VERSION "HNNBNNNYNNNNNNNNNNNNNNNNNNNNNNNNNNNNNNNNNN/4/%%%/4/'%**4NNN///"

NS_ :

BS_:

BU_: BAP_Tester conBox Gateway Gateway_PAG OTA_FC

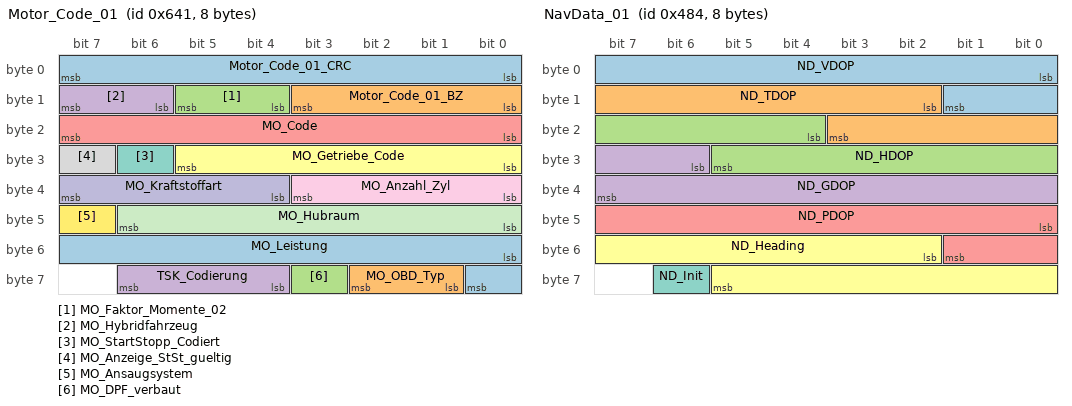
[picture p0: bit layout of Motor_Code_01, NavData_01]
BO_ 1601 Motor_Code_01: 8 Gateway
 SG_ Motor_Code_01_CRC : 0|8@1+ (1,0) [0|255] ""  Vector__XXX
 SG_ Motor_Code_01_BZ : 8|4@1+ (1,0) [0|15] ""  Vector__XXX
 SG_ MO_Faktor_Momente_02 : 12|2@1+ (1,0) [1|3] "Unit_NewtoMeter"  Vector__XXX
 SG_ MO_Hybridfahrzeug : 14|2@1+ (1.0,0.0) [0.0|3] ""  conBox
 SG_ MO_Code : 16|8@1+ (1,0) [0|255] ""  Vector__XXX
 SG_ MO_Getriebe_Code : 24|6@1+ (1.0,0.0) [0.0|63] ""  Vector__XXX
 SG_ MO_StartStopp_Codiert : 30|1@1+ (1.0,0.0) [0.0|1] ""  Vector__XXX
 SG_ MO_Anzeige_StSt_gueltig : 31|1@1+ (1.0,0.0) [0.0|1] ""  Vector__XXX
 SG_ MO_Anzahl_Zyl : 32|4@1+ (1.0,0.0) [0.0|15] ""  Vector__XXX
 SG_ MO_Kraftstoffart : 36|4@1+ (1.0,0.0) [0.0|15] ""  conBox
 SG_ MO_Hubraum : 40|7@1+ (0.1,0) [0.0|12.7] "Unit_Liter"  Vector__XXX
 SG_ MO_Ansaugsystem : 47|1@1+ (1.0,0.0) [0.0|1] ""  Vector__XXX
 SG_ MO_Leistung : 48|9@1+ (1,0) [0|511] "Unit_KiloWatt"  Vector__XXX
 SG_ MO_OBD_Typ : 57|2@1+ (1.0,0.0) [0.0|3] ""  Vector__XXX
 SG_ MO_DPF_verbaut : 59|1@1+ (1.0,0.0) [0.0|1] ""  Vector__XXX
 SG_ TSK_Codierung : 60|3@1+ (1.0,0.0) [0.0|7] ""  Vector__XXX

BO_ 1156 NavData_01: 8 Gateway
 SG_ ND_VDOP : 0|10@1+ (0.025,0) [0.000|25.000] ""  Vector__XXX
 SG_ ND_TDOP : 10|10@1+ (0.025,0) [0.000|25.000] ""  Vector__XXX
 SG_ ND_HDOP : 20|10@1+ (0.025,0) [0.000|25.000] ""  conBox
 SG_ ND_GDOP : 30|10@1+ (0.025,0) [0.000|25.000] ""  Vector__XXX
 SG_ ND_PDOP : 40|10@1+ (0.025,0) [0.000|25.000] ""  Vector__XXX
 SG_ ND_Heading : 50|12@1+ (0.1,0) [0.0|359.9] "Unit_DegreOfArc"  conBox
 SG_ ND_Init : 62|1@1+ (1.0,0.0) [0.0|1] ""  conBox

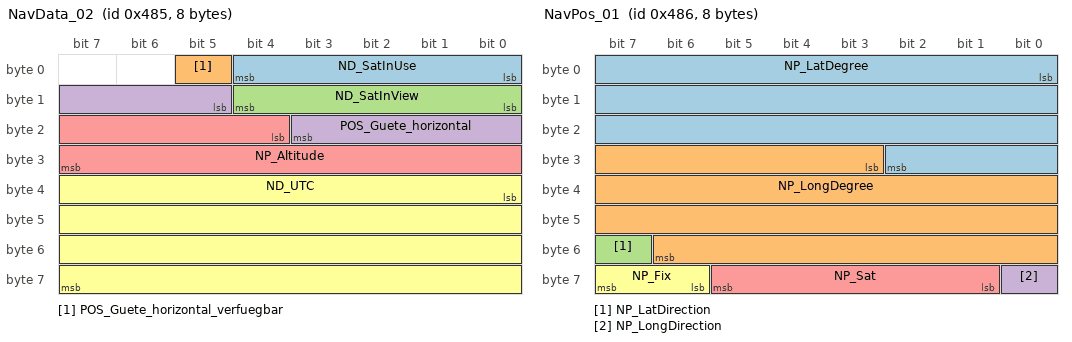
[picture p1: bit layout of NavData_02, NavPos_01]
BO_ 1157 NavData_02: 8 Gateway
 SG_ ND_SatInUse : 0|5@1+ (1,0) [0|29] ""  conBox
 SG_ POS_Guete_horizontal_verfuegbar : 5|1@1+ (1.0,0.0) [0.0|1] ""  conBox
 SG_ ND_SatInView : 8|5@1+ (1,0) [0|29] ""  Vector__XXX
 SG_ POS_Guete_horizontal : 13|7@1+ (2,0) [0|246] "Unit_Meter"  conBox
 SG_ NP_Altitude : 20|12@1+ (2,-500) [-500|7686] "Unit_Meter"  conBox
 SG_ ND_UTC : 32|32@1+ (1,0) [0|4294967293] "Unit_Secon"  conBox

BO_ 1158 NavPos_01: 8 Gateway
 SG_ NP_LatDegree : 0|27@1+ (0.000001,0) [0.000000|90.000000] "Unit_DegreOfArc"  Vector__XXX
 SG_ NP_LongDegree : 27|28@1+ (0.000001,0) [0.000000|180.000000] "Unit_DegreOfArc"  Vector__XXX
 SG_ NP_LatDirection : 55|1@1+ (1.0,0.0) [0.0|1] ""  Vector__XXX
 SG_ NP_LongDirection : 56|1@1+ (1.0,0.0) [0.0|1] ""  Vector__XXX
 SG_ NP_Sat : 57|5@1+ (1,0) [0|29] ""  Vector__XXX
 SG_ NP_Fix : 62|2@1+ (1.0,0.0) [0.0|3] ""  conBox

BO_ 2589283496 NavPos_02_Map_Matched: 8 Gateway
 SG_ POS_MUX M  : 0|2@1+ (1.0,0.0) [0.0|3] ""  conBox
 SG_ POS_ODD_EVEN : 2|1@1+ (1.0,0.0) [0.0|1] ""  conBox
 SG_ POS_PosStati m0  : 3|4@1+ (1.0,0.0) [0.0|15] ""  conBox
 SG_ POS_Heading m1  : 4|12@1+ (0.1,0) [0.0|409.5] "Unit_DegreOfArc"  conBox
 SG_ POS_LatDirection m0  : 7|1@1+ (1.0,0.0) [0.0|1] ""  conBox
 SG_ POS_LatDegree m0  : 8|27@1+ (0.000001,0) [0.000000|90.000000] "Unit_DegreOfArc"  conBox
 SG_ POS_Last_GPS_Sync m1  : 16|14@1+ (1,0) [0|16383] "Unit_Secon"  conBox
 SG_ POS_Heading_Trust m1  : 30|2@1+ (1.0,0.0) [0.0|3] ""  conBox
 SG_ POS_UTC_REF m1  : 32|32@1+ (1,0) [0|4294967295] "Unit_Secon"  conBox
 SG_ POS_LongDirection m0  : 35|1@1+ (1.0,0.0) [0.0|1] ""  conBox
 SG_ POS_LongDegree m0  : 36|28@1+ (0.000001,0) [0.000000|180.000000] "Unit_DegreOfArc"  conBox

BO_ 2600468496 NMH_Gateway: 8 Gateway
 SG_ NM_Gateway_SNI : 0|8@1+ (1.0,0.0) [0.0|255] ""  conBox,OTA_FC
 SG_ NM_Gateway_CBV_AWB : 12|1@1+ (1.0,0.0) [0.0|1] ""  Vector__XXX
 SG_ NM_Gateway_CBV_CRI : 14|1@1+ (1.0,0.0) [0.0|1] ""  conBox,OTA_FC
 SG_ NM_Gateway_NM_State : 16|6@1+ (1.0,0.0) [0.0|63] ""  Vector__XXX
 SG_ NM_Gateway_Car_Wakeup : 22|1@1+ (1.0,0.0) [0.0|1] ""  Vector__XXX
 SG_ NM_Gateway_UDS_CC : 23|1@1+ (1.0,0.0) [0.0|1] ""  Vector__XXX
 SG_ NM_Gateway_NM_aktiv_KL15 : 24|1@1+ (1.0,0.0) [0.0|1] ""  Vector__XXX
 SG_ NM_Gateway_NM_aktiv_Diagnose : 25|1@1+ (1.0,0.0) [0.0|1] ""  Vector__XXX
 SG_ NM_Gateway_NM_aktiv_Tmin : 26|1@1+ (1.0,0.0) [0.0|1] ""  Vector__XXX
 SG_ NM_Gateway_NM_aktiv_CWU : 27|1@1+ (1.0,0.0) [0.0|1] ""  Vector__XXX
 SG_ NM_Gateway_NM_aktiv_FC : 28|1@1+ (1.0,0.0) [0.0|1] ""  Vector__XXX
 SG_ NM_Gateway_NM_aktiv_Connect : 29|1@1+ (1.0,0.0) [0.0|1] ""  Vector__XXX
 SG_ NM_Gateway_NM_aktiv_EM : 30|1@1+ (1.0,0.0) [0.0|1] ""  Vector__XXX
 SG_ NM_Gateway_NM_aktiv_OBDC : 31|1@1+ (1.0,0.0) [0.0|1] ""  Vector__XXX
 SG_ NM_Gateway_NM_aktiv_Buskopplung : 32|1@1+ (1.0,0.0) [0.0|1] ""  Vector__XXX
 SG_ NM_Gateway_NM_aktiv_LIN2 : 33|1@1+ (1.0,0.0) [0.0|1] ""  Vector__XXX
 SG_ NM_Gateway_NM_aktiv_Fremdladung : 34|1@1+ (1.0,0.0) [0.0|1] ""  Vector__XXX
 SG_ NM_Gateway_CAB : 40|24@1+ (1.0,0.0) [0.0|16777215] ""  conBox,OTA_FC

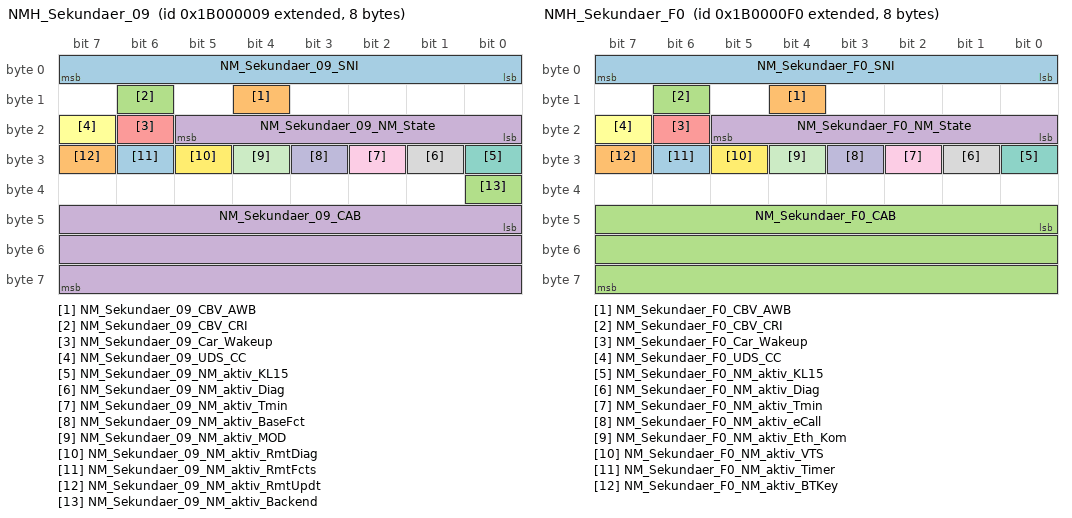
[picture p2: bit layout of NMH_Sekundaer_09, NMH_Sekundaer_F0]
BO_ 2600468489 NMH_Sekundaer_09: 8 OTA_FC
 SG_ NM_Sekundaer_09_SNI : 0|8@1+ (1.0,0.0) [0.0|255] ""  conBox,Gateway,Gateway_PAG
 SG_ NM_Sekundaer_09_CBV_AWB : 12|1@1+ (1.0,0.0) [0.0|1] ""  Vector__XXX
 SG_ NM_Sekundaer_09_CBV_CRI : 14|1@1+ (1.0,0.0) [0.0|1] ""  conBox,Gateway,Gateway_PAG
 SG_ NM_Sekundaer_09_NM_State : 16|6@1+ (1.0,0.0) [0.0|63] ""  Vector__XXX
 SG_ NM_Sekundaer_09_Car_Wakeup : 22|1@1+ (1.0,0.0) [0.0|1] ""  Vector__XXX
 SG_ NM_Sekundaer_09_UDS_CC : 23|1@1+ (1.0,0.0) [0.0|1] ""  Vector__XXX
 SG_ NM_Sekundaer_09_NM_aktiv_KL15 : 24|1@1+ (1.0,0.0) [0.0|1] ""  Vector__XXX
 SG_ NM_Sekundaer_09_NM_aktiv_Diag : 25|1@1+ (1.0,0.0) [0.0|1] ""  Vector__XXX
 SG_ NM_Sekundaer_09_NM_aktiv_Tmin : 26|1@1+ (1.0,0.0) [0.0|1] ""  Vector__XXX
 SG_ NM_Sekundaer_09_NM_aktiv_BaseFct : 27|1@1+ (1.0,0.0) [0.0|1] ""  Vector__XXX
 SG_ NM_Sekundaer_09_NM_aktiv_MOD : 28|1@1+ (1.0,0.0) [0.0|1] ""  Vector__XXX
 SG_ NM_Sekundaer_09_NM_aktiv_RmtDiag : 29|1@1+ (1.0,0.0) [0.0|1] ""  Vector__XXX
 SG_ NM_Sekundaer_09_NM_aktiv_RmtFcts : 30|1@1+ (1.0,0.0) [0.0|1] ""  Vector__XXX
 SG_ NM_Sekundaer_09_NM_aktiv_RmtUpdt : 31|1@1+ (1.0,0.0) [0.0|1] ""  Vector__XXX
 SG_ NM_Sekundaer_09_NM_aktiv_Backend : 32|1@1+ (1.0,0.0) [0.0|1] ""  Vector__XXX
 SG_ NM_Sekundaer_09_CAB : 40|24@1+ (1.0,0.0) [0.0|16777215] ""  conBox,Gateway,Gateway_PAG

BO_ 2600468720 NMH_Sekundaer_F0: 8 conBox
 SG_ NM_Sekundaer_F0_SNI : 0|8@1+ (1.0,0.0) [0.0|255] ""  Gateway,Gateway_PAG,OTA_FC
 SG_ NM_Sekundaer_F0_CBV_AWB : 12|1@1+ (1.0,0.0) [0.0|1] ""  Gateway,Gateway_PAG
 SG_ NM_Sekundaer_F0_CBV_CRI : 14|1@1+ (1.0,0.0) [0.0|1] ""  Gateway,Gateway_PAG,OTA_FC
 SG_ NM_Sekundaer_F0_NM_State : 16|6@1+ (1.0,0.0) [0.0|63] ""  Gateway
 SG_ NM_Sekundaer_F0_Car_Wakeup : 22|1@1+ (1.0,0.0) [0.0|1] ""  Vector__XXX
 SG_ NM_Sekundaer_F0_UDS_CC : 23|1@1+ (1.0,0.0) [0.0|1] ""  Vector__XXX
 SG_ NM_Sekundaer_F0_NM_aktiv_KL15 : 24|1@1+ (1.0,0.0) [0.0|1] ""  Vector__XXX
 SG_ NM_Sekundaer_F0_NM_aktiv_Diag : 25|1@1+ (1.0,0.0) [0.0|1] ""  Vector__XXX
 SG_ NM_Sekundaer_F0_NM_aktiv_Tmin : 26|1@1+ (1.0,0.0) [0.0|1] ""  Vector__XXX
 SG_ NM_Sekundaer_F0_NM_aktiv_eCall : 27|1@1+ (1.0,0.0) [0.0|1] ""  Vector__XXX
 SG_ NM_Sekundaer_F0_NM_aktiv_Eth_Kom : 28|1@1+ (1.0,0.0) [0.0|1] ""  Vector__XXX
 SG_ NM_Sekundaer_F0_NM_aktiv_VTS : 29|1@1+ (1.0,0.0) [0.0|1] ""  Vector__XXX
 SG_ NM_Sekundaer_F0_NM_aktiv_Timer : 30|1@1+ (1.0,0.0) [0.0|1] ""  Vector__XXX
 SG_ NM_Sekundaer_F0_NM_aktiv_BTKey : 31|1@1+ (1.0,0.0) [0.0|1] ""  Vector__XXX
 SG_ NM_Sekundaer_F0_CAB : 40|24@1+ (1.0,0.0) [0.0|16777215] ""  Gateway,Gateway_PAG,OTA_FC

BO_ 1635 NVEM_02: 8 Gateway
 SG_ BEM_02_Abschaltstufen : 0|3@1+ (1.0,0.0) [0.0|7] ""  conBox
 SG_ BEM_STH_Zielzeit : 3|4@1+ (5,0) [0|60] "Unit_Minut"  Vector__XXX
 SG_ BEM_MMI_Vorwarnung : 7|1@1+ (1.0,0.0) [0.0|1] ""  Vector__XXX
 SG_ NVEM_Anf_SD_schalten : 15|1@1+ (1.0,0.0) [0.0|1] ""  Vector__XXX
 SG_ BEM_Generatordiagnose : 16|2@1+ (1.0,0.0) [0.0|3] ""  Vector__XXX
 SG_ BEM_Red_Innengeblaese : 18|2@1+ (1.0,0.0) [0.0|3] ""  Vector__XXX
 SG_ BEM_STH_Einschaltverbot : 20|1@1+ (1.0,0.0) [0.0|1] ""  Vector__XXX
 SG_ BEM_HL_Regelung_Status : 21|3@1+ (1.0,0.0) [0.0|7] ""  Vector__XXX
 SG_ BEM_Ladezustand : 24|4@1+ (10,0) [0|100] "Unit_PerCent"  Vector__XXX
 SG_ BEM_Batteriediagnose : 28|3@1+ (1.0,0.0) [0.0|7] ""  Vector__XXX
 SG_ MIB_Stromsparmodus : 31|1@1+ (1.0,0.0) [0.0|1] ""  Vector__XXX
 SG_ BEM_REK_aktiv : 37|1@1+ (1.0,0.0) [0.0|1] ""  Vector__XXX
 SG_ NVEM_Last_Anf : 38|2@1+ (1.0,0.0) [0.0|3] ""  Vector__XXX
 SG_ BEM_UBDM : 40|8@1+ (0.05,5) [5.05|17.70] "Unit_Volt"  Vector__XXX
 SG_ BEM_UGenSoll : 48|6@1+ (0.1,10.6) [10.6|16.0] "Unit_Volt"  Vector__XXX
 SG_ BEM_Anf_KL15_schalten : 54|2@1+ (1.0,0.0) [0.0|3] ""  Vector__XXX
 SG_ NVEM_Batterie_Service : 56|2@1+ (1.0,0.0) [0.0|3] ""  Vector__XXX
 SG_ NVEM_Freigabe_OnlineUpdate : 58|1@1+ (1.0,0.0) [0.0|1] ""  Vector__XXX
 SG_ NVEM_Freigabe_ORU4 : 59|2@1+ (1.0,0.0) [0.0|3] ""  Vector__XXX

BO_ 2589283656 ORU_01: 8 Gateway
 SG_ ORU_Warnung : 58|2@1+ (1.0,0.0) [0.0|3] ""  Vector__XXX
 SG_ ORU_Status : 61|3@1+ (1.0,0.0) [0.0|7] ""  conBox,OTA_FC

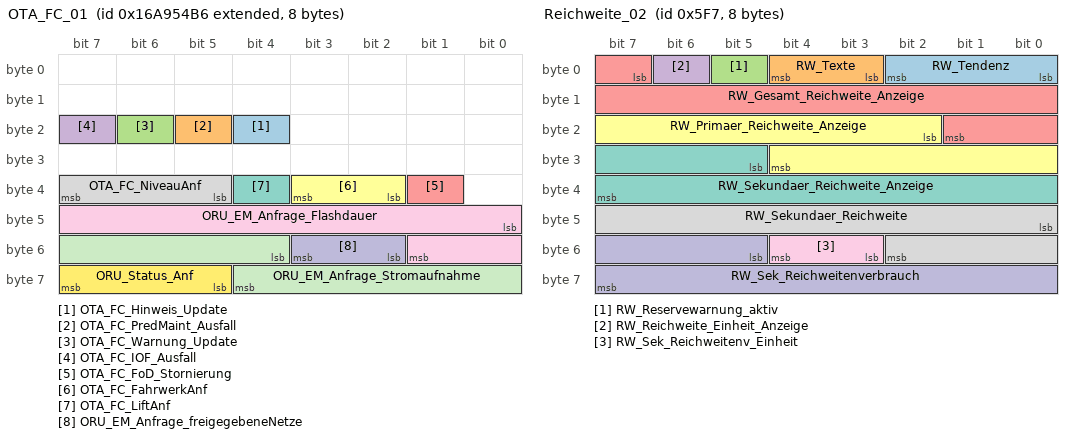
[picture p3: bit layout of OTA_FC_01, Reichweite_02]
BO_ 2527679670 OTA_FC_01: 8 OTA_FC
 SG_ OTA_FC_Hinweis_Update : 20|1@1+ (1.0,0.0) [0.0|1] ""  Gateway,Gateway_PAG
 SG_ OTA_FC_PredMaint_Ausfall : 21|1@1+ (1.0,0.0) [0.0|1] ""  Gateway,Gateway_PAG
 SG_ OTA_FC_Warnung_Update : 22|1@1+ (1.0,0.0) [0.0|1] ""  Gateway,Gateway_PAG
 SG_ OTA_FC_IOF_Ausfall : 23|1@1+ (1.0,0.0) [0.0|1] ""  Gateway,Gateway_PAG
 SG_ OTA_FC_FoD_Stornierung : 33|1@1+ (1.0,0.0) [0.0|1] ""  Gateway,Gateway_PAG
 SG_ OTA_FC_FahrwerkAnf : 34|2@1+ (1.0,0.0) [0.0|3] ""  Gateway,Gateway_PAG
 SG_ OTA_FC_LiftAnf : 36|1@1+ (1.0,0.0) [0.0|1] ""  Gateway,Gateway_PAG
 SG_ OTA_FC_NiveauAnf : 37|3@1+ (1.0,0.0) [0.0|7] ""  Gateway,Gateway_PAG
 SG_ ORU_EM_Anfrage_Flashdauer : 40|10@1+ (10,0) [0|10230] "Unit_Secon"  Gateway,Gateway_PAG
 SG_ ORU_EM_Anfrage_freigegebeneNetze : 50|2@1+ (1.0,0.0) [0.0|3] ""  Gateway,Gateway_PAG
 SG_ ORU_EM_Anfrage_Stromaufnahme : 52|9@1+ (0.1,0) [0.0|51.1] "Unit_Amper"  Gateway,Gateway_PAG
 SG_ ORU_Status_Anf : 61|3@1+ (1.0,0.0) [0.0|7] ""  Gateway,Gateway_PAG

BO_ 2463978757 Personalisierung_04: 8 conBox
 SG_ PSO_last_rec_UserID_Src2 : 60|4@1+ (1.0,0.0) [0.0|15] ""  Gateway,Gateway_PAG

BO_ 1122 PSD_04: 8 Gateway
 SG_ PSD_Segment_ID : 0|6@1+ (1,0) [2|63] ""  Vector__XXX
 SG_ PSD_Vorgaenger_Segment_ID : 6|6@1+ (1,0) [2|63] ""  Vector__XXX
 SG_ PSD_Segmentlaenge : 12|7@1+ (2,0) [0|254] "Unit_Meter"  Vector__XXX
 SG_ PSD_Strassenkategorie : 19|3@1+ (1.0,0.0) [0.0|7] ""  conBox
 SG_ PSD_Endkruemmung : 22|8@1+ (1,0) [0|254] "Unit_None"  Vector__XXX
 SG_ PSD_Endkruemmung_Vorz : 30|1@1+ (1.0,0.0) [0.0|1] ""  Vector__XXX
 SG_ PSD_Idenditaets_ID : 31|6@1+ (1,0) [2|63] ""  Vector__XXX
 SG_ PSD_ADAS_Qualitaet : 37|1@1+ (1.0,0.0) [0.0|1] ""  Vector__XXX
 SG_ PSD_wahrscheinlichster_Pfad : 38|1@1+ (1.0,0.0) [0.0|1] ""  Vector__XXX
 SG_ PSD_Geradester_Pfad : 39|1@1+ (1.0,0.0) [0.0|1] ""  Vector__XXX
 SG_ PSD_Fahrspuren_Anzahl : 40|3@1+ (1.0,0.0) [0.0|7] ""  Vector__XXX
 SG_ PSD_Bebauung : 43|1@1+ (1.0,0.0) [0.0|1] ""  Vector__XXX
 SG_ PSD_Segment_Komplett : 44|1@1+ (1.0,0.0) [0.0|1] ""  Vector__XXX
 SG_ PSD_Rampe : 45|2@1+ (1.0,0.0) [0.0|3] ""  Vector__XXX
 SG_ PSD_Anfangskruemmung : 47|8@1+ (1,0) [0|254] ""  Vector__XXX
 SG_ PSD_Anfangskruemmung_Vorz : 55|1@1+ (1.0,0.0) [0.0|1] ""  Vector__XXX
 SG_ PSD_Abzweigerichtung : 56|1@1+ (1.0,0.0) [0.0|1] ""  Vector__XXX
 SG_ PSD_Abzweigewinkel : 57|7@1+ (1.417323,0) [0.000000|180.000021] ""  Vector__XXX

BO_ 1527 Reichweite_02: 8 Gateway
 SG_ RW_Tendenz : 0|3@1+ (1.0,0.0) [0.0|7] ""  OTA_FC
 SG_ RW_Texte : 3|2@1+ (1.0,0.0) [0.0|3] ""  Vector__XXX
 SG_ RW_Reservewarnung_aktiv : 5|1@1+ (1.0,0.0) [0.0|1] ""  OTA_FC
 SG_ RW_Reichweite_Einheit_Anzeige : 6|1@1+ (1.0,0.0) [0.0|1] ""  conBox
 SG_ RW_Gesamt_Reichweite_Anzeige : 7|11@1+ (1,0) [0|2044] "Unit_None"  conBox,OTA_FC
 SG_ RW_Primaer_Reichweite_Anzeige : 18|11@1+ (1,0) [0|2044] "Unit_None"  conBox,OTA_FC
 SG_ RW_Sekundaer_Reichweite_Anzeige : 29|11@1+ (1,0) [0|2044] "Unit_None"  conBox,OTA_FC
 SG_ RW_Sekundaer_Reichweite : 40|11@1+ (1,0) [0|2044] "Unit_KiloMeter"  conBox,OTA_FC
 SG_ RW_Sek_Reichweitenv_Einheit : 51|2@1+ (1.0,0.0) [0.0|3] ""  Vector__XXX
 SG_ RW_Sek_Reichweitenverbrauch : 53|11@1+ (0.1,0) [0.0|204.4] "Unit_None"  OTA_FC

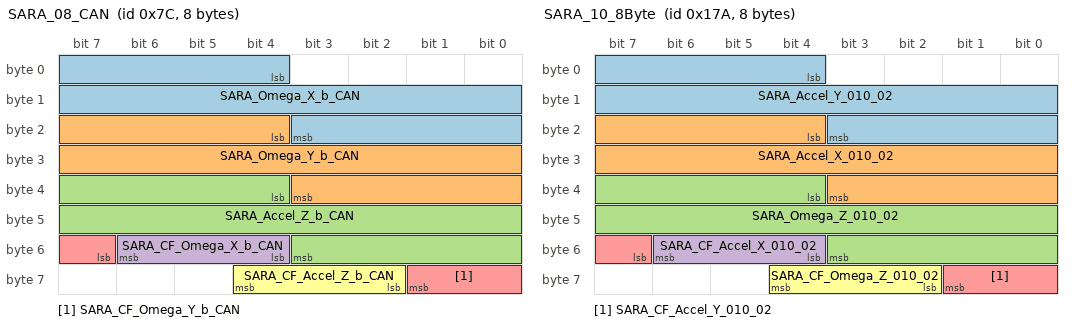
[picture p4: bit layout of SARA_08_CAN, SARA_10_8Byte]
BO_ 124 SARA_08_CAN: 8 Gateway
 SG_ SARA_Omega_X_b_CAN : 4|16@1+ (0.01,-327.68) [-327.67|327.66] "Unit_DegreOfArcPerSecon"  conBox
 SG_ SARA_Omega_Y_b_CAN : 20|16@1+ (0.01,-327.68) [-327.67|327.66] "Unit_DegreOfArcPerSecon"  conBox
 SG_ SARA_Accel_Z_b_CAN : 36|16@1+ (0.02,-655.36) [-655.34|655.32] "Unit_MeterPerSeconSquar"  conBox
 SG_ SARA_CF_Omega_X_b_CAN : 52|3@1+ (1.0,0.0) [0.0|7] ""  Vector__XXX
 SG_ SARA_CF_Omega_Y_b_CAN : 55|3@1+ (1.0,0.0) [0.0|7] ""  Vector__XXX
 SG_ SARA_CF_Accel_Z_b_CAN : 58|3@1+ (1.0,0.0) [0.0|7] ""  conBox

BO_ 378 SARA_10_8Byte: 8 Gateway
 SG_ SARA_Accel_Y_010_02 : 4|16@1+ (0.02,-655.36) [-655.34|655.32] "Unit_MeterPerSeconSquar"  conBox
 SG_ SARA_Accel_X_010_02 : 20|16@1+ (0.02,-655.36) [-655.34|655.32] "Unit_MeterPerSeconSquar"  conBox
 SG_ SARA_Omega_Z_010_02 : 36|16@1+ (0.01,-327.68) [-327.67|327.66] "Unit_DegreOfArcPerSecon"  conBox
 SG_ SARA_CF_Accel_X_010_02 : 52|3@1+ (1.0,0.0) [0.0|7] ""  conBox
 SG_ SARA_CF_Accel_Y_010_02 : 55|3@1+ (1.0,0.0) [0.0|7] ""  conBox
 SG_ SARA_CF_Omega_Z_010_02 : 58|3@1+ (1.0,0.0) [0.0|7] ""  Vector__XXX

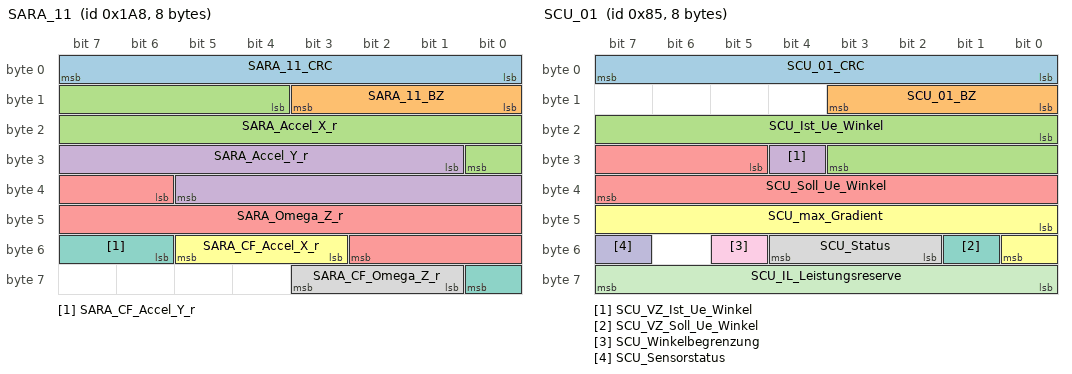
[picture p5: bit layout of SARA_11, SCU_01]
BO_ 424 SARA_11: 8 Gateway
 SG_ SARA_11_CRC : 0|8@1+ (1,0) [0|255] ""  Vector__XXX
 SG_ SARA_11_BZ : 8|4@1+ (1,0) [0|15] ""  Vector__XXX
 SG_ SARA_Accel_X_r : 12|13@1+ (0.16,-655.36) [-655.20|655.04] "Unit_MeterPerSeconSquar"  conBox
 SG_ SARA_Accel_Y_r : 25|13@1+ (0.16,-655.36) [-655.20|655.04] "Unit_MeterPerSeconSquar"  conBox
 SG_ SARA_Omega_Z_r : 38|13@1+ (0.08,-327.68) [-327.60|327.52] "Unit_DegreOfArcPerSecon"  conBox
 SG_ SARA_CF_Accel_X_r : 51|3@1+ (1.0,0.0) [0.0|7] ""  conBox
 SG_ SARA_CF_Accel_Y_r : 54|3@1+ (1.0,0.0) [0.0|7] ""  conBox
 SG_ SARA_CF_Omega_Z_r : 57|3@1+ (1.0,0.0) [0.0|7] ""  conBox

BO_ 133 SCU_01: 8 Gateway
 SG_ SCU_01_CRC : 0|8@1+ (1,0) [0|255] ""  Vector__XXX
 SG_ SCU_01_BZ : 8|4@1+ (1,0) [0|15] ""  Vector__XXX
 SG_ SCU_Ist_Ue_Winkel : 16|12@1+ (0.1,0) [0.0|409.3] "Unit_DegreOfArc"  conBox
 SG_ SCU_VZ_Ist_Ue_Winkel : 28|1@1+ (1.0,0.0) [0.0|1] ""  conBox
 SG_ SCU_Soll_Ue_Winkel : 29|11@1+ (0.1,0) [0.0|204.5] "Unit_DegreOfArc"  Vector__XXX
 SG_ SCU_max_Gradient : 40|9@1+ (1,0) [0|510] ""  Vector__XXX
 SG_ SCU_VZ_Soll_Ue_Winkel : 49|1@1+ (1.0,0.0) [0.0|1] ""  Vector__XXX
 SG_ SCU_Status : 50|3@1+ (1.0,0.0) [0.0|7] ""  Vector__XXX
 SG_ SCU_Winkelbegrenzung : 53|1@1+ (1.0,0.0) [0.0|1] ""  Vector__XXX
 SG_ SCU_Sensorstatus : 55|1@1+ (1.0,0.0) [0.0|1] ""  Vector__XXX
 SG_ SCU_IL_Leistungsreserve : 56|8@1+ (5,0) [0|1265] "Unit_DegreOfArcPerSecon"  Vector__XXX

BO_ 2589283634 SM_LAPP_01: 8 conBox
 SG_ SM_LAPP_Demo_Distanz_01 : 0|8@1+ (2,0) [0|500] "Unit_Meter"  Gateway,Gateway_PAG
 SG_ SM_LAPP_Demo_Distanz_02 : 8|8@1+ (2,0) [0|500] "Unit_Meter"  Gateway,Gateway_PAG
 SG_ SM_LAPP_Demo_Winkel_Vert_01 : 16|8@1+ (0.1,-12.8) [-12.8|12.7] "Unit_DegreOfArc"  Gateway,Gateway_PAG
 SG_ SM_LAPP_Demo_Winkel_Vert_02 : 24|8@1+ (0.1,-12.8) [-12.8|12.7] "Unit_DegreOfArc"  Gateway,Gateway_PAG
 SG_ SM_LAPP_Demo_Winkel_Hor_01 : 32|10@1+ (0.0625,-32) [-32.0000|31.9375] "Unit_DegreOfArc"  Gateway,Gateway_PAG
 SG_ SM_LAPP_Demo_Winkel_Hor_02 : 42|10@1+ (0.0625,-32) [-32.0000|31.9375] "Unit_DegreOfArc"  Gateway,Gateway_PAG
 SG_ SM_LAPP_Demo_Objekt_01_Anf : 52|1@1+ (1.0,0.0) [0.0|1] ""  Gateway,Gateway_PAG
 SG_ SM_LAPP_Demo_Objekt_02_Anf : 53|1@1+ (1.0,0.0) [0.0|1] ""  Gateway,Gateway_PAG
 SG_ SM_LAPP_Demo_Autobahnmodus_Anf : 54|1@1+ (1.0,0.0) [0.0|1] ""  Gateway,Gateway_PAG
 SG_ SM_LAPP_Aussenlicht_aktiv : 55|1@1+ (1.0,0.0) [0.0|1] ""  Gateway,Gateway_PAG
 SG_ SM_LAPP_Verbindungsstatus : 56|1@1+ (1.0,0.0) [0.0|1] ""  Gateway,Gateway_PAG
 SG_ SM_LAPP_Demo_Schildentbl_01_Anf : 57|1@1+ (1.0,0.0) [0.0|1] ""  Gateway,Gateway_PAG
 SG_ SM_LAPP_Demo_Schildentbl_02_Anf : 58|1@1+ (1.0,0.0) [0.0|1] ""  Gateway,Gateway_PAG
 SG_ SM_LAPP_Demo_DKL_Anf : 59|1@1+ (1.0,0.0) [0.0|1] ""  Gateway,Gateway_PAG
 SG_ SM_LAPP_Demo_Einschalteffekt_Anf : 60|1@1+ (1.0,0.0) [0.0|1] ""  Gateway,Gateway_PAG
 SG_ SM_LAPP_Demo_FL_Anf : 61|1@1+ (1.0,0.0) [0.0|1] ""  Gateway,Gateway_PAG
 SG_ SM_LAPP_Demo_MaLi_Anf : 62|1@1+ (1.0,0.0) [0.0|1] ""  Gateway,Gateway_PAG
 SG_ SM_LAPP_Demo_ABBL_Anf : 63|1@1+ (1.0,0.0) [0.0|1] ""  Gateway,Gateway_PAG

BO_ 2527679657 SM_LAPP_02: 8 conBox
 SG_ SM_LAPP_Demo_AbsAss_Anf : 12|1@1+ (1.0,0.0) [0.0|1] ""  Gateway,Gateway_PAG
 SG_ SM_LAPP_Demo_SL_Signatur_Anf : 28|4@1+ (1.0,0.0) [0.0|15] ""  Gateway,Gateway_PAG
 SG_ SM_LAPP_Demo_Variante : 32|4@1+ (1.0,0.0) [0.0|15] ""  Gateway,Gateway_PAG
 SG_ SM_LAPP_Demo_RouLi_Anf : 36|1@1+ (1.0,0.0) [0.0|1] ""  Gateway,Gateway_PAG
 SG_ SM_LAPP_Demo_PreSAss_Anf : 37|1@1+ (1.0,0.0) [0.0|1] ""  Gateway,Gateway_PAG
 SG_ SM_LAPP_Demo_advLH_F01_Anf : 38|1@1+ (1.0,0.0) [0.0|1] ""  Gateway,Gateway_PAG
 SG_ SM_LAPP_Demo_AbbiegeWa_Anf : 39|1@1+ (1.0,0.0) [0.0|1] ""  Gateway,Gateway_PAG
 SG_ SM_LAPP_Demo_CH_H01_Anf : 40|1@1+ (1.0,0.0) [0.0|1] ""  Gateway,Gateway_PAG
 SG_ SM_LAPP_Demo_Stufe : 41|2@1+ (1.0,0.0) [0.0|3] ""  Gateway,Gateway_PAG
 SG_ SM_LAPP_Demo_SL_Anf : 44|1@1+ (1.0,0.0) [0.0|1] ""  Gateway,Gateway_PAG
 SG_ SM_LAPP_Demo_SitLi_Anf : 45|1@1+ (1.0,0.0) [0.0|1] ""  Gateway,Gateway_PAG
 SG_ SM_LAPP_Demo_BauLi_Anf : 46|1@1+ (1.0,0.0) [0.0|1] ""  Gateway,Gateway_PAG
 SG_ SM_LAPP_Demo_advCH_F01_Anf : 47|1@1+ (1.0,0.0) [0.0|1] ""  Gateway,Gateway_PAG
 SG_ SM_LAPP_Demo_LH_F01_Anf : 48|5@1+ (1,0) [1|31] "Unit_None"  Gateway,Gateway_PAG
 SG_ SM_LAPP_Demo_AccAss_Anf : 53|1@1+ (1.0,0.0) [0.0|1] ""  Gateway,Gateway_PAG
 SG_ SM_LAPP_Demo_SpuLi_Anf : 54|1@1+ (1.0,0.0) [0.0|1] ""  Gateway,Gateway_PAG
 SG_ SM_LAPP_Demo_TraLi_Anf : 55|1@1+ (1.0,0.0) [0.0|1] ""  Gateway,Gateway_PAG
 SG_ SM_LAPP_Demo_CH_F01_Anf : 56|5@1+ (1,0) [1|31] "Unit_None"  Gateway,Gateway_PAG
 SG_ SM_LAPP_Demo_LH_H01_Anf : 61|1@1+ (1.0,0.0) [0.0|1] ""  Gateway,Gateway_PAG
 SG_ SM_LAPP_Demo_EffAss_Anf : 62|1@1+ (1.0,0.0) [0.0|1] ""  Gateway,Gateway_PAG
 SG_ SM_LAPP_Demo_BeAss_Anf : 63|1@1+ (1.0,0.0) [0.0|1] ""  Gateway,Gateway_PAG

BO_ 2463978662 STS2_01: 8 Gateway
 SG_ STS2_01_CRC : 0|8@1+ (1,0) [0|255] ""  conBox
 SG_ STS2_01_BZ : 8|4@1+ (1,0) [0|15] ""  conBox
 SG_ STS2_Car_not_under_theft : 12|1@1+ (1.0,0.0) [0.0|1] ""  conBox
 SG_ STS2_Car_under_theft : 13|1@1+ (1.0,0.0) [0.0|1] ""  conBox
 SG_ STS2_Door_Lock : 14|1@1+ (1.0,0.0) [0.0|1] ""  conBox
 SG_ STS2_Anlassersperre : 15|1@1+ (1.0,0.0) [0.0|1] ""  conBox
 SG_ STS2_Typencodierung : 16|5@1+ (1.0,0.0) [0.0|31] ""  conBox
 SG_ STS2_Spiegel_Anklappen : 21|1@1+ (1.0,0.0) [0.0|1] ""  conBox
 SG_ STS2_Privatsphaere : 22|1@1+ (1.0,0.0) [0.0|1] ""  Vector__XXX
 SG_ STS2_Standlicht : 24|1@1+ (1.0,0.0) [0.0|1] ""  conBox
 SG_ STS2_Fahrlicht : 25|1@1+ (1.0,0.0) [0.0|1] ""  conBox
 SG_ STS2_Alarm_still : 26|1@1+ (1.0,0.0) [0.0|1] ""  conBox
 SG_ STS2_Texte : 27|4@1+ (1.0,0.0) [0.0|15] ""  conBox
 SG_ STS2_Laderelais : 38|1@1+ (1.0,0.0) [0.0|1] ""  conBox
 SG_ STS2_Summer : 48|1@1+ (1.0,0.0) [0.0|1] ""  conBox
 SG_ STS2_Alarm_Blinker : 50|1@1+ (1.0,0.0) [0.0|1] ""  conBox
 SG_ STS2_Notstart : 51|1@1+ (1.0,0.0) [0.0|1] ""  conBox
 SG_ STS2_Signalhorn : 55|1@1+ (1.0,0.0) [0.0|1] ""  conBox
 SG_ STS2_Leerlaufschaltung : 56|1@1+ (1.0,0.0) [0.0|1] ""  conBox

BO_ 1172 STS_01: 8 conBox
 SG_ STS_01_CRC : 0|8@1+ (1,0) [0|255] ""  Gateway,Gateway_PAG
 SG_ STS_01_BZ : 8|4@1+ (1,0) [0|15] ""  Gateway,Gateway_PAG
 SG_ STS_Car_not_under_theft : 12|1@1+ (1.0,0.0) [0.0|1] ""  Gateway,Gateway_PAG
 SG_ STS_Car_under_theft : 13|1@1+ (1.0,0.0) [0.0|1] ""  Gateway,Gateway_PAG
 SG_ STS_Door_Lock : 14|1@1+ (1.0,0.0) [0.0|1] ""  Gateway,Gateway_PAG
 SG_ STS_Anlassersperre : 15|1@1+ (1.0,0.0) [0.0|1] ""  Gateway,Gateway_PAG
 SG_ STS_Typencodierung : 16|5@1+ (1.0,0.0) [0.0|31] ""  Gateway,Gateway_PAG
 SG_ STS_Spiegel_Anklappen : 21|1@1+ (1.0,0.0) [0.0|1] ""  Gateway,Gateway_PAG
 SG_ GW_STS2_Privatsphaere : 22|1@1+ (1.0,0.0) [0.0|1] ""  Gateway,Gateway_PAG
 SG_ STS_LIN_aktiv : 23|1@1+ (1.0,0.0) [0.0|1] ""  Gateway,Gateway_PAG
 SG_ STS_Standlicht : 24|1@1+ (1.0,0.0) [0.0|1] ""  Gateway,Gateway_PAG
 SG_ STS_Fahrlicht : 25|1@1+ (1.0,0.0) [0.0|1] ""  Gateway,Gateway_PAG
 SG_ STS_Alarm_still : 26|1@1+ (1.0,0.0) [0.0|1] ""  Gateway,Gateway_PAG
 SG_ STS_Texte : 27|4@1+ (1.0,0.0) [0.0|15] ""  Gateway,Gateway_PAG
 SG_ STS_Laderelais : 38|1@1+ (1.0,0.0) [0.0|1] ""  Gateway,Gateway_PAG
 SG_ STS_Summer : 48|1@1+ (1.0,0.0) [0.0|1] ""  Gateway,Gateway_PAG
 SG_ STS_Alarm_Blinker : 50|1@1+ (1.0,0.0) [0.0|1] ""  Gateway,Gateway_PAG
 SG_ STS_Notstart : 51|1@1+ (1.0,0.0) [0.0|1] ""  Gateway,Gateway_PAG
 SG_ STS_Signalhorn : 55|1@1+ (1.0,0.0) [0.0|1] ""  Gateway,Gateway_PAG
 SG_ STS_Leerlaufschaltung : 56|1@1+ (1.0,0.0) [0.0|1] ""  Gateway,Gateway_PAG

BO_ 1413 Systeminfo_01: 8 Gateway
 SG_ SI_Sammel_SG_Fehler : 0|6@1+ (1,0) [0|60] ""  OTA_FC
 SG_ SI_Diagnose_Aktiv : 7|1@1+ (1.0,0.0) [0.0|1] ""  Vector__XXX
 SG_ SI_QRS_Mode : 8|1@1+ (1.0,0.0) [0.0|1] ""  conBox,OTA_FC
 SG_ SI_T_Mode : 9|1@1+ (1.0,0.0) [0.0|1] ""  conBox,OTA_FC
 SG_ SI_NWDF : 10|1@1+ (1.0,0.0) [0.0|1] ""  conBox,OTA_FC
 SG_ SI_NWDF_gueltig : 11|1@1+ (1.0,0.0) [0.0|1] ""  conBox,OTA_FC
 SG_ SI_Sammelfehler : 12|1@1+ (1.0,0.0) [0.0|1] ""  OTA_FC
 SG_ GW_KD_Fehler : 13|1@1+ (1.0,0.0) [0.0|1] ""  Vector__XXX
 SG_ SI_T_Schutz : 14|1@1+ (1.0,0.0) [0.0|1] ""  conBox,OTA_FC
 SG_ SI_BUS_01 : 16|1@1+ (1.0,0.0) [0.0|1] ""  Vector__XXX
 SG_ SI_BUS_02 : 17|1@1+ (1.0,0.0) [0.0|1] ""  Vector__XXX
 SG_ SI_BUS_03 : 18|1@1+ (1.0,0.0) [0.0|1] ""  conBox
 SG_ SI_BUS_04 : 19|1@1+ (1.0,0.0) [0.0|1] ""  conBox
 SG_ SI_BUS_05 : 20|1@1+ (1.0,0.0) [0.0|1] ""  Vector__XXX
 SG_ SI_BUS_06 : 21|1@1+ (1.0,0.0) [0.0|1] ""  Vector__XXX
 SG_ SI_BUS_07 : 22|1@1+ (1.0,0.0) [0.0|1] ""  Vector__XXX
 SG_ SI_BUS_08 : 23|1@1+ (1.0,0.0) [0.0|1] ""  Vector__XXX
 SG_ SI_BUS_09 : 24|1@1+ (1.0,0.0) [0.0|1] ""  Vector__XXX
 SG_ SI_BUS_10 : 25|1@1+ (1.0,0.0) [0.0|1] ""  conBox
 SG_ SI_BUS_11 : 26|1@1+ (1.0,0.0) [0.0|1] ""  Vector__XXX
 SG_ SI_BUS_12 : 27|1@1+ (1.0,0.0) [0.0|1] ""  conBox
 SG_ SI_BUS_13 : 28|1@1+ (1.0,0.0) [0.0|1] ""  conBox
 SG_ SI_BUS_14 : 29|1@1+ (1.0,0.0) [0.0|1] ""  Vector__XXX
 SG_ SI_BUS_15 : 30|1@1+ (1.0,0.0) [0.0|1] ""  Vector__XXX
 SG_ SI_Bus_Identifikation : 32|8@1+ (1.0,0.0) [0.0|255] ""  OTA_FC
 SG_ SI_CAB : 40|24@1+ (1.0,0.0) [0.0|16777215] ""  OTA_FC

BO_ 1716 VIN_01: 8 Gateway
 SG_ VIN_01_MUX M  : 0|2@1+ (1,0) [0|3] ""  conBox
 SG_ KS_Geheimnis_1 m0  : 8|8@1+ (1,0) [0|255] ""  Vector__XXX
 SG_ VIN_4 m1  : 8|8@1+ (1,0) [0|255] ""  conBox
 SG_ VIN_11 m2  : 8|8@1+ (1,0) [0|255] ""  conBox
 SG_ KS_Geheimnis_2 m0  : 16|8@1+ (1,0) [0|255] ""  Vector__XXX
 SG_ VIN_5 m1  : 16|8@1+ (1,0) [0|255] ""  conBox
 SG_ VIN_12 m2  : 16|8@1+ (1,0) [0|255] ""  conBox
 SG_ KS_Geheimnis_3 m0  : 24|8@1+ (1,0) [0|255] ""  Vector__XXX
 SG_ VIN_6 m1  : 24|8@1+ (1,0) [0|255] ""  conBox
 SG_ VIN_13 m2  : 24|8@1+ (1,0) [0|255] ""  conBox
 SG_ KS_Geheimnis_4 m0  : 32|8@1+ (1,0) [0|255] ""  Vector__XXX
 SG_ VIN_7 m1  : 32|8@1+ (1,0) [0|255] ""  conBox
 SG_ VIN_14 m2  : 32|8@1+ (1,0) [0|255] ""  conBox
 SG_ VIN_1 m0  : 40|8@1+ (1,0) [0|255] ""  conBox
 SG_ VIN_8 m1  : 40|8@1+ (1,0) [0|255] ""  conBox
 SG_ VIN_15 m2  : 40|8@1+ (1,0) [0|255] ""  conBox
 SG_ VIN_2 m0  : 48|8@1+ (1,0) [0|255] ""  conBox
 SG_ VIN_9 m1  : 48|8@1+ (1,0) [0|255] ""  conBox
 SG_ VIN_16 m2  : 48|8@1+ (1,0) [0|255] ""  conBox
 SG_ VIN_3 m0  : 56|8@1+ (1,0) [0|255] ""  conBox
 SG_ VIN_10 m1  : 56|8@1+ (1,0) [0|255] ""  conBox
 SG_ VIN_17 m2  : 56|8@1+ (1,0) [0|255] ""  conBox

BO_ 2617196032 XCP_eCall_CRO_01: 8 Vector__XXX
 SG_ XCP_eCall_CRO_01_Data : 0|64@1+ (1,0) [0|1] ""  conBox

BO_ 2617196033 XCP_eCall_DTO_01: 8 conBox
 SG_ XCP_eCall_DTO_01_Data : 0|64@1+ (1,0) [0|1] ""  Vector__XXX

BO_ 2616997632 XCP_OTA_FC_CRO_01: 8 Vector__XXX
 SG_ XCP_OTA_FC_CRO_01_Data : 0|64@1+ (1,0) [0|1] ""  OTA_FC

BO_ 2616997633 XCP_OTA_FC_DTO_01: 8 OTA_FC
 SG_ XCP_OTA_FC_DTO_01_Data : 0|64@1+ (1,0) [0|1] ""  Vector__XXX

BO_ 1411 ZV_02: 8 Gateway
 SG_ BCM_FH_Freigabe : 12|1@1+ (1.0,0.0) [0.0|1] ""  Vector__XXX
 SG_ BCM_Komfortfkt_Freigabe : 13|1@1+ (1.0,0.0) [0.0|1] ""  Vector__XXX
 SG_ BCM_HSK_Freigabe : 14|1@1+ (1.0,0.0) [0.0|1] ""  Vector__XXX
 SG_ BCM_Verdeck_Freigabe : 15|1@1+ (1.0,0.0) [0.0|1] ""  Vector__XXX
 SG_ ZV_verriegelt_intern_ist : 16|1@1+ (1.0,0.0) [0.0|1] ""  Vector__XXX
 SG_ ZV_verriegelt_extern_ist : 17|1@1+ (1.0,0.0) [0.0|1] ""  Vector__XXX
 SG_ ZV_verriegelt_intern_soll : 18|1@1+ (1.0,0.0) [0.0|1] ""  Vector__XXX
 SG_ ZV_verriegelt_extern_soll : 19|1@1+ (1.0,0.0) [0.0|1] ""  Vector__XXX
 SG_ ZV_gesafet_extern_ist : 20|1@1+ (1.0,0.0) [0.0|1] ""  Vector__XXX
 SG_ ZV_gesafet_extern_soll : 21|1@1+ (1.0,0.0) [0.0|1] ""  Vector__XXX
 SG_ ZV_Einzeltuerentriegelung : 22|1@1+ (1.0,0.0) [0.0|1] ""  Vector__XXX
 SG_ ZV_Heckeinzelentriegelung : 23|1@1+ (1.0,0.0) [0.0|1] ""  Vector__XXX
 SG_ ZV_FT_offen : 24|1@1+ (1.0,0.0) [0.0|1] ""  Vector__XXX
 SG_ ZV_BT_offen : 25|1@1+ (1.0,0.0) [0.0|1] ""  Vector__XXX
 SG_ ZV_HFS_offen : 26|1@1+ (1.0,0.0) [0.0|1] ""  Vector__XXX
 SG_ ZV_HBFS_offen : 27|1@1+ (1.0,0.0) [0.0|1] ""  Vector__XXX
 SG_ ZV_HD_offen : 28|1@1+ (1.0,0.0) [0.0|1] ""  Vector__XXX
 SG_ ZV_HS_offen : 29|1@1+ (1.0,0.0) [0.0|1] ""  Vector__XXX
 SG_ IRUE_aktiv : 30|1@1+ (1.0,0.0) [0.0|1] ""  Vector__XXX
 SG_ DWA_aktiv : 31|1@1+ (1.0,0.0) [0.0|1] ""  conBox
 SG_ HD_Hauptraste : 32|1@1+ (1.0,0.0) [0.0|1] ""  Vector__XXX
 SG_ HD_Vorraste : 33|1@1+ (1.0,0.0) [0.0|1] ""  Vector__XXX
 SG_ FFB_CarFinder : 38|1@1+ (1.0,0.0) [0.0|1] ""  Vector__XXX
 SG_ FFB_Komfortoeffnen : 39|1@1+ (1.0,0.0) [0.0|1] ""  Vector__XXX
 SG_ FFB_Komfortschliessen : 40|1@1+ (1.0,0.0) [0.0|1] ""  Vector__XXX
 SG_ ZV_Schluessel_Zugang : 42|4@1+ (1.0,0.0) [0.0|15] ""  Vector__XXX
 SG_ ZV_SafeFunktion_aktiv : 46|1@1+ (1.0,0.0) [0.0|1] ""  Vector__XXX
 SG_ FBS_Warn_Schluessel_Batt : 47|1@1+ (1.0,0.0) [0.0|1] ""  Vector__XXX
 SG_ ZV_Oeffnungsmodus : 48|2@1+ (1.0,0.0) [0.0|3] ""  Vector__XXX
 SG_ HFS_verriegelt : 50|1@1+ (1.0,0.0) [0.0|1] ""  Vector__XXX
 SG_ HFS_gesafet : 51|1@1+ (1.0,0.0) [0.0|1] ""  Vector__XXX
 SG_ HBFS_verriegelt : 52|1@1+ (1.0,0.0) [0.0|1] ""  Vector__XXX
 SG_ HBFS_gesafet : 53|1@1+ (1.0,0.0) [0.0|1] ""  Vector__XXX
 SG_ ZV_ist_Zustand_verfuegbar : 54|1@1+ (1.0,0.0) [0.0|1] ""  Vector__XXX
 SG_ IRUE_Taster_Fkts_LED : 55|1@1+ (1.0,0.0) [0.0|1] ""  Vector__XXX
 SG_ ZV_Tankklappe_offen : 56|1@1+ (1.0,0.0) [0.0|1] ""  Vector__XXX
 SG_ ZV_Rollo_auf : 57|1@1+ (1.0,0.0) [0.0|1] ""  Vector__XXX
 SG_ ZV_Rollo_zu : 58|1@1+ (1.0,0.0) [0.0|1] ""  Vector__XXX
 SG_ ZV_SAD_auf : 59|1@1+ (1.0,0.0) [0.0|1] ""  Vector__XXX
 SG_ ZV_SAD_zu : 60|1@1+ (1.0,0.0) [0.0|1] ""  Vector__XXX
 SG_ BCM_Tankklappensteller_Fehler : 61|1@1+ (1.0,0.0) [0.0|1] ""  Vector__XXX
 SG_ ZV_verriegelt_soll : 62|2@1+ (1.0,0.0) [0.0|3] ""  Vector__XXX

BO_TX_BU_ 1601 :Gateway,Gateway_PAG;
BO_TX_BU_ 1156 :Gateway,Gateway_PAG;
BO_TX_BU_ 1157 :Gateway,Gateway_PAG;
BO_TX_BU_ 1158 :Gateway,Gateway_PAG;
BO_TX_BU_ 2589283496 :Gateway,Gateway_PAG;
BO_TX_BU_ 2600468496 :Gateway,Gateway_PAG;
BO_TX_BU_ 1635 :Gateway,Gateway_PAG;
BO_TX_BU_ 2589283656 :Gateway,Gateway_PAG;
BO_TX_BU_ 1122 :Gateway,Gateway_PAG;
BO_TX_BU_ 1527 :Gateway,Gateway_PAG;
BO_TX_BU_ 124 :Gateway,Gateway_PAG;
BO_TX_BU_ 378 :Gateway,Gateway_PAG;
BO_TX_BU_ 424 :Gateway,Gateway_PAG;
BO_TX_BU_ 133 :Gateway,Gateway_PAG;
BO_TX_BU_ 2463978662 :Gateway,Gateway_PAG;
BO_TX_BU_ 1413 :Gateway,Gateway_PAG;
BO_TX_BU_ 1716 :Gateway,Gateway_PAG;
BO_TX_BU_ 1411 :Gateway,Gateway_PAG;
CM_ BO_ 1601 "ab MQB mit CRC-8";
CM_ BO_ 1635 "DLC=8 ab D4 gültig";
CM_ BO_ 424 "CAN-Botschaft";
CM_ BO_ 1413 "MQB, MLBevo";
CM_ BO_ 1716 "200ms bei D4 und folgende";

CM_ SG_ 1601 MO_Ansaugsystem "Art des Ansaugsystems des Verbrennungsmotors";
CM_ SG_ 1601 MO_Anzahl_Zyl "Zylinderzahl des Verbrennungsmotors";
CM_ SG_ 1601 MO_Anzeige_StSt_gueltig "Zeigt die Gültigkeit der neuen StSt-Anzeigesignale an, MO_Anzeige_StSt_Text und  MO_Anzeige_Symbol. Mo_Text_Motorstart 1..5 sind zu ignorieren.";
CM_ SG_ 1601 MO_Code "Motorcodierinformation Version 16 (Details siehe Anhang)";
CM_ SG_ 1601 MO_DPF_verbaut "Verbauinformation Diesel-Partikel-Filter
";
CM_ SG_ 1601 MO_Faktor_Momente_02 "Dieses Signal schaltet den Wertebereich aller Momente vom Motor, Getriebe, TSK, Bremse ... um! Die Momente besitzen somit einen variablen Wertebereich, weil sich durch den Faktor die Momente sowohl in Auflösung als auch Maximalwerten ändert.

0x0 nicht ";
CM_ SG_ 1601 MO_Getriebe_Code "Getriebecodierung des Motors";
CM_ SG_ 1601 MO_Hubraum "Hubraum des Verbrennungsmotors";
CM_ SG_ 1601 MO_Hybridfahrzeug "Anhand dieses Signals plausibilisiert die Lenkhilfe das Bit Fahrbereitschaft.

Im Projekt Cayenne PHEV (und ggf. auch VW526 PHEV) ist aus Gründen der Abwärtskompatibilität der Wert '2' zu senden.";
CM_ SG_ 1601 MO_Kraftstoffart "Primärkraftstoff zum Antrieb des Fahrzeugs";
CM_ SG_ 1601 MO_Leistung "Nennleistung des Verbrennungsmotors

Im reinen E-Fahrzeug (BEV): Ausgabe der elektrischen Systemleistung";
CM_ SG_ 1601 MO_OBD_Typ "Abgastyp OBD
Hinweis: In Fahrzeugen mit dem Zielmarkt China und einer Zertifizierung ab China 6 muss auf dem Signal 'MO_OBD_Typ' der Wert 'US_OBD' gesendet werden.";
CM_ SG_ 1601 MO_StartStopp_Codiert "Funktion StartStopp im aktuellen Klemmenzyklus verbaut";
CM_ SG_ 1601 Motor_Code_01_CRC "Für MLB:
'Berechnung siehe Lastenheft 'Kommunikationsabsicherung für FlexRay und CAN''

Ab MQB und MLBevo:
'Berechnung siehe Lastenheft 'End-to-End Kommunikationsabsicherung''

Endwerte siehe Begleitdokument 'S-PDU Kennungsfolgen'";
CM_ SG_ 1601 TSK_Codierung "Information über den plausibilisierten Codierungszustand des Triebstrangskoordinators auf ACC oder GRA.";

CM_ SG_ 1156 ND_GDOP "geometric dilution of precision (Gesamtgenauigkeit, 3D und Zeit) 
";
CM_ SG_ 1156 ND_HDOP "horizontal dilution of precision (Horizontalrichtung, 2D)
";
CM_ SG_ 1156 ND_Heading "Fahrtrichtung";
CM_ SG_ 1156 ND_Init "Initialisierung";
CM_ SG_ 1156 ND_PDOP "positional dilution of precision (Positionsgenauigkeit, 3D) 
";
CM_ SG_ 1156 ND_TDOP "time dilution of precision (Zeitgenauigkeit)
";
CM_ SG_ 1156 ND_VDOP "vertical dilution of precision (Vertikalrichtung, 1D)
";

CM_ SG_ 1157 ND_SatInUse "Anzahl der zur Berechnung verwendeten Satelliten";
CM_ SG_ 1157 ND_SatInView "Anzahl der sichtbaren Satelliten";
CM_ SG_ 1157 ND_UTC "UTC-Zeit, verstrichene Sekunden seit 01.01.1970 00:00
0xFFFFFFFE = Init
0xFFFFFFFF = Fehler bei Berechnung der UTC-Time";
CM_ SG_ 1157 NP_Altitude "Hoehe ueber NN
0xFFF = Fehler bei der Berechnung der Höhe über NN";
CM_ SG_ 1157 POS_Guete_horizontal "Horizontale Genauigkeit der Position in der Botschaft NavPos_02_MapMatched (Signale
POS_LatDegree, POS_LongDegree)

Abhängig vom Signal
POS_Guete_horizontal_verfuegbar";
CM_ SG_ 1157 POS_Guete_horizontal_verfuegbar "Bei gesetztem Bit wird das Signal POS_Guete_horizontal befüllt und ist verfügbar.";

CM_ SG_ 1158 NP_LatDegree "Latitude (Nord-Süd Wert)";
CM_ SG_ 1158 NP_LatDirection "Hemisphäre Nord/Süd";
CM_ SG_ 1158 NP_LongDegree "Longitude (Ost-West Wert)";
CM_ SG_ 1158 NP_LongDirection "Hemisphäre Ost/West";
CM_ SG_ 1158 NP_Sat "Nummer der verwendeten Sateliten beim letzten Fix";

CM_ SG_ 2589283496 POS_Heading "Heading of current position
MUX(1)";
CM_ SG_ 2589283496 POS_Heading_Trust "Vertrauenswert Heading 
MUX(1) ";
CM_ SG_ 2589283496 POS_Last_GPS_Sync "Letztes bekannte GPS Sync in [s]
MUX(1)";
CM_ SG_ 2589283496 POS_LatDegree "latitude - position data of navigation
MUX(0)";
CM_ SG_ 2589283496 POS_LatDirection "latitude direction nav position
MUX(0)";
CM_ SG_ 2589283496 POS_LongDegree "long - position data of navigation
MUX(0)";
CM_ SG_ 2589283496 POS_LongDirection "longitude direction nav position
MUX(0)";
CM_ SG_ 2589283496 POS_MUX "Multiplex-Signal zum schalten des Signals der Positionen von der Navigation.
MUX(0/1)";
CM_ SG_ 2589283496 POS_ODD_EVEN "Synchronisation der MUX Pos Signale
MUX(0/1)";
CM_ SG_ 2589283496 POS_PosStati "Aktueller Status der Navgation:
MUX(0)
0   init
1   no nav available (ready_4_nav)
2   no map available (sd_removed, not_enabled)
3   nav booting
4   nav error
5   nav calibrating
6   nav no gps resync since 1h
7   nav offroad  parkgarage ramp of";
CM_ SG_ 2589283496 POS_UTC_REF "Zeitstempel der Nav
MUX(1)

UTC-Zeit, verstrichene Sekunden seit 01.01.1970 00:00
0xFFFFFFFE = Init
0xFFFFFFFF = Fehler bei Berechnung der UTC-Time

Signal wird nur bei aktiver Navigation-Funktion zyklisch gesendet.";

CM_ SG_ 2600468496 NM_Gateway_CAB "CAB = Clusteraktivbits";
CM_ SG_ 2600468496 NM_Gateway_Car_Wakeup "Car Wakeup (Subbusmaster wertet aus)

MQB: 
-Diagnose- oder Komponentenschutzmaster-Funktion weckt den schlafenden Subbus (z.B. MOST)

E3_Volumen:
- Diagnose aktiv -aktive Diagnosekommunikation am OBD-Stecker

MQBw_Baseline:
- Diagnose aktiv -akt";
CM_ SG_ 2600468496 NM_Gateway_CBV_AWB "Das Signal ist zu setzen, wenn das SG aktiv den Bus geweckt hat
0 = Passiver_WakeUp = SG hat das Netzwerk nicht aktiv geweckt
1 = Akitiver_WakeUp = SG hat das Netzwerk aktiv geweckt";
CM_ SG_ 2600468496 NM_Gateway_CBV_CRI "Das Signal ist dauerhaft gesetzt, wenn das NM-Layout Cluster- Anforderungen enthält";
CM_ SG_ 2600468496 NM_Gateway_NM_aktiv_Buskopplung "Nachlauf aufgrund Kopplung zweier Busse. z.B. K-CAN und K2-CAN";
CM_ SG_ 2600468496 NM_Gateway_NM_aktiv_Connect "Nachlauf aufgrund Connect";
CM_ SG_ 2600468496 NM_Gateway_NM_aktiv_CWU "Nachlauf aufgrund CWU Anforderung";
CM_ SG_ 2600468496 NM_Gateway_NM_aktiv_Diagnose "Diagnose befindet sich nach VW80124 in einer NonDefaultDiagnostic-Session, z.B. ExtendedDiagnostic-Session";
CM_ SG_ 2600468496 NM_Gateway_NM_aktiv_EM "Nachlauf aufgrund Energiemanagement";
CM_ SG_ 2600468496 NM_Gateway_NM_aktiv_FC "Nachlauf aufgrund Funktionscluster Anforderung";
CM_ SG_ 2600468496 NM_Gateway_NM_aktiv_Fremdladung "Nachlauf aufgrund Fremdladung";
CM_ SG_ 2600468496 NM_Gateway_NM_aktiv_KL15 "Steuergerät hat KL15-EIN erkannt";
CM_ SG_ 2600468496 NM_Gateway_NM_aktiv_LIN2 "Bus aktiv aufgrund aktivem LIN2 (Hupe betätigt)";
CM_ SG_ 2600468496 NM_Gateway_NM_aktiv_OBDC "Nachlauf aufgrund OBDC";
CM_ SG_ 2600468496 NM_Gateway_NM_aktiv_Tmin "Mindestaktivzeit ist noch nicht abgelaufen (bei jedem Weckereignis wird die Mindestaktivzeit neu gestartet)";
CM_ SG_ 2600468496 NM_Gateway_NM_State "1 = Zustand Repeat Message (<-- Bus-Sleep Mode)
2 = Zustand Repeat Message (<-- Prepare Bus-Sleep Mode)
4 = Zustand Normal Operation (<-- Repeat Message)
8 = Zustand Normal Operation (<-- Ready Sleep)";
CM_ SG_ 2600468496 NM_Gateway_SNI "Source Node-Identifier (SNI) identifiziert den Sender der NM-Botschaft (Knotenadresse) eindeutig im Fahrzeug";
CM_ SG_ 2600468496 NM_Gateway_UDS_CC "Funktionseinschränkung aufgrund aktivem UDS-Communication Control, siehe VW80124";

CM_ SG_ 2600468489 NM_Sekundaer_09_CAB "CAB = Clusteraktivbits";
CM_ SG_ 2600468489 NM_Sekundaer_09_Car_Wakeup "Car Wakeup (Gateway wertet aus)

MQB:
aktuell kein Car Wakeup Grund seitens FCM";
CM_ SG_ 2600468489 NM_Sekundaer_09_CBV_AWB "Das Signal ist zu setzen, wenn das SG aktiv den Bus geweckt hat";
CM_ SG_ 2600468489 NM_Sekundaer_09_CBV_CRI "Das Signal ist dauerhaft gesetzt, wenn das NM-Layout dem neuen NM-Layout für Teilnetzbetrieb entspricht";
CM_ SG_ 2600468489 NM_Sekundaer_09_NM_aktiv_Backend "Kommunikation mit Backend aktiv";
CM_ SG_ 2600468489 NM_Sekundaer_09_NM_aktiv_BaseFct "Kommunikation mit Backend aktiv";
CM_ SG_ 2600468489 NM_Sekundaer_09_NM_aktiv_Diag "Diagnose befindet sich nach VW80124 in einer NonDefaultDiagnostic-Session, z.B. ExtendedDiagnostic-Session";
CM_ SG_ 2600468489 NM_Sekundaer_09_NM_aktiv_KL15 "Steuergerät hat KL15-EIN erkannt";
CM_ SG_ 2600468489 NM_Sekundaer_09_NM_aktiv_MOD "MOD fordert Buskommunikation";
CM_ SG_ 2600468489 NM_Sekundaer_09_NM_aktiv_RmtDiag "RemoteDiagnose fordert Buskommunikation";
CM_ SG_ 2600468489 NM_Sekundaer_09_NM_aktiv_RmtFcts "RemoteFunction fordert Buskommunikation";
CM_ SG_ 2600468489 NM_Sekundaer_09_NM_aktiv_RmtUpdt "RemoteUpdate fordert Buskommunikation";
CM_ SG_ 2600468489 NM_Sekundaer_09_NM_aktiv_Tmin "Mindestaktivzeit ist noch nicht abgelaufen (bei jedem Weckereignis wird die Mindestaktivzeit neu gestartet)";
CM_ SG_ 2600468489 NM_Sekundaer_09_NM_State "1 = Zustand Repeat Message (<-- Bus-Sleep Mode)
2 = Zustand Repeat Message (<-- Prepare Bus-Sleep Mode)
4 = Zustand Normal Operation (<-- Repeat Message)
8 = Zustand Normal Operation (<-- Ready Sleep)";
CM_ SG_ 2600468489 NM_Sekundaer_09_SNI "Source Node-Identifier (SNI) identifiziert den Sender der NM-Botschaft (Knotenadresse) eindeutig im Fahrzeug";
CM_ SG_ 2600468489 NM_Sekundaer_09_UDS_CC "Funktionseinschränkung aufgrund aktivem UDS-Communication Control; siehe VW80124";

CM_ SG_ 2600468720 NM_Sekundaer_F0_CAB "CAB = Clusteraktivbits";
CM_ SG_ 2600468720 NM_Sekundaer_F0_Car_Wakeup "Car Wakeup (Gateway wertet aus)";
CM_ SG_ 2600468720 NM_Sekundaer_F0_CBV_AWB "Das Signal ist zu setzen, wenn das SG aktiv den Bus geweckt hat";
CM_ SG_ 2600468720 NM_Sekundaer_F0_CBV_CRI "Das Signal ist dauerhaft gesetzt, wenn das NM-Layout dem neuen NM-Layout für Teilnetzbetrieb entspricht";
CM_ SG_ 2600468720 NM_Sekundaer_F0_NM_aktiv_BTKey "Steuergerät hat gültigen Schlüssel über Bluetooth empfangen";
CM_ SG_ 2600468720 NM_Sekundaer_F0_NM_aktiv_Diag "Diagnose befindet sich nach VW80124 in einer NonDefaultDiagnostic-Session, z.B. ExtendedDiagnostic-Session";
CM_ SG_ 2600468720 NM_Sekundaer_F0_NM_aktiv_eCall "Waehrend aktivem eCALL muss der CAN für die BAP-Strecke wachgehalten werden";
CM_ SG_ 2600468720 NM_Sekundaer_F0_NM_aktiv_Eth_Kom "Nach einem Wakeup über Backend muss der CAN so lange wachgehalten werden, bis eine stabile Ethernetverbindung (inkl. SOME/IP etc.) etabliert ist.";
CM_ SG_ 2600468720 NM_Sekundaer_F0_NM_aktiv_KL15 "Steuergerät hat KL15-EIN erkannt";
CM_ SG_ 2600468720 NM_Sekundaer_F0_NM_aktiv_Timer "Beim Aendern eines Timerwertes in der ConBox muss dies dem Gateway mitgeteilt werden.";
CM_ SG_ 2600468720 NM_Sekundaer_F0_NM_aktiv_Tmin "Mindestaktivzeit ist noch nicht abgelaufen (bei jedem Weckereignis wird die Mindestaktivzeit neu gestartet)";
CM_ SG_ 2600468720 NM_Sekundaer_F0_NM_aktiv_VTS "Bei aktiver VTS muss der Bus wachhgehalten werden. Zeitlich unbegrenzt";
CM_ SG_ 2600468720 NM_Sekundaer_F0_NM_State "1 = Zustand Repeat Message (<-- Bus-Sleep Mode)
2 = Zustand Repeat Message (<-- Prepare Bus-Sleep Mode)
4 = Zustand Normal Operation (<-- Repeat Message)
8 = Zustand Normal Operation (<-- Ready Sleep)
16 = Zustand Repeat Message (<-- Normal Operation)";
CM_ SG_ 2600468720 NM_Sekundaer_F0_SNI "Source Node-Identifier (SNI) identifiziert den Sender der NM-Botschaft (Knotenadresse) eindeutig im Fahrzeug";
CM_ SG_ 2600468720 NM_Sekundaer_F0_UDS_CC "Funktionseinschränkung aufgrund aktivem UDS-Communication Control; siehe VW80124";

CM_ SG_ 1635 BEM_02_Abschaltstufen "Abschaltstufen des Ruhestrommanagements (Initialisierungswert aus EEprom)

Stufe 0 (keine Einschraenkungen)
Stufe 1 (Abschaltung Hochstromverbraucher)
Stufe 2 (Infotainmentabschaltung)
Stufe 3 (Wake-Up-Sperre)

Für den Transport- und Ruhestrommessm";
CM_ SG_ 1635 BEM_Anf_KL15_schalten "Abschaltempfehlung bzw. Verhinderung der automatischen Abschaltung Kl15 durch das BCM";
CM_ SG_ 1635 BEM_Batteriediagnose "Anzeige von Textwarnungen";
CM_ SG_ 1635 BEM_Generatordiagnose "Ansteuerung Generatorwarnleuchte im Kombi
";
CM_ SG_ 1635 BEM_HL_Regelung_Status "Status Regelung Heizleistung
";
CM_ SG_ 1635 BEM_Ladezustand "Ladezustand der Niedervoltbatterie
";
CM_ SG_ 1635 BEM_MMI_Vorwarnung "Anzeige Vorwarnung MMI-Abschaltung (Initialisierungswert aus EEprom)
";
CM_ SG_ 1635 BEM_Red_Innengeblaese "Reduzierung Innengebläse
";
CM_ SG_ 1635 BEM_REK_aktiv "Rekuperationsfreigabe vom Energiemanagement
0x0 = keine Rekuperationsfreigabe
0x1 = Rekuperationsfreigabe";
CM_ SG_ 1635 BEM_STH_Einschaltverbot "Einschränkung Standheizung/-lüftung durch BEM: Setzt der BEM das Bit, dann darf die Standheizung nicht mehr einschalten
(Die Standheizung muss aber nicht abschalten, sondern darf weiterbrennen)
(Initialisierungswert aus EEprom)
";
CM_ SG_ 1635 BEM_STH_Zielzeit "Maximal mögliche Zeit für den Standheizungsbetrieb, um die Startfähigkeit nicht zu gefährden";
CM_ SG_ 1635 BEM_UBDM "Batteriespannung, gemessen vom Batteriedatenmodul";
CM_ SG_ 1635 BEM_UGenSoll "Sollspannungsvorgabe an den Generator, beinhaltet temperaturoptimierte Batterieladung und Rekuperation";
CM_ SG_ 1635 MIB_Stromsparmodus "Signal beschreibt die Aktivierung für den Stromsparmodus beim MIB.
Bei AUS (= 0) gibt es keine weitere Anforderung an die MIB-Komponenten.
Bei EIN (= 1) werden alle MIB Komponenten in einen Stromsparmodus versetzt.";
CM_ SG_ 1635 NVEM_Anf_SD_schalten "Anforderung Nachlauf für den Steckdosenbetrieb
Initialisierungswert aus EEprom";
CM_ SG_ 1635 NVEM_Batterie_Service "Anforderung einer Batterie-Service - Anzeige / Anforderung an die Werkstatt über MOD";
CM_ SG_ 1635 NVEM_Freigabe_OnlineUpdate "Freigabe für Online-Update durch Energiemanagement";
CM_ SG_ 1635 NVEM_Freigabe_ORU4 "Bestätigung oder Ablehnung eines konkreten, angefragten Online Updates durch das Energiemanagements";
CM_ SG_ 1635 NVEM_Last_Anf "Das NVEM fordert für die Batteriediagnose einen Lastimpuls vom Fahrzeug an, der durch kontrollierte Verbraucherzuschaltungen (z. B. Aktivierung Heckscheibenheizung) generiert wird";

CM_ SG_ 2589283656 ORU_Status "Verteilung des internen ORU Zustandes";
CM_ SG_ 2589283656 ORU_Warnung "Wenn durch Störungen der Funktion Online Remote Update nicht sichergestellt ist, dass vor Kunde keine Funktionseinschränkungen auftreten, muss der Benutzer des Fahrzeugs entsprechend gewarnt werden.";

CM_ SG_ 2527679670 ORU_EM_Anfrage_Flashdauer "Anfrage an das Energiemanagement, ob ein konkretes Online Remote Update durchgeführt werden kann - Flashdauer in 10s.";
CM_ SG_ 2527679670 ORU_EM_Anfrage_freigegebeneNetze "Meldung der während eines konkreten Online Remote Updates freigegebenen Netze (12V, 48V, HV)";
CM_ SG_ 2527679670 ORU_EM_Anfrage_Stromaufnahme "Meldung der voraussichtlichen durchschnittlichen Stromaufnahme eines konkreten Online Remote Updates an das NVEM";
CM_ SG_ 2527679670 ORU_Status_Anf "Übertragung des Status der Funktion Online Remote Update im Porsche / OTA-FC Fall: Sender ist OTA-FC, GW patcht den Inhalt auf ORU_Status";
CM_ SG_ 2527679670 OTA_FC_FahrwerkAnf "Fahrwerk Anforderung OTA-FC";
CM_ SG_ 2527679670 OTA_FC_FoD_Stornierung "Falls der Kunde eine Assistenz-Funktion storniert, muss der Fahrer darüber informiert werden.
Dies geschieht zum einen durch ein FoD-Icon und andererseits durch einen Anzeigetext.";
CM_ SG_ 2527679670 OTA_FC_Hinweis_Update "Funktion: SWaP online und SW Update
Hinweismeldung, wenn ein OTA SW-Update/Aktivierung verfügbar ist";
CM_ SG_ 2527679670 OTA_FC_IOF_Ausfall "Funktion: IOF (PIDM)
Warnmeldung, wenn Funktion IOF (PIDM) ist ausgefallen ist";
CM_ SG_ 2527679670 OTA_FC_LiftAnf "OTA-FC Lift Anforderung";
CM_ SG_ 2527679670 OTA_FC_NiveauAnf "OTA-FC Niveau Anforderung";
CM_ SG_ 2527679670 OTA_FC_PredMaint_Ausfall "Funktion: Predictive Maintenance
Warnmeldung, wenn Funktion Predictive Maintenance ausgefallen ist";
CM_ SG_ 2527679670 OTA_FC_Warnung_Update "Funktion: SWaP online    und    SW Update
Warnmeldung, wenn OTA SW-Update/Aktivierung nicht erfolgreich war";

CM_ SG_ 2463978757 PSO_last_rec_UserID_Src2 "Zuletzt erkannte User-ID der Nutzererkennung Personalisierung 2.0";

CM_ SG_ 1122 PSD_Abzweigerichtung "Richtung, in der die Abzweigung von der Hauptroute abzweigt
";
CM_ SG_ 1122 PSD_Abzweigewinkel "Winkel, unter dem die Abzweigung von der Hauptroute abzweigt.
";
CM_ SG_ 1122 PSD_ADAS_Qualitaet "ADAS Qualtität des Streckensegments.";
CM_ SG_ 1122 PSD_Anfangskruemmung "Startkrümmung der Klothoide des übermittelten abzweigenden Streckensegments. 
1/(1+0.155 * x^2) {1/m}'
";
CM_ SG_ 1122 PSD_Anfangskruemmung_Vorz "Vorzeichen für die Startkrümmung bei Abzweigungen
";
CM_ SG_ 1122 PSD_Bebauung "Segement befindet sich innerhalb bebauten Gebietes";
CM_ SG_ 1122 PSD_Endkruemmung "'Endkrümmung der Klotoide des übermittelten Streckensegments. Die Anfangskrümmung des folgenden Streckensegments entspricht der Endkrümmung dieses Segments. Krümmung = 1/(1+0.155 * x²) [1/m]

";
CM_ SG_ 1122 PSD_Fahrspuren_Anzahl "Anzahl der Fahrspuren in Fahrtrichtung
";
CM_ SG_ 1122 PSD_Geradester_Pfad "Segment ist Teil des geradesten Pfades";
CM_ SG_ 1122 PSD_Idenditaets_ID "Identifier auf ein Streckensegment, dass mit dem aktuell übertragenen geometrisch identisch ist.";
CM_ SG_ 1122 PSD_Segment_ID "Identifier des prädiktiven Streckensegments
";
CM_ SG_ 1122 PSD_Segment_Komplett "Zeigt, ob alle Attribute für das Segment übertragen worden sind
";
CM_ SG_ 1122 PSD_Segmentlaenge "Gesamtlänge des prädiktiven Streckensegments";
CM_ SG_ 1122 PSD_Strassenkategorie "Klassifizierung der Straße des beschriebenen Segments
";
CM_ SG_ 1122 PSD_Vorgaenger_Segment_ID "An dem Streckensegment mit diesem Identifier schließt sich das neue Segment mit der ID 'PSD_01_Segment_ID' an.
";
CM_ SG_ 1122 PSD_wahrscheinlichster_Pfad "Identifiziert den vom Navigationssystem berechneten wahrscheinlichsten Pfad des Fahrzeuges. ";

CM_ SG_ 1527 RW_Gesamt_Reichweite_Anzeige "Reichweite für primär und sekundär Reichweite (eventuell Gewichtet) zur Anzeige im Kombi. Die Einheit dieser Signal ist über RW_Reichweite_Einheit_Anzeige bereitgestellt.";
CM_ SG_ 1527 RW_Primaer_Reichweite_Anzeige "Reichweite der primären Antriebsart zur Anzeige im Kombi";
CM_ SG_ 1527 RW_Reichweite_Einheit_Anzeige "Einheit für Primaer-/Sekundaer-/Gesamt- Reichweite zur Anzeige im Kombi";
CM_ SG_ 1527 RW_Reservewarnung_aktiv "Ansteuerung der Reservewarnung im Kombiinstrument (Leuchte und MFA-Warnhinweis). Wird gesetzt bei Erreichen / Unterschreiten eines unteren Reichweitenschwellwerts und zurückgenommen bei Erreichen / Überschreiten eines oberen Reichweitenschwellwerts.";
CM_ SG_ 1527 RW_Sek_Reichweitenv_Einheit "Für sekundäre Reichweitenberechnung (KBI_Sek_Reichweitenverbrauch) zugrunde gelegte Einheit";
CM_ SG_ 1527 RW_Sek_Reichweitenverbrauch "Für sekundäre Reichweitenberechnung zugrunde gelegter Verbrauch";
CM_ SG_ 1527 RW_Sekundaer_Reichweite "Reichweite der sekundaeren Antriebsart";
CM_ SG_ 1527 RW_Sekundaer_Reichweite_Anzeige "Reichweite der sekundaeren Antriebsart zur Anzeige im Kombi";
CM_ SG_ 1527 RW_Tendenz "Signalisierung der RW-Tendenz auf Basis der aktuellen Fahrweise. ";
CM_ SG_ 1527 RW_Texte "Signal zum Steuern von reichweitenbezogenen Hinweistexten für Pop-Up Anzeigen im Kombiinstrument";

CM_ SG_ 124 SARA_Accel_Z_b_CAN "Beschleunigung Acceleration-Z Basis:
- 0x0000 = Sensor nicht verbaut, Signal wird nicht berechnet
- genutzter Wertebereich ± 640 m/s²

Filterung: 60 Hz Sensorfilter + ohne uC-Filter";
CM_ SG_ 124 SARA_CF_Accel_Z_b_CAN "Confidence Faktor Beschleunigung Acceleration-Z Basis:

0=gültiger Wert
1=nicht belegt
2=nicht belegt
3=Temporärer Fehler {solange möglich werden aktuelle Sensorwerte gesendet, ansonsten 0xFFFF}
4=Init {0x8000 wird gesendet}
5=Sensor nicht verbaut/";
CM_ SG_ 124 SARA_CF_Omega_X_b_CAN "Confidence Faktor Winkelgeschwindigkeit Omega-X Basis:

0=gültiger Wert
1=nicht belegt
2=nicht belegt
3=Temporärer Fehler {solange möglich werden aktuelle Sensorwerte gesendet, ansonsten 0xFFFF}
4=Init {0x8000 wird gesendet}
5=Sensor nicht verbaut/";
CM_ SG_ 124 SARA_CF_Omega_Y_b_CAN "Confidence Faktor Winkelgeschwindigkeit Omega-Y Basis:

0=gültiger Wert
1=nicht belegt
2=nicht belegt
3=Temporärer Fehler {solange möglich werden aktuelle Sensorwerte gesendet, ansonsten 0xFFFF}
4=Init {0x8000 wird gesendet}
5=Sensor nicht verbaut/";
CM_ SG_ 124 SARA_Omega_X_b_CAN "Winkelgeschwindigkeit Omega-X Basis:
- 0x0000 = Sensor nicht verbaut, Signal wird nicht berechnet
- genutzter Wertebereich ± 320 Deg/s

Filterung: 60 Hz Sensorfilter + ohne uC-Filter";
CM_ SG_ 124 SARA_Omega_Y_b_CAN "Winkelgeschwindigkeit Omega-Y Basis:
- 0x0000 = Sensor nicht verbaut, Signal wird nicht berechnet
- genutzter Wertebereich ± 320 Deg/s

Filterung: 60 Hz Sensorfilter + ohne uC-Filter";

CM_ SG_ 378 SARA_Accel_X_010_02 "Beschleunigung Acceleration-X Basis:
- 0x0000 = Sensor nicht verbaut, Signal wird nicht berechnet
- genutzter Wertebereich ± 640 m/s²

Filterung: 60 Hz Sensorfilter + 15 Hz uC-Filter (Cheby-II 3.Ordnung)";
CM_ SG_ 378 SARA_Accel_Y_010_02 "Beschleunigung Acceleration-X Basis:
- 0x0000= Sensor nicht verbaut, Signal wird nicht berechnet
- genutzter Wertebereich ± 640 m/s²

Filterung: 60 Hz Sensorfilter + 15 Hz uC-Filter (Cheby-II 3.Ordnung)";
CM_ SG_ 378 SARA_CF_Accel_X_010_02 "Confidence Faktor Beschleunigung Acceleration-X Basis:

0=gültiger Wert
1=nicht belegt
2=nicht belegt
3=Temporärer Fehler [solange möglich werden aktuelle Sensorwerte gesendet, ansonsten 0xFFFF]
4=Init [0x8000 wird gesendet]
5=Sensor nicht verbaut/";
CM_ SG_ 378 SARA_CF_Accel_Y_010_02 "Confidence Faktor Beschleunigung Acceleration-Y Basis:

0=gültiger Wert
1=nicht belegt
2=nicht belegt
3=Temporärer Fehler [solange möglich werden aktuelle Sensorwerte gesendet, ansonsten 0xFFFF]
4=Init [0x8000 wird gesendet]
5=Sensor nicht verbaut/";
CM_ SG_ 378 SARA_CF_Omega_Z_010_02 "Confidence Faktor Winkelgeschwindigkeit Omega-Z Basis:

0=gültiger Wert
1=nicht belegt
2=nicht belegt
3=Temporärer Fehler [solange möglich werden aktuelle Sensorwerte gesendet, ansonsten 0xFFFF]
4=Init [0x8000 wird gesendet]
5=Sensor nicht verbaut/";
CM_ SG_ 378 SARA_Omega_Z_010_02 "Winkelgeschwindigkeit Omega-Z Basis:
- 0x0000 = Sensor nicht verbaut, Signal wird nicht berechnet
- genutzter Wertebereich ± 320 Deg/s

Filterung: 60 Hz Sensorfilter + ohne uC-Filter";

CM_ SG_ 424 SARA_11_CRC "Für MLB:
'Berechnung siehe Lastenheft 'Kommunikationsabsicherung für Flexray und CAN''

Ab MQB und MLBevo:
'Berechnung siehe Lastenheft 'End-to-End Kommunikationsabsicherung'

Endwerte siehe Begleitdokument 'S-PDU Kennungsfolge'";
CM_ SG_ 424 SARA_Accel_X_r "Beschleunigung Acceleration-X routable:
- 0x0000= Sensor nicht verbaut, Signal wird nicht berechnet
- genutzter Wertebereich ± 640 m/s²

Filterung: 60 Hz Sensorfilter + 15 Hz uC-Filter (Cheby-II 3.Ordnung)";
CM_ SG_ 424 SARA_Accel_Y_r "Beschleunigung Acceleration-Y routable:
- 0x0000= Sensor nicht verbaut, Signal wird nicht berechnet
- genutzter Wertebereich ± 640 m/s²

Filterung: 60 Hz Sensorfilter + 15 Hz uC-Filter (Cheby-II 3.Ordnung)";
CM_ SG_ 424 SARA_CF_Accel_X_r "Confidence Faktor Beschleunigung Acceleration-X routable:

0=gültiger Wert
1=nicht belegt
2=nicht belegt
3=Temporärer Fehler {solange möglich werden aktuelle Sensorwerte gesendet, ansonsten 0xFFFF}
4=Init {0x8000 wird gesendet}
5=Sensor nicht verba";
CM_ SG_ 424 SARA_CF_Accel_Y_r "Confidence Faktor Beschleunigung Acceleration-Y routable:

0=gültiger Wert
1=nicht belegt
2=nicht belegt
3=Temporärer Fehler {solange möglich werden aktuelle Sensorwerte gesendet, ansonsten 0xFFFF}
4=Init {0x8000 wird gesendet}
5=Sensor nicht verba";
CM_ SG_ 424 SARA_CF_Omega_Z_r "Confidence Faktor Winkelgeschwindigkeit Omega-Z routable:

0=gültiger Wert
1=nicht belegt
2=nicht belegt
3=Temporärer Fehler {solange möglich werden aktuelle Sensorwerte gesendet, ansonsten 0xFFFF}
4=Init {0x8000 wird gesendet}
5=Sensor nicht verba";
CM_ SG_ 424 SARA_Omega_Z_r "Winkelgeschwindigkeit Omega-Z routable:
- 0x0000 = Sensor nicht verbaut, Signal wird nicht berechnet
- genutzter Wertebereich ± 320 Deg/s

Filterung: 60 Hz Sensorfilter + 15 Hz uC-Filter (Cheby-II 3.Ordnung)";

CM_ SG_ 133 SCU_01_BZ "Botschaft asynchron geroutet. Zählerwert kann springen.";
CM_ SG_ 133 SCU_01_CRC "Für MLB:
'Berechnung siehe Lastenheft 'Kommunikationsabsicherung für FlexRay und CAN''

Ab MQB und MLBevo:
'Berechnung siehe Lastenheft 'End-to-End Kommunikationsabsicherung''

Endwerte siehe Begleitdokument 'S-PDU Kennungsfolgen'";
CM_ SG_ 133 SCU_IL_Leistungsreserve "Zeigt die aktuell verfügbare Leistung der Lenkung in °/s an";
CM_ SG_ 133 SCU_Ist_Ue_Winkel "Gesamt-Überlagerungs-/ Motorwinkel bezogen auf Ritzelebene";
CM_ SG_ 133 SCU_max_Gradient "Von der Fahrgeschwindigkeit abhängige maximaler Zustellgradient der ESP-Stabilisierungsfunktionen bezogen auf Ritzelebene.
";
CM_ SG_ 133 SCU_Sensorstatus "Signal liefert Sensorstatus bei Winkeloffsetänderung";
CM_ SG_ 133 SCU_Soll_Ue_Winkel "Teil-Sollwinkel der SCU-Funktionen (variable Lenkübersetzung) bezogen auf das Ritzel";
CM_ SG_ 133 SCU_Status "Status der SCU

0x5 - 0xF = tbd.
";
CM_ SG_ 133 SCU_VZ_Ist_Ue_Winkel "Vorzeichen des Gesamt-Überlagerungswinkels ";
CM_ SG_ 133 SCU_VZ_Soll_Ue_Winkel "Vorzeichen des SCU-Teil-Sollwinkels";
CM_ SG_ 133 SCU_Winkelbegrenzung "Signal liefert eine aktive Lenkwinkelbegrenzung zum Bauteilschutz.";

CM_ SG_ 2589283634 SM_LAPP_Aussenlicht_aktiv "Rückmeldung ob Licht-App für Aussenlicht aktiv ist.";
CM_ SG_ 2589283634 SM_LAPP_Demo_ABBL_Anf "Anforderung des Abblendlichts zur Demonstration über die Licht-App.";
CM_ SG_ 2589283634 SM_LAPP_Demo_Autobahnmodus_Anf "Anforderung des Autobahnmodus zur Demonstration über die Licht-App";
CM_ SG_ 2589283634 SM_LAPP_Demo_Distanz_01 "Abstandsangabe zur Demonstration verschiedener Lichtfunktionen über die Licht-App.";
CM_ SG_ 2589283634 SM_LAPP_Demo_Distanz_02 "Abstandsangabe zur Demonstration verschiedener Lichtfunktionen über die Licht-App.";
CM_ SG_ 2589283634 SM_LAPP_Demo_DKL_Anf "Anforderung des dyn. Kurvenlichts über die Licht-App";
CM_ SG_ 2589283634 SM_LAPP_Demo_Einschalteffekt_Anf "Anforderung des Einschalteffekts zur Demonstration über die Licht-App";
CM_ SG_ 2589283634 SM_LAPP_Demo_FL_Anf "Anforderung des Fernlichts zur Demonstration über die Licht-App.";
CM_ SG_ 2589283634 SM_LAPP_Demo_MaLi_Anf "Anforderung des Markierungslichts zur Demonstration über die Licht-App";
CM_ SG_ 2589283634 SM_LAPP_Demo_Objekt_01_Anf "Anforderung zur Ausblendung eines Objekts zur Demonstration der MxB-Funktionalität über die Licht-App";
CM_ SG_ 2589283634 SM_LAPP_Demo_Objekt_02_Anf "Anforderung zur Ausblendung eines Objekts zur Demonstration der MxB-Funktionalität über die Licht-App";
CM_ SG_ 2589283634 SM_LAPP_Demo_Schildentbl_01_Anf "Anforderung der Schilderentblendung zur Demonstration über die Licht-App";
CM_ SG_ 2589283634 SM_LAPP_Demo_Schildentbl_02_Anf "Anforderung der Schilderentblendung zur Demonstration über die Licht-App";
CM_ SG_ 2589283634 SM_LAPP_Demo_Winkel_Hor_01 "Horizontaler Universalwinkel zur Demonstration verschiedener Lichtfunktionen über die Licht-App.";
CM_ SG_ 2589283634 SM_LAPP_Demo_Winkel_Hor_02 "Horizontaler Universalwinkel zur Demonstration verschiedener Lichtfunktionen über die Licht-App.";
CM_ SG_ 2589283634 SM_LAPP_Demo_Winkel_Vert_01 "Vertikaler Universalwinkel zur Demonstration verschiedener Lichtfunktionen über die Licht-App.";
CM_ SG_ 2589283634 SM_LAPP_Demo_Winkel_Vert_02 "Vertikaler Universalwinkel zur Demonstration verschiedener Lichtfunktionen über die Licht-App.";
CM_ SG_ 2589283634 SM_LAPP_Verbindungsstatus "Verbindungsstatus der Licht-App zur DDA für Aussenlicht.";

CM_ SG_ 2527679657 SM_LAPP_Demo_AbbiegeWa_Anf "Anforderung des Abbiege-Warnlichts zur Demonstration über die Licht-App.";
CM_ SG_ 2527679657 SM_LAPP_Demo_AbsAss_Anf "Anforderung des Abstands-Assistentzlichts zur Demonstration über die Licht-App.";
CM_ SG_ 2527679657 SM_LAPP_Demo_AccAss_Anf "Anforderung des ACC-Assistentzlichts zur Demonstration über die Licht-App.";
CM_ SG_ 2527679657 SM_LAPP_Demo_advCH_F01_Anf "Anforderung von advanced Coming Home zur Demonstration über die Licht-App.";
CM_ SG_ 2527679657 SM_LAPP_Demo_advLH_F01_Anf "Anforderung von advanced Leaving Home zur Demonstration über die Licht-App.";
CM_ SG_ 2527679657 SM_LAPP_Demo_BauLi_Anf "Anforderung des Baustellenlichts zur Demonstration über die Licht-App.";
CM_ SG_ 2527679657 SM_LAPP_Demo_BeAss_Anf "Anforderung des Beschleunigungs-Lichtassistenten zur Demonstration über die Licht-App.";
CM_ SG_ 2527679657 SM_LAPP_Demo_CH_F01_Anf "Anforderung unterschiedlicher Coming Home Animationen für die Front zur Demonstration über die Licht-App.

Der Wert des Signals gibt die ID der auszuführenden Animation aus. Die Zuordnung der IDs ist dabei fahrzeugspezifisch. Der Signalwert 0 entspricht";
CM_ SG_ 2527679657 SM_LAPP_Demo_CH_H01_Anf "Anforderung der Heckleuchten-Animation für Coming Home zur Demonstration über die Licht-App";
CM_ SG_ 2527679657 SM_LAPP_Demo_EffAss_Anf "Anforderung des Effizienz-Lichtassistenten zur Demonstration über die Licht-App.";
CM_ SG_ 2527679657 SM_LAPP_Demo_LH_F01_Anf "Anforderung unterschiedlicher Leaving Home Animationen für die Front zur Demonstration über die Licht-App.

Der Wert des Signals gibt die ID der auszuführenden Animation aus. Die Zuordnung der IDs ist dabei fahrzeugspezifisch. Der Signalwert 0 entsprich";
CM_ SG_ 2527679657 SM_LAPP_Demo_LH_H01_Anf "Anforderung der Heckleuchten-Animation für Leaving Home zur Demonstration über die Licht-App";
CM_ SG_ 2527679657 SM_LAPP_Demo_PreSAss_Anf "Anforderung des PreSense-Lichtassistenten zur Demonstration über die Licht-App.";
CM_ SG_ 2527679657 SM_LAPP_Demo_RouLi_Anf "Anforderung des Routenlichts zur Demonstration über die Licht-App.";
CM_ SG_ 2527679657 SM_LAPP_Demo_SitLi_Anf "Anforderung des Situationslichts zur Demonstration über die Licht-App.";
CM_ SG_ 2527679657 SM_LAPP_Demo_SL_Anf "Anforderung des Schlusslichts zur Demonstration über die Licht-App";
CM_ SG_ 2527679657 SM_LAPP_Demo_SL_Signatur_Anf "Anforderung einer Schlusslicht-Signatur über die Licht-App";
CM_ SG_ 2527679657 SM_LAPP_Demo_SpuLi_Anf "Anforderung des Spurlichts zur Demonstration über die Licht-App.";
CM_ SG_ 2527679657 SM_LAPP_Demo_Stufe "Universelle Stufenvorgabe zur Demonstration verschiedener Lichtfunktionen über die Licht-App.";
CM_ SG_ 2527679657 SM_LAPP_Demo_TraLi_Anf "Anforderung des Trajektorienlichts zur Demonstration über die Licht-App.";
CM_ SG_ 2527679657 SM_LAPP_Demo_Variante "Universelle Variantenvorgabe zur Demonstration verschiedener Lichtfunktionen über die Licht-App.";

CM_ SG_ 2463978662 STS2_01_BZ "4bit Botschaftszähler, wird in jeder Sendebotschaft inkrementiert

CRC/BZ für Manipulationsschutz";
CM_ SG_ 2463978662 STS2_01_CRC "Für MLB:
'Berechnung siehe Lastenheft 'Kommunikationsabsicherung für FlexRay und CAN''

Ab MQB und MLBevo:
'Berechnung siehe Lastenheft 'End-to-End Kommunikationsabsicherung''

Endwerte siehe Begleitdokument 'S-PDU Kennungsfolgen'

CRC/BZ für Mani";
CM_ SG_ 2463978662 STS2_Alarm_Blinker "Blinkeransteuerung für Carfinder und VTS Fahrzeugauffindung im Diebstahlfall.";
CM_ SG_ 2463978662 STS2_Alarm_still "VTS hat einen Alarm erkannt. Alarm ist aber noch nicht bestätigt.";
CM_ SG_ 2463978662 STS2_Anlassersperre "Wiederstartverhinderung (Anlassersperre)";
CM_ SG_ 2463978662 STS2_Car_not_under_theft "Abweichender individueller Init-Wert = 1 (Standardkodierung = 0)";
CM_ SG_ 2463978662 STS2_Car_under_theft "Fehlende Beschreibung (Import)";
CM_ SG_ 2463978662 STS2_Door_Lock "Remote Door lock angefordert: ZV zu/verriegeln";
CM_ SG_ 2463978662 STS2_Fahrlicht "statisch oder auch mit Blink_modi für interm. Fahrlicht";
CM_ SG_ 2463978662 STS2_Laderelais "Signal für die Auswertung zur Anzeige der Batterie-Schwach-Anzeige im Kombi";
CM_ SG_ 2463978662 STS2_Leerlaufschaltung "Versetzt das Fahrzeug in einen Zustand in dem es nicht mehr auf EGas-Anforderungen reagiert";
CM_ SG_ 2463978662 STS2_Notstart "Signal zeigt an, dass ein Notstart erfolgte.";
CM_ SG_ 2463978662 STS2_Privatsphaere "Steuert die Sichtbarkeit des Privatsphaere-Menues im ZR/MIB.";
CM_ SG_ 2463978662 STS2_Signalhorn "Versehrte, Fahrschule oder Taxi (bei Alarm)";
CM_ SG_ 2463978662 STS2_Spiegel_Anklappen "Anklappen der Außenspiegel über Remote MOD Anforderung";
CM_ SG_ 2463978662 STS2_Standlicht "statisch oder auch mit Blink_modi für Taxialarm";
CM_ SG_ 2463978662 STS2_Summer "Warnsummer für Funkhauptschalter und Fahrschulpedal";
CM_ SG_ 2463978662 STS2_Texte "Nummer des Textes die im Kombi angezeigt werden soll.

Signalwert ---- Meldungstext Audi ---- Meldungstext PAG:
0x0, kein_Text ---- kein Text ---- kein Text
0x1, Text_01 ---- kein Text ---- Driver Card nicht erkannt
0x2, Text_02 ---- Ortungsassistent";
CM_ SG_ 2463978662 STS2_Typencodierung "Typcodierung Schnittstelle für Tracking Systeme";

CM_ SG_ 1172 GW_STS2_Privatsphaere "Übertraegt den Status der Privatsphaere vom ZR/MIB an das Steuergeraet VTS (STS2).";
CM_ SG_ 1172 STS_01_BZ "4bit Botschaftszähler, wird in jeder Sendebotschaft inkrementiert
";
CM_ SG_ 1172 STS_01_CRC "Für MLB:
'Berechnung siehe Lastenheft 'Kommunikationsabsicherung für FlexRay und CAN''

Ab MQB und MLBevo:
'Berechnung siehe Lastenheft 'End-to-End Kommunikationsabsicherung''

Endwerte siehe Begleitdokument 'S-PDU Kennungsfolgen'";
CM_ SG_ 1172 STS_Alarm_Blinker "Taxialarmblinken, wie DWA ohne Fanfare";
CM_ SG_ 1172 STS_Alarm_still "VTS hat einen Alarm erkannt. Alarm ist aber noch nicht bestätigt.";
CM_ SG_ 1172 STS_Anlassersperre "Wiederstartverhinderung (Anlassersperre)";
CM_ SG_ 1172 STS_Door_Lock "Remote Door lock angefordert: ZV zu/verriegeln";
CM_ SG_ 1172 STS_Fahrlicht "statisch oder auch mit Blink_modi für interm. Fahrlicht";
CM_ SG_ 1172 STS_Laderelais "Signal für die Auswertung zur Anzeige der Batterie-Schwach-Anzeige im Kombi ";
CM_ SG_ 1172 STS_Leerlaufschaltung "Versetzt das Fahrzeug in einen Zustand in dem es nicht mehr auf EGas-Anforderungen reagiert";
CM_ SG_ 1172 STS_LIN_aktiv "Tracking System über LIN";
CM_ SG_ 1172 STS_Notstart "Signal zeigt an, dass ein Notstart erfolgte.";
CM_ SG_ 1172 STS_Signalhorn "Versehrte, Fahrschule oder Taxi (bei Alarm)";
CM_ SG_ 1172 STS_Spiegel_Anklappen "Anklappen der Außenspiegel über Remote MOD Anforderung";
CM_ SG_ 1172 STS_Standlicht "statisch oder auch mit Blink_modi für Taxialarm";
CM_ SG_ 1172 STS_Summer "Warnsummer für Funkhauptschalter und Fahrschulpedal";
CM_ SG_ 1172 STS_Texte "Nummer des Textes die im Kombi angezeigt werden soll.

Signalwert ---- Meldungstext Audi ---- Meldungstext PAG:
0x0, kein_Text ---- kein Text ---- kein Text
0x1, Text_01 ---- kein Text ---- Driver Card nicht erkannt
0x2, Text_02 ---- Ortungsassistent";
CM_ SG_ 1172 STS_Typencodierung "Typcodierung Schnittstelle für Tracking Systeme
";

CM_ SG_ 1413 GW_KD_Fehler "Kundendienstfehlerbit Gateway zur Anzeige eines im Gateway abgelegten Fehlerspeichereintrages.";
CM_ SG_ 1413 SI_BUS_01 "MQB/MQB_A0/PQ26: ACAN
MQB2020: ACAN(FD)
MLBevo: HCAN
E3_Volumen: ACAN(FD)
MQBw_Baseline: ACAN(FD)";
CM_ SG_ 1413 SI_BUS_02 "MQB/MQB A0 Standard+, High: FCAN
MQB2020: FCAN(FD)
MLBevo: Frei
E3_Volumen: FCAN(FD)
MQBw_Baseline: FCAN(FD)";
CM_ SG_ 1413 SI_BUS_03 "MQB/MQB A0/PQ26: KCAN
MQB2020: KCAN
MLBevo: KCAN
E3_Volumen: KCAN(HS) / K2CAN(FD) (Buskopplung)
MQBw_Baseline: KCAN(HS)";
CM_ SG_ 1413 SI_BUS_04 "MQB/MQB A0 Standard+, High: ICAN
MQB2020: ICAN(HS)
MLBevo: ICAN
E3_Volumen: ABCAN(FD)
MQBw_Baseline: ICAN(HS)";
CM_ SG_ 1413 SI_BUS_05 "MQB/MQB A0/PQ26: DiagCAN
MQB2020: DiagCAN(FD)
MLBevo: DiagCAN
E3_Volumen: DiagCAN(FD)
MQBw_Baseline: DiagCAN(FD)";
CM_ SG_ 1413 SI_BUS_06 "MQB/MQB A0/PQ26: ECAN
MQB2020: FASCAN(FD)
MLBevo: ECAN
E3_Volumen: FASCAN_1(FD)
MQBw_Baseline: FASCAN_1(FD)";
CM_ SG_ 1413 SI_BUS_07 "MQB: LIN1 (Energie)
MQB2020: LIN1 (Energie)
MLBevo: LIN1 (Energie)
E3_Volumen: LIN 1 (Energie)
MQBw_Baseline: LIN1 (Energie)";
CM_ SG_ 1413 SI_BUS_08 "MQB: LIN2 (MFL)
MQB2020: LIN2 (MFL)
MLBevo: LIN2 (MFL)
E3_Volumen: LIN2 (MFL)
MQBw_Baseline: LIN2 (MFL)";
CM_ SG_ 1413 SI_BUS_09 "MQB: LIN3 (unbelegt)
MQB2020: LIN3 (Uhr/FES)
MLBevo: LIN3 (Energie2)
MEB: LIN3
E³ 1.1 UNECE: MDKCAN";
CM_ SG_ 1413 SI_BUS_10 "MLBevo: Flexray
MQB2020: MCAN
MQBw_Baseline: FASCAN_2(FD)
E³ 1.1 UNECE: FASCAN_2(FD)";
CM_ SG_ 1413 SI_BUS_11 "MLBevo: Ethernet
MEB: LIN4";
CM_ SG_ 1413 SI_BUS_12 "MQB: unbelegt
MLBevo: K2CAN
E3_Volumen: MFLCAN
MQBw_Baseline: K2CAN(FD)";
CM_ SG_ 1413 SI_BUS_13 "MQB: unbelegt
MLBevo: DCAN
MEB: CCAN
MQBw_Baseline: K3CAN(FD)";
CM_ SG_ 1413 SI_BUS_14 "MQB/MQB A0: unbelegt
MQB2020: HCAN
MLBevo: CCAN
E3_Volumen: EVCAN(FD)
MQBw_Baseline: EVCANFD(FD)";
CM_ SG_ 1413 SI_BUS_15 "MQB: frei
MQB2020: frei
MLBevo: frei
MEB: AFSCAN";
CM_ SG_ 1413 SI_Bus_Identifikation "Das Signal identifiziert den Bus eindeutig. Das Signal ist konstant auf jedem Bus.
Der Signalwert entspricht dem Wert 'Busnummer' aus der VW80127 Gateway_component_list_databus_identification (0x2A2D) 'Bus-Identifier'.";
CM_ SG_ 1413 SI_CAB "CAB = Clusteraktivbits 
(Verwendung nur für Empfänger die nicht den AutoSar-SSW Stack implementiert haben)";
CM_ SG_ 1413 SI_Diagnose_Aktiv "Gibt an ob Diagnose-Botschaften empfangen werden und somit eine Diagnose aktiv ist.
MQB: Gibt an ob Diagnose-Bus Botschaften empfangen werden und somit eine Diagnose aktiv ist.";
CM_ SG_ 1413 SI_NWDF "Netzwerk-Diagnose Freigebe zur zentralen Aktivierung der Netzwerkdiagnose";
CM_ SG_ 1413 SI_NWDF_gueltig "Gültigkeitsbit zu SI_NWDF gemäß Lastenheft: Zentrale Aktivierung Netzwerkdiagnose";
CM_ SG_ 1413 SI_QRS_Mode "Messmodus Quick-Ruhestrom";
CM_ SG_ 1413 SI_Sammel_SG_Fehler "Anzahl der gesetzten KD-Fehler direkt angeschlossener Steuergeräte der DK3 und DK4 gemäß 80127.
Hinweis: Ein Subbusmaster stellt nur die gesammelte Information der an ihn angeschlossenen Steuergeräte der DK3 und DK4 zur Verfügung.

Für ServiceKey Auswe";
CM_ SG_ 1413 SI_Sammelfehler "Sammelfehlermeldung zur Anzeige im Kombi - siehe Spez. Sammelfehlermeldung
Hinweis: Einzelne Steuergeräte können zur Anpassung an den Produktionsprozess im Gateway auskodiert werden!";
CM_ SG_ 1413 SI_T_Mode "0x0: Transportmodus nicht aktiv
0x1: Transportmodus aktiv";
CM_ SG_ 1413 SI_T_Schutz "Transportschutz-Signal, das bei Transportmodus und Motorlauf aktiv bleibt
0x0: Transportschutz nicht aktiv
0x1: Transportschutz aktiv";

CM_ SG_ 1716 VIN_01_MUX "Achtung:
Die Botschaft ist nicht linear gemultiplext!!!
Sondern 0,1,0,2,0, usw.";
CM_ SG_ 1716 VIN_1 "Initwert:
0x2D bei Fahrzeugen mit Wegfahrsperrengeneration >= 5 
0x58 bei Fahrzeugen mit Wegfahrsperrengeneration < 5 (z.B. WFS-4)";
CM_ SG_ 1716 VIN_10 "Initwert:
0x2D bei Fahrzeugen mit Wegfahrsperrengeneration >= 5 
0x58 bei Fahrzeugen mit Wegfahrsperrengeneration < 5 (z.B. WFS-4)";
CM_ SG_ 1716 VIN_11 "Initwert:
0x2D bei Fahrzeugen mit Wegfahrsperrengeneration >= 5 
0x58 bei Fahrzeugen mit Wegfahrsperrengeneration < 5 (z.B. WFS-4)";
CM_ SG_ 1716 VIN_12 "Initwert:
0x2D bei Fahrzeugen mit Wegfahrsperrengeneration >= 5 
0x58 bei Fahrzeugen mit Wegfahrsperrengeneration < 5 (z.B. WFS-4)";
CM_ SG_ 1716 VIN_13 "Initwert:
0x2D bei Fahrzeugen mit Wegfahrsperrengeneration >= 5 
0x58 bei Fahrzeugen mit Wegfahrsperrengeneration < 5 (z.B. WFS-4)";
CM_ SG_ 1716 VIN_14 "Initwert:
0x2D bei Fahrzeugen mit Wegfahrsperrengeneration >= 5 
0x58 bei Fahrzeugen mit Wegfahrsperrengeneration < 5 (z.B. WFS-4)";
CM_ SG_ 1716 VIN_15 "Initwert:
0x2D bei Fahrzeugen mit Wegfahrsperrengeneration >= 5 
0x58 bei Fahrzeugen mit Wegfahrsperrengeneration < 5 (z.B. WFS-4)";
CM_ SG_ 1716 VIN_16 "Initwert:
0x2D bei Fahrzeugen mit Wegfahrsperrengeneration >= 5 
0x58 bei Fahrzeugen mit Wegfahrsperrengeneration < 5 (z.B. WFS-4)";
CM_ SG_ 1716 VIN_17 "Initwert:
0x2D bei Fahrzeugen mit Wegfahrsperrengeneration >= 5 
0x58 bei Fahrzeugen mit Wegfahrsperrengeneration < 5 (z.B. WFS-4)";
CM_ SG_ 1716 VIN_2 "Initwert:
0x2D bei Fahrzeugen mit Wegfahrsperrengeneration >= 5 
0x58 bei Fahrzeugen mit Wegfahrsperrengeneration < 5 (z.B. WFS-4)";
CM_ SG_ 1716 VIN_3 "Initwert:
0x2D bei Fahrzeugen mit Wegfahrsperrengeneration >= 5 
0x58 bei Fahrzeugen mit Wegfahrsperrengeneration < 5 (z.B. WFS-4)";
CM_ SG_ 1716 VIN_4 "Initwert:
0x2D bei Fahrzeugen mit Wegfahrsperrengeneration >= 5 
0x58 bei Fahrzeugen mit Wegfahrsperrengeneration < 5 (z.B. WFS-4)";
CM_ SG_ 1716 VIN_5 "Initwert:
0x2D bei Fahrzeugen mit Wegfahrsperrengeneration >= 5 
0x58 bei Fahrzeugen mit Wegfahrsperrengeneration < 5 (z.B. WFS-4)";
CM_ SG_ 1716 VIN_6 "Initwert:
0x2D bei Fahrzeugen mit Wegfahrsperrengeneration >= 5 
0x58 bei Fahrzeugen mit Wegfahrsperrengeneration < 5 (z.B. WFS-4)";
CM_ SG_ 1716 VIN_7 "Initwert:
0x2D bei Fahrzeugen mit Wegfahrsperrengeneration >= 5 
0x58 bei Fahrzeugen mit Wegfahrsperrengeneration < 5 (z.B. WFS-4)";
CM_ SG_ 1716 VIN_8 "Initwert:
0x2D bei Fahrzeugen mit Wegfahrsperrengeneration >= 5 
0x58 bei Fahrzeugen mit Wegfahrsperrengeneration < 5 (z.B. WFS-4)";
CM_ SG_ 1716 VIN_9 "Initwert:
0x2D bei Fahrzeugen mit Wegfahrsperrengeneration >= 5 
0x58 bei Fahrzeugen mit Wegfahrsperrengeneration < 5 (z.B. WFS-4)";

CM_ SG_ 1411 BCM_FH_Freigabe "Funktionsfreigabe Fensterheber";
CM_ SG_ 1411 BCM_HSK_Freigabe "Handschuhkastenfreigabe";
CM_ SG_ 1411 BCM_Komfortfkt_Freigabe "globale Freigabe der Komfortfunktion";
CM_ SG_ 1411 BCM_Tankklappensteller_Fehler "Fehler: nicht Funktionalität des Tankklappenstellers";
CM_ SG_ 1411 BCM_Verdeck_Freigabe "Freigabe Verdeckbetrieb
";
CM_ SG_ 1411 DWA_aktiv "Status DWA  aktiv";
CM_ SG_ 1411 FBS_Warn_Schluessel_Batt "Kombi Prio Warnung Schluessel Batterie
'Bitte Schlüsselbatterie wechseln!'";
CM_ SG_ 1411 FFB_CarFinder "Car Finder Funktion (Blinken ohne zu entriegeln)";
CM_ SG_ 1411 FFB_Komfortoeffnen "Komfortoeffnen Funk
";
CM_ SG_ 1411 FFB_Komfortschliessen "Komfortschliessen Funk
";
CM_ SG_ 1411 HBFS_gesafet "HBFS Tuer gesafet.
Im Zustand Safe wird auch das Signal HBFS_verriegelt = 1 gesendet.";
CM_ SG_ 1411 HBFS_verriegelt "Verriegelungsstatus Tür";
CM_ SG_ 1411 HD_Hauptraste "SBL-Schloss (MQB/MLBevo): Drehfalle Heckdeckel
sonst (MQB): Hauptraste Heckdeckel";
CM_ SG_ 1411 HD_Vorraste "SBL_Schloss (MQB/MLBevo): Sperrklinke Heckdeckel
sonst (MQB): Vorraste Heckdeckel";
CM_ SG_ 1411 HFS_gesafet "HFS Tuer gesafet.
Im Zustand Safe wird auch das Signal HFS_verriegelt = 1 gesendet.";
CM_ SG_ 1411 HFS_verriegelt "HFS Tuer verriegelt";
CM_ SG_ 1411 IRUE_aktiv "Status Innenraumüberwachung
";
CM_ SG_ 1411 IRUE_Taster_Fkts_LED "Anforderung Funktions-LED IRUE-Taster (LED wird vom TSG angesteuert)
MQB: Bei Verbau eines einzelnen Taster zur Deaktivierung von IRUE und NGS wird dieses Signal zur Ansteuerung der Funktions-LED gesendet.";
CM_ SG_ 1411 ZV_BT_offen "gespiegeltes Bit BT_Tuer_geoeffnet TSG_BT_1 Botschaft";
CM_ SG_ 1411 ZV_Einzeltuerentriegelung "Einzeltürentriegelung ZV
";
CM_ SG_ 1411 ZV_FT_offen "gespiegeltes Bit FT_Tuer_geoeffnet TSG_FT_1 Botschaft";
CM_ SG_ 1411 ZV_gesafet_extern_ist "Istzustand: Fahrzeug aussen gesafet
";
CM_ SG_ 1411 ZV_gesafet_extern_soll "Sollzustand: Fahrzeug gesafet extern
";
CM_ SG_ 1411 ZV_HBFS_offen "gespiegeltes Bit HBFS_Tuer_geoeffnet TSG_HBFS_1 Botschaft";
CM_ SG_ 1411 ZV_HD_offen "Status Heckdeckel
";
CM_ SG_ 1411 ZV_Heckeinzelentriegelung "Heckdeckeleinzelentriegelung";
CM_ SG_ 1411 ZV_HFS_offen "gespiegeltes Bit HFS_Tuer_geoeffnet TSG_HFS_1 Botschaft";
CM_ SG_ 1411 ZV_HS_offen "Status Heckscheibe
";
CM_ SG_ 1411 ZV_ist_Zustand_verfuegbar "Verfügbarkeit IST-Zustand ZV

";
CM_ SG_ 1411 ZV_Oeffnungsmodus "Konfigurierter Oeffnungsmodus fuer ZV:
0 = globale Oeffnung (alle Tueren)
1 = ZV mit Einzeltuerentriegelung (FFB - nur Fahrertuer, Kessy - nur bediente Tuer)
2 = ZV individuell selektive Oeffnung (FFB - Fahrerseite, Kessy - bediente Tuer + Fahrertuer)";
CM_ SG_ 1411 ZV_Rollo_auf "Komfortöffnen des Dachrollos";
CM_ SG_ 1411 ZV_Rollo_zu "Komfortschließen des Dachrollos";
CM_ SG_ 1411 ZV_SAD_auf "Komfortöffnen des Schiebeausstelldaches";
CM_ SG_ 1411 ZV_SAD_zu "Komfortschließen des Schiebeausstelldaches";
CM_ SG_ 1411 ZV_SafeFunktion_aktiv "Statusübermittlung ob die Safe Funktion im Fzg. aktiv ist. Das Kombi benötigt das Signal, um den Text Safelock aktiv anzuzeigen. ";
CM_ SG_ 1411 ZV_Schluessel_Zugang "aktuelle Funkschlüsselnummer";
CM_ SG_ 1411 ZV_Tankklappe_offen "Öffnungsstatus der Tankklappe";
CM_ SG_ 1411 ZV_verriegelt_extern_ist "Istzustand: Verriegelung Fahrzeug aussen
";
CM_ SG_ 1411 ZV_verriegelt_extern_soll "Sollzustand: Verriegelung Fahrzeug aussen
";
CM_ SG_ 1411 ZV_verriegelt_intern_ist "Istzustand: Verriegelung Fahrzeug innen
";
CM_ SG_ 1411 ZV_verriegelt_intern_soll "Sollzustand: Verriegelung Fahrzeug innen
";
CM_ SG_ 1411 ZV_verriegelt_soll "Fahrzeug Gesamtverriegelungsstatus Sollzustand für Ladestecker- und Ladeklappenverriegelung. ";
BA_DEF_REL_ BU_SG_REL_  "GenSigTimeoutTime" INT 0 65535;
BA_DEF_ BO_  "DiagRequest" ENUM "No", "Yes";
BA_DEF_ BO_  "DiagResponse" ENUM "No", "Yes";
BA_DEF_ BO_  "DiagState" ENUM "No", "Yes";
BA_DEF_ BO_  "GenMsgChkConstant" HEX 0 4095;
BA_DEF_ BO_  "GenMsgCycleTime" INT 0 65535;
BA_DEF_ BO_  "GenMsgCycleTimeFast" INT 0 65535;
BA_DEF_ BO_  "GenMsgDelayTime" INT 0 100000;
BA_DEF_ BO_  "GenMsgILSupport" ENUM "No", "Yes";
BA_DEF_ BO_  "GenMsgNrOfRepetition" INT 0 100;
BA_DEF_ BO_  "GenMsgPDUConstants" STRING;
BA_DEF_ BO_  "GenMsgSendType" ENUM "Cyclic", "not_used", "not_used", "not_used", "not_used", "not_used", "not_used", "IfActive", "NoMsgSendType";
BA_DEF_ BO_  "GenMsgStartDelayTime" INT 0 100000;
BA_DEF_ BO_  "NmMessage" ENUM "No", "Yes";
BA_DEF_ BO_  "NmhMessage" ENUM "No", "Yes";
BA_DEF_ BO_  "MsgType" ENUM "Application", "NM ", "NMH", "TP2.0", "ISO-TP ", "BAP", "EID", "KS", "XCP_PRE_CONFIGURED", "XCP_RUNTIME_CONFIGURED";
BA_DEF_ BO_  "VAGTP20_API" HEX 0 255;
BA_DEF_ BO_  "VAGTP20_DynConnection" ENUM "No", "Yes";
BA_DEF_ BO_  "VAGTP20_DynSetup" ENUM "No", "Yes";
BA_DEF_ BO_  "VAGTP20_StatConnection" ENUM "No", "Yes";
BA_DEF_ SG_  "GenSigActiveRepetitions" INT -2147483648 2147483647;
BA_DEF_ SG_  "GenSigSendType" ENUM "Cyclic", "OnWrite", "OnWriteWithRepetition", "OnChange", "OnChangeWithRepetition", "IfActive", "IfActiveWithRepetition", "NoSigSendType", "OnChangeAndIfActive", "OnChangeAndIfActiveWithRepetition";
BA_DEF_ SG_  "GenSigStartValue" INT -2147483648 2147483647;
BA_DEF_ SG_  "NWM-WakeupAllowed" ENUM "No", "Yes";
BA_DEF_ SG_  "GenSigFuncType" ENUM "NoFunction", "MsgCounter", "CRC-8", "XOR", "XOR-2", "DatedBit", "SW-Kl15", "CHK", "Constant", "Protocol", "CRC-8-SAE_J1850", "CRC-32", "DataLength", "DataID", "MsgCounter16", "SOK-Signatur", "Cluster";
BA_DEF_ SG_  "GenSigSwitchedByIgnition" ENUM "No", "Yes";
BA_DEF_ SG_  "Fehlerwert" HEX 0 2147483647;
BA_DEF_ SG_  "GenSigMissingSourceValue" HEX 0 2147483647;
BA_DEF_DEF_REL_  "GenSigTimeoutTime" 0;
BA_DEF_DEF_  "DiagRequest" "No";
BA_DEF_DEF_  "DiagResponse" "No";
BA_DEF_DEF_  "DiagState" "No";
BA_DEF_DEF_  "GenMsgChkConstant" 0;
BA_DEF_DEF_  "GenMsgCycleTime" 0;
BA_DEF_DEF_  "GenMsgCycleTimeFast" 0;
BA_DEF_DEF_  "GenMsgDelayTime" 0;
BA_DEF_DEF_  "GenMsgILSupport" "No";
BA_DEF_DEF_  "GenMsgNrOfRepetition" 0;
BA_DEF_DEF_  "GenMsgPDUConstants" "";
BA_DEF_DEF_  "GenMsgSendType" "NoMsgSendType";
BA_DEF_DEF_  "GenMsgStartDelayTime" 0;
BA_DEF_DEF_  "NmMessage" "No";
BA_DEF_DEF_  "NmhMessage" "No";
BA_DEF_DEF_  "MsgType" "Application";
BA_DEF_DEF_  "VAGTP20_API" 0;
BA_DEF_DEF_  "VAGTP20_DynConnection" "No";
BA_DEF_DEF_  "VAGTP20_DynSetup" "No";
BA_DEF_DEF_  "VAGTP20_StatConnection" "No";
BA_DEF_DEF_  "GenSigActiveRepetitions" 0;
BA_DEF_DEF_  "GenSigSendType" "NoSigSendType";
BA_DEF_DEF_  "GenSigStartValue" 0;
BA_DEF_DEF_  "NWM-WakeupAllowed" "No";
BA_DEF_DEF_  "GenSigFuncType" "NoFunction";
BA_DEF_DEF_  "GenSigSwitchedByIgnition" "Yes";
BA_DEF_DEF_  "Fehlerwert" 0;
BA_DEF_DEF_  "GenSigMissingSourceValue" 0;
BA_ "GenMsgChkConstant" BO_ 1601 71;
BA_ "GenMsgCycleTime" BO_ 1601 960;
BA_ "GenMsgILSupport" BO_ 1601 1;
BA_ "GenMsgPDUConstants" BO_ 1601 "0x47,0x47,0x47,0x47,0x47,0x47,0x47,0x47,0x47,0x47,0x47,0x47,0x47,0x47,0x47,0x47";
BA_ "GenMsgSendType" BO_ 1601 0;
BA_ "GenMsgCycleTime" BO_ 1156 200;
BA_ "GenMsgILSupport" BO_ 1156 1;
BA_ "GenMsgSendType" BO_ 1156 0;
BA_ "GenMsgCycleTime" BO_ 1157 200;
BA_ "GenMsgILSupport" BO_ 1157 1;
BA_ "GenMsgSendType" BO_ 1157 0;
BA_ "GenMsgCycleTime" BO_ 1158 200;
BA_ "GenMsgILSupport" BO_ 1158 1;
BA_ "GenMsgSendType" BO_ 1158 0;
BA_ "GenMsgCycleTime" BO_ 2589283496 500;
BA_ "GenMsgILSupport" BO_ 2589283496 1;
BA_ "GenMsgSendType" BO_ 2589283496 0;
BA_ "GenMsgCycleTime" BO_ 2600468496 200;
BA_ "GenMsgCycleTimeFast" BO_ 2600468496 10;
BA_ "GenMsgSendType" BO_ 2600468496 7;
BA_ "NmhMessage" BO_ 2600468496 1;
BA_ "MsgType" BO_ 2600468496 2;
BA_ "GenMsgCycleTime" BO_ 2600468489 200;
BA_ "GenMsgCycleTimeFast" BO_ 2600468489 10;
BA_ "GenMsgNrOfRepetition" BO_ 2600468489 3;
BA_ "GenMsgSendType" BO_ 2600468489 7;
BA_ "NmhMessage" BO_ 2600468489 1;
BA_ "MsgType" BO_ 2600468489 2;
BA_ "GenMsgCycleTime" BO_ 2600468720 200;
BA_ "GenMsgCycleTimeFast" BO_ 2600468720 10;
BA_ "GenMsgSendType" BO_ 2600468720 7;
BA_ "NmhMessage" BO_ 2600468720 1;
BA_ "MsgType" BO_ 2600468720 2;
BA_ "GenMsgCycleTime" BO_ 1635 100;
BA_ "GenMsgILSupport" BO_ 1635 1;
BA_ "GenMsgPDUConstants" BO_ 1635 "0x7d,0xba,0x97,0x94,0x5a,0x4a,0xeb,0xd4,0x6c,0x28,0x54,0x81,0xc7,0x1c,0x25,0x2a";
BA_ "GenMsgSendType" BO_ 1635 0;
BA_ "GenMsgStartDelayTime" BO_ 1635 10;
BA_ "GenMsgCycleTime" BO_ 2589283656 960;
BA_ "GenMsgDelayTime" BO_ 2589283656 160;
BA_ "GenMsgILSupport" BO_ 2589283656 1;
BA_ "GenMsgPDUConstants" BO_ 2589283656 "0xee,0xcc,0x2f,0x27,0x93,0x0c,0x45,0x97,0x87,0x2e,0xec,0x3b,0xd3,0x35,0xcb,0x4a";
BA_ "GenMsgSendType" BO_ 2589283656 0;
BA_ "GenMsgStartDelayTime" BO_ 2589283656 160;
BA_ "GenMsgCycleTime" BO_ 2527679670 1000;
BA_ "GenMsgCycleTimeFast" BO_ 2527679670 200;
BA_ "GenMsgDelayTime" BO_ 2527679670 100;
BA_ "GenMsgILSupport" BO_ 2527679670 1;
BA_ "GenMsgNrOfRepetition" BO_ 2527679670 5;
BA_ "GenMsgSendType" BO_ 2527679670 0;
BA_ "GenMsgCycleTime" BO_ 2463978757 1000;
BA_ "GenMsgDelayTime" BO_ 2463978757 20;
BA_ "GenMsgILSupport" BO_ 2463978757 1;
BA_ "GenMsgSendType" BO_ 2463978757 0;
BA_ "GenMsgCycleTime" BO_ 1122 150;
BA_ "GenMsgILSupport" BO_ 1122 1;
BA_ "GenMsgSendType" BO_ 1122 0;
BA_ "GenMsgCycleTime" BO_ 1527 500;
BA_ "GenMsgDelayTime" BO_ 1527 100;
BA_ "GenMsgILSupport" BO_ 1527 1;
BA_ "GenMsgSendType" BO_ 1527 0;
BA_ "GenMsgStartDelayTime" BO_ 1527 85;
BA_ "GenMsgCycleTime" BO_ 124 10;
BA_ "GenMsgILSupport" BO_ 124 1;
BA_ "GenMsgSendType" BO_ 124 0;
BA_ "GenMsgCycleTime" BO_ 378 10;
BA_ "GenMsgILSupport" BO_ 378 1;
BA_ "GenMsgSendType" BO_ 378 0;
BA_ "GenMsgCycleTime" BO_ 424 20;
BA_ "GenMsgILSupport" BO_ 424 1;
BA_ "GenMsgPDUConstants" BO_ 424 "0x11,0x17,0xbb,0xaa,0xd0,0x83,0xe1,0x8e,0xa3,0x4d,0xef,0x50,0x88,0xa5,0x22,0xf6";
BA_ "GenMsgSendType" BO_ 424 0;
BA_ "GenMsgChkConstant" BO_ 133 133;
BA_ "GenMsgCycleTime" BO_ 133 20;
BA_ "GenMsgILSupport" BO_ 133 1;
BA_ "GenMsgPDUConstants" BO_ 133 "0x85,0x85,0x85,0x85,0x85,0x85,0x85,0x85,0x85,0x85,0x85,0x85,0x85,0x85,0x85,0x85";
BA_ "GenMsgSendType" BO_ 133 0;
BA_ "GenMsgCycleTime" BO_ 2589283634 1000;
BA_ "GenMsgDelayTime" BO_ 2589283634 100;
BA_ "GenMsgILSupport" BO_ 2589283634 1;
BA_ "GenMsgSendType" BO_ 2589283634 0;
BA_ "GenMsgCycleTime" BO_ 2527679657 1000;
BA_ "GenMsgDelayTime" BO_ 2527679657 100;
BA_ "GenMsgILSupport" BO_ 2527679657 1;
BA_ "GenMsgSendType" BO_ 2527679657 0;
BA_ "GenMsgChkConstant" BO_ 2463978662 144;
BA_ "GenMsgCycleTime" BO_ 2463978662 200;
BA_ "GenMsgDelayTime" BO_ 2463978662 20;
BA_ "GenMsgILSupport" BO_ 2463978662 1;
BA_ "GenMsgPDUConstants" BO_ 2463978662 "0x90,0x90,0x90,0x90,0x90,0x90,0x90,0x90,0x90,0x90,0x90,0x90,0x90,0x90,0x90,0x90";
BA_ "GenMsgSendType" BO_ 2463978662 0;
BA_ "GenMsgChkConstant" BO_ 1172 144;
BA_ "GenMsgCycleTime" BO_ 1172 200;
BA_ "GenMsgDelayTime" BO_ 1172 20;
BA_ "GenMsgILSupport" BO_ 1172 1;
BA_ "GenMsgPDUConstants" BO_ 1172 "0x90,0x90,0x90,0x90,0x90,0x90,0x90,0x90,0x90,0x90,0x90,0x90,0x90,0x90,0x90,0x90";
BA_ "GenMsgSendType" BO_ 1172 0;
BA_ "GenMsgCycleTime" BO_ 1413 1000;
BA_ "GenMsgDelayTime" BO_ 1413 10;
BA_ "GenMsgILSupport" BO_ 1413 1;
BA_ "GenMsgSendType" BO_ 1413 0;
BA_ "GenMsgStartDelayTime" BO_ 1413 85;
BA_ "GenMsgCycleTime" BO_ 1716 200;
BA_ "GenMsgILSupport" BO_ 1716 1;
BA_ "GenMsgSendType" BO_ 1716 0;
BA_ "MsgType" BO_ 2617196032 6;
BA_ "MsgType" BO_ 2617196033 6;
BA_ "MsgType" BO_ 2616997632 6;
BA_ "MsgType" BO_ 2616997633 6;
BA_ "GenMsgCycleTime" BO_ 1411 200;
BA_ "GenMsgCycleTimeFast" BO_ 1411 50;
BA_ "GenMsgDelayTime" BO_ 1411 50;
BA_ "GenMsgILSupport" BO_ 1411 1;
BA_ "GenMsgNrOfRepetition" BO_ 1411 5;
BA_ "GenMsgSendType" BO_ 1411 0;
BA_ "GenSigSendType" SG_ 1601 MO_Ansaugsystem 0;
BA_ "GenSigFuncType" SG_ 1601 MO_Ansaugsystem 8;
BA_ "GenSigSwitchedByIgnition" SG_ 1601 MO_Ansaugsystem 0;
BA_ "GenSigSendType" SG_ 1601 MO_Anzahl_Zyl 0;
BA_ "GenSigFuncType" SG_ 1601 MO_Anzahl_Zyl 8;
BA_ "GenSigSwitchedByIgnition" SG_ 1601 MO_Anzahl_Zyl 0;
BA_ "GenSigSendType" SG_ 1601 MO_Anzeige_StSt_gueltig 0;
BA_ "GenSigSwitchedByIgnition" SG_ 1601 MO_Anzeige_StSt_gueltig 0;
BA_ "GenSigSendType" SG_ 1601 MO_Code 0;
BA_ "GenSigSwitchedByIgnition" SG_ 1601 MO_Code 0;
BA_ "GenSigSendType" SG_ 1601 MO_DPF_verbaut 0;
BA_ "GenSigFuncType" SG_ 1601 MO_DPF_verbaut 8;
BA_ "GenSigSwitchedByIgnition" SG_ 1601 MO_DPF_verbaut 0;
BA_ "GenSigSendType" SG_ 1601 MO_Faktor_Momente_02 0;
BA_ "GenSigFuncType" SG_ 1601 MO_Faktor_Momente_02 8;
BA_ "GenSigSwitchedByIgnition" SG_ 1601 MO_Faktor_Momente_02 0;
BA_ "GenSigSendType" SG_ 1601 MO_Getriebe_Code 0;
BA_ "GenSigSwitchedByIgnition" SG_ 1601 MO_Getriebe_Code 0;
BA_ "GenSigSendType" SG_ 1601 MO_Hubraum 0;
BA_ "GenSigFuncType" SG_ 1601 MO_Hubraum 8;
BA_ "GenSigSwitchedByIgnition" SG_ 1601 MO_Hubraum 0;
BA_ "GenSigSendType" SG_ 1601 MO_Hybridfahrzeug 0;
BA_ "GenSigFuncType" SG_ 1601 MO_Hybridfahrzeug 8;
BA_ "GenSigSwitchedByIgnition" SG_ 1601 MO_Hybridfahrzeug 0;
BA_ "GenSigSendType" SG_ 1601 MO_Kraftstoffart 0;
BA_ "GenSigFuncType" SG_ 1601 MO_Kraftstoffart 8;
BA_ "GenSigSwitchedByIgnition" SG_ 1601 MO_Kraftstoffart 0;
BA_ "GenSigSendType" SG_ 1601 MO_Leistung 0;
BA_ "GenSigSwitchedByIgnition" SG_ 1601 MO_Leistung 0;
BA_ "GenSigSendType" SG_ 1601 MO_OBD_Typ 0;
BA_ "GenSigSwitchedByIgnition" SG_ 1601 MO_OBD_Typ 0;
BA_ "GenSigSendType" SG_ 1601 MO_StartStopp_Codiert 0;
BA_ "GenSigFuncType" SG_ 1601 MO_StartStopp_Codiert 8;
BA_ "GenSigSwitchedByIgnition" SG_ 1601 MO_StartStopp_Codiert 0;
BA_ "GenSigSendType" SG_ 1601 Motor_Code_01_BZ 0;
BA_ "GenSigFuncType" SG_ 1601 Motor_Code_01_BZ 1;
BA_ "GenSigSwitchedByIgnition" SG_ 1601 Motor_Code_01_BZ 0;
BA_ "GenSigSendType" SG_ 1601 Motor_Code_01_CRC 0;
BA_ "GenSigFuncType" SG_ 1601 Motor_Code_01_CRC 2;
BA_ "GenSigSwitchedByIgnition" SG_ 1601 Motor_Code_01_CRC 0;
BA_ "GenSigSendType" SG_ 1601 TSK_Codierung 0;
BA_ "GenSigStartValue" SG_ 1601 TSK_Codierung 7;
BA_ "GenSigSwitchedByIgnition" SG_ 1601 TSK_Codierung 0;
BA_ "GenSigSendType" SG_ 1156 ND_GDOP 0;
BA_ "GenSigStartValue" SG_ 1156 ND_GDOP 1022;
BA_ "GenSigSwitchedByIgnition" SG_ 1156 ND_GDOP 0;
BA_ "Fehlerwert" SG_ 1156 ND_GDOP 1023;
BA_ "GenSigSendType" SG_ 1156 ND_HDOP 0;
BA_ "GenSigStartValue" SG_ 1156 ND_HDOP 1022;
BA_ "GenSigSwitchedByIgnition" SG_ 1156 ND_HDOP 0;
BA_ "Fehlerwert" SG_ 1156 ND_HDOP 1023;
BA_ "GenSigSendType" SG_ 1156 ND_Heading 0;
BA_ "GenSigStartValue" SG_ 1156 ND_Heading 4094;
BA_ "GenSigSwitchedByIgnition" SG_ 1156 ND_Heading 0;
BA_ "Fehlerwert" SG_ 1156 ND_Heading 4095;
BA_ "GenSigSendType" SG_ 1156 ND_Init 0;
BA_ "GenSigSwitchedByIgnition" SG_ 1156 ND_Init 0;
BA_ "GenSigSendType" SG_ 1156 ND_PDOP 0;
BA_ "GenSigStartValue" SG_ 1156 ND_PDOP 1022;
BA_ "GenSigSwitchedByIgnition" SG_ 1156 ND_PDOP 0;
BA_ "Fehlerwert" SG_ 1156 ND_PDOP 1023;
BA_ "GenSigSendType" SG_ 1156 ND_TDOP 0;
BA_ "GenSigStartValue" SG_ 1156 ND_TDOP 1022;
BA_ "GenSigSwitchedByIgnition" SG_ 1156 ND_TDOP 0;
BA_ "Fehlerwert" SG_ 1156 ND_TDOP 1023;
BA_ "GenSigSendType" SG_ 1156 ND_VDOP 0;
BA_ "GenSigStartValue" SG_ 1156 ND_VDOP 1022;
BA_ "GenSigSwitchedByIgnition" SG_ 1156 ND_VDOP 0;
BA_ "Fehlerwert" SG_ 1156 ND_VDOP 1023;
BA_ "GenSigSendType" SG_ 1157 ND_SatInUse 0;
BA_ "GenSigStartValue" SG_ 1157 ND_SatInUse 30;
BA_ "GenSigSwitchedByIgnition" SG_ 1157 ND_SatInUse 0;
BA_ "Fehlerwert" SG_ 1157 ND_SatInUse 31;
BA_ "GenSigSendType" SG_ 1157 ND_SatInView 0;
BA_ "GenSigStartValue" SG_ 1157 ND_SatInView 30;
BA_ "GenSigSwitchedByIgnition" SG_ 1157 ND_SatInView 0;
BA_ "Fehlerwert" SG_ 1157 ND_SatInView 31;
BA_ "GenSigSendType" SG_ 1157 ND_UTC 0;
BA_ "GenSigSwitchedByIgnition" SG_ 1157 ND_UTC 0;
BA_ "GenSigSendType" SG_ 1157 NP_Altitude 0;
BA_ "GenSigStartValue" SG_ 1157 NP_Altitude 4094;
BA_ "GenSigSwitchedByIgnition" SG_ 1157 NP_Altitude 0;
BA_ "Fehlerwert" SG_ 1157 NP_Altitude 4095;
BA_ "GenSigSendType" SG_ 1157 POS_Guete_horizontal 0;
BA_ "GenSigStartValue" SG_ 1157 POS_Guete_horizontal 126;
BA_ "GenSigSwitchedByIgnition" SG_ 1157 POS_Guete_horizontal 0;
BA_ "Fehlerwert" SG_ 1157 POS_Guete_horizontal 127;
BA_ "GenSigSendType" SG_ 1157 POS_Guete_horizontal_verfuegbar 0;
BA_ "GenSigSwitchedByIgnition" SG_ 1157 POS_Guete_horizontal_verfuegbar 0;
BA_ "GenSigSendType" SG_ 1158 NP_Fix 0;
BA_ "GenSigSwitchedByIgnition" SG_ 1158 NP_Fix 0;
BA_ "GenSigSendType" SG_ 1158 NP_LatDegree 0;
BA_ "GenSigStartValue" SG_ 1158 NP_LatDegree 134217726;
BA_ "GenSigSwitchedByIgnition" SG_ 1158 NP_LatDegree 0;
BA_ "Fehlerwert" SG_ 1158 NP_LatDegree 134217727;
BA_ "GenSigSendType" SG_ 1158 NP_LatDirection 0;
BA_ "GenSigStartValue" SG_ 1158 NP_LatDirection 1;
BA_ "GenSigSwitchedByIgnition" SG_ 1158 NP_LatDirection 0;
BA_ "GenSigSendType" SG_ 1158 NP_LongDegree 0;
BA_ "GenSigStartValue" SG_ 1158 NP_LongDegree 268435454;
BA_ "GenSigSwitchedByIgnition" SG_ 1158 NP_LongDegree 0;
BA_ "Fehlerwert" SG_ 1158 NP_LongDegree 268435455;
BA_ "GenSigSendType" SG_ 1158 NP_LongDirection 0;
BA_ "GenSigStartValue" SG_ 1158 NP_LongDirection 1;
BA_ "GenSigSwitchedByIgnition" SG_ 1158 NP_LongDirection 0;
BA_ "GenSigSendType" SG_ 1158 NP_Sat 0;
BA_ "GenSigStartValue" SG_ 1158 NP_Sat 30;
BA_ "GenSigSwitchedByIgnition" SG_ 1158 NP_Sat 0;
BA_ "Fehlerwert" SG_ 1158 NP_Sat 31;
BA_ "GenSigSwitchedByIgnition" SG_ 2589283496 POS_Heading 0;
BA_ "GenSigSwitchedByIgnition" SG_ 2589283496 POS_Heading_Trust 0;
BA_ "Fehlerwert" SG_ 2589283496 POS_Heading_Trust 3;
BA_ "GenSigSwitchedByIgnition" SG_ 2589283496 POS_Last_GPS_Sync 0;
BA_ "GenSigStartValue" SG_ 2589283496 POS_LatDegree 134217726;
BA_ "GenSigSwitchedByIgnition" SG_ 2589283496 POS_LatDegree 0;
BA_ "Fehlerwert" SG_ 2589283496 POS_LatDegree 134217727;
BA_ "GenSigSwitchedByIgnition" SG_ 2589283496 POS_LatDirection 0;
BA_ "GenSigStartValue" SG_ 2589283496 POS_LongDegree 268435454;
BA_ "GenSigSwitchedByIgnition" SG_ 2589283496 POS_LongDegree 0;
BA_ "Fehlerwert" SG_ 2589283496 POS_LongDegree 268435455;
BA_ "GenSigSwitchedByIgnition" SG_ 2589283496 POS_LongDirection 0;
BA_ "GenSigSendType" SG_ 2589283496 POS_MUX 0;
BA_ "GenSigStartValue" SG_ 2589283496 POS_MUX 3;
BA_ "GenSigSwitchedByIgnition" SG_ 2589283496 POS_MUX 0;
BA_ "GenSigSendType" SG_ 2589283496 POS_ODD_EVEN 0;
BA_ "GenSigSwitchedByIgnition" SG_ 2589283496 POS_ODD_EVEN 0;
BA_ "GenSigSwitchedByIgnition" SG_ 2589283496 POS_PosStati 0;
BA_ "GenSigSwitchedByIgnition" SG_ 2589283496 POS_UTC_REF 0;
BA_ "GenSigActiveRepetitions" SG_ 2600468496 NM_Gateway_CAB 3;
BA_ "GenSigSendType" SG_ 2600468496 NM_Gateway_CAB 4;
BA_ "GenSigFuncType" SG_ 2600468496 NM_Gateway_CAB 16;
BA_ "GenSigSwitchedByIgnition" SG_ 2600468496 NM_Gateway_CAB 0;
BA_ "GenSigSendType" SG_ 2600468496 NM_Gateway_Car_Wakeup 3;
BA_ "GenSigSwitchedByIgnition" SG_ 2600468496 NM_Gateway_Car_Wakeup 0;
BA_ "GenSigSwitchedByIgnition" SG_ 2600468496 NM_Gateway_CBV_AWB 0;
BA_ "GenSigSwitchedByIgnition" SG_ 2600468496 NM_Gateway_CBV_CRI 0;
BA_ "GenSigSwitchedByIgnition" SG_ 2600468496 NM_Gateway_NM_aktiv_Buskopplung 0;
BA_ "GenSigSwitchedByIgnition" SG_ 2600468496 NM_Gateway_NM_aktiv_Connect 0;
BA_ "GenSigSwitchedByIgnition" SG_ 2600468496 NM_Gateway_NM_aktiv_CWU 0;
BA_ "GenSigSwitchedByIgnition" SG_ 2600468496 NM_Gateway_NM_aktiv_Diagnose 0;
BA_ "GenSigSwitchedByIgnition" SG_ 2600468496 NM_Gateway_NM_aktiv_EM 0;
BA_ "GenSigSwitchedByIgnition" SG_ 2600468496 NM_Gateway_NM_aktiv_FC 0;
BA_ "GenSigSwitchedByIgnition" SG_ 2600468496 NM_Gateway_NM_aktiv_Fremdladung 0;
BA_ "GenSigSwitchedByIgnition" SG_ 2600468496 NM_Gateway_NM_aktiv_KL15 0;
BA_ "GenSigSwitchedByIgnition" SG_ 2600468496 NM_Gateway_NM_aktiv_LIN2 0;
BA_ "GenSigSwitchedByIgnition" SG_ 2600468496 NM_Gateway_NM_aktiv_OBDC 0;
BA_ "GenSigSwitchedByIgnition" SG_ 2600468496 NM_Gateway_NM_aktiv_Tmin 0;
BA_ "GenSigSwitchedByIgnition" SG_ 2600468496 NM_Gateway_NM_State 0;
BA_ "GenSigStartValue" SG_ 2600468496 NM_Gateway_SNI 16;
BA_ "GenSigSwitchedByIgnition" SG_ 2600468496 NM_Gateway_SNI 0;
BA_ "GenSigSwitchedByIgnition" SG_ 2600468496 NM_Gateway_UDS_CC 0;
BA_ "GenSigActiveRepetitions" SG_ 2600468489 NM_Sekundaer_09_CAB 3;
BA_ "GenSigSendType" SG_ 2600468489 NM_Sekundaer_09_CAB 4;
BA_ "GenSigFuncType" SG_ 2600468489 NM_Sekundaer_09_CAB 16;
BA_ "GenSigSwitchedByIgnition" SG_ 2600468489 NM_Sekundaer_09_CAB 0;
BA_ "GenSigSendType" SG_ 2600468489 NM_Sekundaer_09_Car_Wakeup 3;
BA_ "GenSigSwitchedByIgnition" SG_ 2600468489 NM_Sekundaer_09_Car_Wakeup 0;
BA_ "GenSigSwitchedByIgnition" SG_ 2600468489 NM_Sekundaer_09_CBV_AWB 0;
BA_ "GenSigSwitchedByIgnition" SG_ 2600468489 NM_Sekundaer_09_CBV_CRI 0;
BA_ "GenSigSwitchedByIgnition" SG_ 2600468489 NM_Sekundaer_09_NM_aktiv_Backend 0;
BA_ "GenSigSwitchedByIgnition" SG_ 2600468489 NM_Sekundaer_09_NM_aktiv_BaseFct 0;
BA_ "GenSigSwitchedByIgnition" SG_ 2600468489 NM_Sekundaer_09_NM_aktiv_Diag 0;
BA_ "GenSigSwitchedByIgnition" SG_ 2600468489 NM_Sekundaer_09_NM_aktiv_KL15 0;
BA_ "GenSigSwitchedByIgnition" SG_ 2600468489 NM_Sekundaer_09_NM_aktiv_MOD 0;
BA_ "GenSigSwitchedByIgnition" SG_ 2600468489 NM_Sekundaer_09_NM_aktiv_RmtDiag 0;
BA_ "GenSigSwitchedByIgnition" SG_ 2600468489 NM_Sekundaer_09_NM_aktiv_RmtFcts 0;
BA_ "GenSigSwitchedByIgnition" SG_ 2600468489 NM_Sekundaer_09_NM_aktiv_RmtUpdt 0;
BA_ "GenSigSwitchedByIgnition" SG_ 2600468489 NM_Sekundaer_09_NM_aktiv_Tmin 0;
BA_ "GenSigSwitchedByIgnition" SG_ 2600468489 NM_Sekundaer_09_NM_State 0;
BA_ "GenSigStartValue" SG_ 2600468489 NM_Sekundaer_09_SNI 9;
BA_ "GenSigSwitchedByIgnition" SG_ 2600468489 NM_Sekundaer_09_SNI 0;
BA_ "GenSigSwitchedByIgnition" SG_ 2600468489 NM_Sekundaer_09_UDS_CC 0;
BA_ "GenSigActiveRepetitions" SG_ 2600468720 NM_Sekundaer_F0_CAB 3;
BA_ "GenSigSendType" SG_ 2600468720 NM_Sekundaer_F0_CAB 4;
BA_ "GenSigSwitchedByIgnition" SG_ 2600468720 NM_Sekundaer_F0_CAB 0;
BA_ "GenSigSendType" SG_ 2600468720 NM_Sekundaer_F0_Car_Wakeup 3;
BA_ "GenSigSwitchedByIgnition" SG_ 2600468720 NM_Sekundaer_F0_Car_Wakeup 0;
BA_ "GenSigSwitchedByIgnition" SG_ 2600468720 NM_Sekundaer_F0_CBV_AWB 0;
BA_ "GenSigSwitchedByIgnition" SG_ 2600468720 NM_Sekundaer_F0_CBV_CRI 0;
BA_ "GenSigSwitchedByIgnition" SG_ 2600468720 NM_Sekundaer_F0_NM_aktiv_BTKey 0;
BA_ "GenSigSwitchedByIgnition" SG_ 2600468720 NM_Sekundaer_F0_NM_aktiv_Diag 0;
BA_ "GenSigSwitchedByIgnition" SG_ 2600468720 NM_Sekundaer_F0_NM_aktiv_eCall 0;
BA_ "GenSigSwitchedByIgnition" SG_ 2600468720 NM_Sekundaer_F0_NM_aktiv_Eth_Kom 0;
BA_ "GenSigSwitchedByIgnition" SG_ 2600468720 NM_Sekundaer_F0_NM_aktiv_KL15 0;
BA_ "GenSigSwitchedByIgnition" SG_ 2600468720 NM_Sekundaer_F0_NM_aktiv_Timer 0;
BA_ "GenSigSwitchedByIgnition" SG_ 2600468720 NM_Sekundaer_F0_NM_aktiv_Tmin 0;
BA_ "GenSigSwitchedByIgnition" SG_ 2600468720 NM_Sekundaer_F0_NM_aktiv_VTS 0;
BA_ "GenSigSwitchedByIgnition" SG_ 2600468720 NM_Sekundaer_F0_NM_State 0;
BA_ "GenSigStartValue" SG_ 2600468720 NM_Sekundaer_F0_SNI 240;
BA_ "GenSigSwitchedByIgnition" SG_ 2600468720 NM_Sekundaer_F0_SNI 0;
BA_ "GenSigSwitchedByIgnition" SG_ 2600468720 NM_Sekundaer_F0_UDS_CC 0;
BA_ "GenSigSendType" SG_ 1635 BEM_02_Abschaltstufen 0;
BA_ "GenSigSwitchedByIgnition" SG_ 1635 BEM_02_Abschaltstufen 0;
BA_ "GenSigSendType" SG_ 1635 BEM_Anf_KL15_schalten 0;
BA_ "GenSigSwitchedByIgnition" SG_ 1635 BEM_Anf_KL15_schalten 0;
BA_ "GenSigSendType" SG_ 1635 BEM_Batteriediagnose 0;
BA_ "GenSigSwitchedByIgnition" SG_ 1635 BEM_Batteriediagnose 0;
BA_ "Fehlerwert" SG_ 1635 BEM_Batteriediagnose 7;
BA_ "GenSigSendType" SG_ 1635 BEM_Generatordiagnose 0;
BA_ "GenSigSwitchedByIgnition" SG_ 1635 BEM_Generatordiagnose 0;
BA_ "GenSigSendType" SG_ 1635 BEM_HL_Regelung_Status 0;
BA_ "GenSigSwitchedByIgnition" SG_ 1635 BEM_HL_Regelung_Status 0;
BA_ "GenSigSendType" SG_ 1635 BEM_Ladezustand 0;
BA_ "GenSigStartValue" SG_ 1635 BEM_Ladezustand 14;
BA_ "GenSigSwitchedByIgnition" SG_ 1635 BEM_Ladezustand 0;
BA_ "Fehlerwert" SG_ 1635 BEM_Ladezustand 15;
BA_ "GenSigSendType" SG_ 1635 BEM_MMI_Vorwarnung 0;
BA_ "GenSigSwitchedByIgnition" SG_ 1635 BEM_MMI_Vorwarnung 0;
BA_ "GenSigSendType" SG_ 1635 BEM_Red_Innengeblaese 0;
BA_ "GenSigSwitchedByIgnition" SG_ 1635 BEM_Red_Innengeblaese 0;
BA_ "GenSigSendType" SG_ 1635 BEM_REK_aktiv 0;
BA_ "GenSigSwitchedByIgnition" SG_ 1635 BEM_REK_aktiv 0;
BA_ "GenSigSendType" SG_ 1635 BEM_STH_Einschaltverbot 0;
BA_ "GenSigSwitchedByIgnition" SG_ 1635 BEM_STH_Einschaltverbot 0;
BA_ "GenSigSendType" SG_ 1635 BEM_STH_Zielzeit 0;
BA_ "GenSigStartValue" SG_ 1635 BEM_STH_Zielzeit 14;
BA_ "GenSigSwitchedByIgnition" SG_ 1635 BEM_STH_Zielzeit 0;
BA_ "Fehlerwert" SG_ 1635 BEM_STH_Zielzeit 15;
BA_ "GenSigSendType" SG_ 1635 BEM_UBDM 0;
BA_ "GenSigSwitchedByIgnition" SG_ 1635 BEM_UBDM 0;
BA_ "Fehlerwert" SG_ 1635 BEM_UBDM 255;
BA_ "GenSigSendType" SG_ 1635 BEM_UGenSoll 0;
BA_ "GenSigSwitchedByIgnition" SG_ 1635 BEM_UGenSoll 0;
BA_ "GenSigSendType" SG_ 1635 MIB_Stromsparmodus 0;
BA_ "GenSigSwitchedByIgnition" SG_ 1635 MIB_Stromsparmodus 0;
BA_ "GenSigSendType" SG_ 1635 NVEM_Anf_SD_schalten 0;
BA_ "GenSigSwitchedByIgnition" SG_ 1635 NVEM_Anf_SD_schalten 0;
BA_ "GenSigSendType" SG_ 1635 NVEM_Batterie_Service 0;
BA_ "GenSigSwitchedByIgnition" SG_ 1635 NVEM_Batterie_Service 0;
BA_ "GenSigSendType" SG_ 1635 NVEM_Freigabe_OnlineUpdate 0;
BA_ "GenSigSwitchedByIgnition" SG_ 1635 NVEM_Freigabe_OnlineUpdate 0;
BA_ "GenSigSendType" SG_ 1635 NVEM_Freigabe_ORU4 0;
BA_ "GenSigSwitchedByIgnition" SG_ 1635 NVEM_Freigabe_ORU4 0;
BA_ "GenSigSendType" SG_ 1635 NVEM_Last_Anf 0;
BA_ "GenSigSwitchedByIgnition" SG_ 1635 NVEM_Last_Anf 0;
BA_ "GenSigSendType" SG_ 2589283656 ORU_Status 3;
BA_ "GenSigSwitchedByIgnition" SG_ 2589283656 ORU_Status 0;
BA_ "GenSigSendType" SG_ 2589283656 ORU_Warnung 3;
BA_ "GenSigSwitchedByIgnition" SG_ 2589283656 ORU_Warnung 0;
BA_ "GenSigActiveRepetitions" SG_ 2527679670 ORU_EM_Anfrage_Flashdauer 5;
BA_ "GenSigSendType" SG_ 2527679670 ORU_EM_Anfrage_Flashdauer 4;
BA_ "GenSigSwitchedByIgnition" SG_ 2527679670 ORU_EM_Anfrage_Flashdauer 0;
BA_ "GenSigActiveRepetitions" SG_ 2527679670 ORU_EM_Anfrage_freigegebeneNetze 5;
BA_ "GenSigSendType" SG_ 2527679670 ORU_EM_Anfrage_freigegebeneNetze 4;
BA_ "GenSigSwitchedByIgnition" SG_ 2527679670 ORU_EM_Anfrage_freigegebeneNetze 0;
BA_ "GenSigActiveRepetitions" SG_ 2527679670 ORU_EM_Anfrage_Stromaufnahme 5;
BA_ "GenSigSendType" SG_ 2527679670 ORU_EM_Anfrage_Stromaufnahme 4;
BA_ "GenSigSwitchedByIgnition" SG_ 2527679670 ORU_EM_Anfrage_Stromaufnahme 0;
BA_ "GenSigActiveRepetitions" SG_ 2527679670 ORU_Status_Anf 5;
BA_ "GenSigSendType" SG_ 2527679670 ORU_Status_Anf 4;
BA_ "GenSigSwitchedByIgnition" SG_ 2527679670 ORU_Status_Anf 0;
BA_ "GenSigSendType" SG_ 2527679670 OTA_FC_FahrwerkAnf 0;
BA_ "GenSigSwitchedByIgnition" SG_ 2527679670 OTA_FC_FahrwerkAnf 0;
BA_ "GenSigSendType" SG_ 2527679670 OTA_FC_FoD_Stornierung 3;
BA_ "GenSigActiveRepetitions" SG_ 2527679670 OTA_FC_Hinweis_Update 5;
BA_ "GenSigSendType" SG_ 2527679670 OTA_FC_Hinweis_Update 4;
BA_ "GenSigSwitchedByIgnition" SG_ 2527679670 OTA_FC_Hinweis_Update 0;
BA_ "GenSigActiveRepetitions" SG_ 2527679670 OTA_FC_IOF_Ausfall 5;
BA_ "GenSigSendType" SG_ 2527679670 OTA_FC_IOF_Ausfall 4;
BA_ "GenSigSwitchedByIgnition" SG_ 2527679670 OTA_FC_IOF_Ausfall 0;
BA_ "GenSigSendType" SG_ 2527679670 OTA_FC_LiftAnf 0;
BA_ "GenSigSwitchedByIgnition" SG_ 2527679670 OTA_FC_LiftAnf 0;
BA_ "GenSigSendType" SG_ 2527679670 OTA_FC_NiveauAnf 0;
BA_ "GenSigSwitchedByIgnition" SG_ 2527679670 OTA_FC_NiveauAnf 0;
BA_ "GenSigActiveRepetitions" SG_ 2527679670 OTA_FC_PredMaint_Ausfall 5;
BA_ "GenSigSendType" SG_ 2527679670 OTA_FC_PredMaint_Ausfall 4;
BA_ "GenSigSwitchedByIgnition" SG_ 2527679670 OTA_FC_PredMaint_Ausfall 0;
BA_ "GenSigActiveRepetitions" SG_ 2527679670 OTA_FC_Warnung_Update 5;
BA_ "GenSigSendType" SG_ 2527679670 OTA_FC_Warnung_Update 4;
BA_ "GenSigSwitchedByIgnition" SG_ 2527679670 OTA_FC_Warnung_Update 0;
BA_ "GenSigSendType" SG_ 2463978757 PSO_last_rec_UserID_Src2 3;
BA_ "GenSigSwitchedByIgnition" SG_ 2463978757 PSO_last_rec_UserID_Src2 0;
BA_ "GenSigSendType" SG_ 1122 PSD_Abzweigerichtung 0;
BA_ "GenSigSwitchedByIgnition" SG_ 1122 PSD_Abzweigerichtung 0;
BA_ "GenSigSendType" SG_ 1122 PSD_Abzweigewinkel 0;
BA_ "GenSigSwitchedByIgnition" SG_ 1122 PSD_Abzweigewinkel 0;
BA_ "GenSigSendType" SG_ 1122 PSD_ADAS_Qualitaet 0;
BA_ "GenSigSendType" SG_ 1122 PSD_Anfangskruemmung 0;
BA_ "GenSigSwitchedByIgnition" SG_ 1122 PSD_Anfangskruemmung 0;
BA_ "GenSigSendType" SG_ 1122 PSD_Anfangskruemmung_Vorz 0;
BA_ "GenSigSwitchedByIgnition" SG_ 1122 PSD_Anfangskruemmung_Vorz 0;
BA_ "GenSigSendType" SG_ 1122 PSD_Bebauung 0;
BA_ "GenSigSendType" SG_ 1122 PSD_Endkruemmung 0;
BA_ "GenSigSendType" SG_ 1122 PSD_Endkruemmung_Vorz 0;
BA_ "GenSigSendType" SG_ 1122 PSD_Fahrspuren_Anzahl 0;
BA_ "GenSigStartValue" SG_ 1122 PSD_Fahrspuren_Anzahl 1;
BA_ "GenSigSwitchedByIgnition" SG_ 1122 PSD_Fahrspuren_Anzahl 0;
BA_ "GenSigSendType" SG_ 1122 PSD_Geradester_Pfad 0;
BA_ "GenSigSendType" SG_ 1122 PSD_Idenditaets_ID 0;
BA_ "Fehlerwert" SG_ 1122 PSD_Idenditaets_ID 1;
BA_ "GenSigSendType" SG_ 1122 PSD_Rampe 0;
BA_ "GenSigSendType" SG_ 1122 PSD_Segment_ID 0;
BA_ "GenSigSendType" SG_ 1122 PSD_Segment_Komplett 0;
BA_ "GenSigSwitchedByIgnition" SG_ 1122 PSD_Segment_Komplett 0;
BA_ "GenSigSendType" SG_ 1122 PSD_Segmentlaenge 0;
BA_ "GenSigSendType" SG_ 1122 PSD_Strassenkategorie 0;
BA_ "GenSigStartValue" SG_ 1122 PSD_Strassenkategorie 7;
BA_ "GenSigSwitchedByIgnition" SG_ 1122 PSD_Strassenkategorie 0;
BA_ "GenSigSendType" SG_ 1122 PSD_Vorgaenger_Segment_ID 0;
BA_ "GenSigSendType" SG_ 1122 PSD_wahrscheinlichster_Pfad 0;
BA_ "GenSigSendType" SG_ 1527 RW_Gesamt_Reichweite_Anzeige 0;
BA_ "GenSigStartValue" SG_ 1527 RW_Gesamt_Reichweite_Anzeige 2046;
BA_ "GenSigSwitchedByIgnition" SG_ 1527 RW_Gesamt_Reichweite_Anzeige 0;
BA_ "Fehlerwert" SG_ 1527 RW_Gesamt_Reichweite_Anzeige 2047;
BA_ "GenSigSendType" SG_ 1527 RW_Primaer_Reichweite_Anzeige 0;
BA_ "GenSigStartValue" SG_ 1527 RW_Primaer_Reichweite_Anzeige 2046;
BA_ "GenSigSwitchedByIgnition" SG_ 1527 RW_Primaer_Reichweite_Anzeige 0;
BA_ "Fehlerwert" SG_ 1527 RW_Primaer_Reichweite_Anzeige 2047;
BA_ "GenSigSendType" SG_ 1527 RW_Reichweite_Einheit_Anzeige 0;
BA_ "GenSigSwitchedByIgnition" SG_ 1527 RW_Reichweite_Einheit_Anzeige 0;
BA_ "GenSigSendType" SG_ 1527 RW_Reservewarnung_aktiv 0;
BA_ "GenSigSwitchedByIgnition" SG_ 1527 RW_Reservewarnung_aktiv 0;
BA_ "GenSigSendType" SG_ 1527 RW_Sek_Reichweitenv_Einheit 0;
BA_ "GenSigStartValue" SG_ 1527 RW_Sek_Reichweitenv_Einheit 3;
BA_ "GenSigSwitchedByIgnition" SG_ 1527 RW_Sek_Reichweitenv_Einheit 0;
BA_ "GenSigSendType" SG_ 1527 RW_Sek_Reichweitenverbrauch 0;
BA_ "GenSigStartValue" SG_ 1527 RW_Sek_Reichweitenverbrauch 2047;
BA_ "GenSigSwitchedByIgnition" SG_ 1527 RW_Sek_Reichweitenverbrauch 0;
BA_ "GenSigSendType" SG_ 1527 RW_Sekundaer_Reichweite 0;
BA_ "GenSigStartValue" SG_ 1527 RW_Sekundaer_Reichweite 2046;
BA_ "GenSigSwitchedByIgnition" SG_ 1527 RW_Sekundaer_Reichweite 0;
BA_ "Fehlerwert" SG_ 1527 RW_Sekundaer_Reichweite 2047;
BA_ "GenSigSendType" SG_ 1527 RW_Sekundaer_Reichweite_Anzeige 0;
BA_ "GenSigStartValue" SG_ 1527 RW_Sekundaer_Reichweite_Anzeige 2046;
BA_ "GenSigSwitchedByIgnition" SG_ 1527 RW_Sekundaer_Reichweite_Anzeige 0;
BA_ "Fehlerwert" SG_ 1527 RW_Sekundaer_Reichweite_Anzeige 2047;
BA_ "GenSigSendType" SG_ 1527 RW_Tendenz 0;
BA_ "GenSigSwitchedByIgnition" SG_ 1527 RW_Tendenz 0;
BA_ "GenSigSendType" SG_ 1527 RW_Texte 3;
BA_ "GenSigSwitchedByIgnition" SG_ 1527 RW_Texte 0;
BA_ "GenSigSendType" SG_ 124 SARA_Accel_Z_b_CAN 0;
BA_ "GenSigStartValue" SG_ 124 SARA_Accel_Z_b_CAN 32768;
BA_ "GenSigSwitchedByIgnition" SG_ 124 SARA_Accel_Z_b_CAN 0;
BA_ "Fehlerwert" SG_ 124 SARA_Accel_Z_b_CAN 65535;
BA_ "GenSigSendType" SG_ 124 SARA_CF_Accel_Z_b_CAN 0;
BA_ "GenSigStartValue" SG_ 124 SARA_CF_Accel_Z_b_CAN 4;
BA_ "GenSigSwitchedByIgnition" SG_ 124 SARA_CF_Accel_Z_b_CAN 0;
BA_ "GenSigSendType" SG_ 124 SARA_CF_Omega_X_b_CAN 0;
BA_ "GenSigStartValue" SG_ 124 SARA_CF_Omega_X_b_CAN 4;
BA_ "GenSigSwitchedByIgnition" SG_ 124 SARA_CF_Omega_X_b_CAN 0;
BA_ "GenSigSendType" SG_ 124 SARA_CF_Omega_Y_b_CAN 0;
BA_ "GenSigStartValue" SG_ 124 SARA_CF_Omega_Y_b_CAN 4;
BA_ "GenSigSwitchedByIgnition" SG_ 124 SARA_CF_Omega_Y_b_CAN 0;
BA_ "GenSigSendType" SG_ 124 SARA_Omega_X_b_CAN 0;
BA_ "GenSigStartValue" SG_ 124 SARA_Omega_X_b_CAN 32768;
BA_ "GenSigSwitchedByIgnition" SG_ 124 SARA_Omega_X_b_CAN 0;
BA_ "Fehlerwert" SG_ 124 SARA_Omega_X_b_CAN 65535;
BA_ "GenSigSendType" SG_ 124 SARA_Omega_Y_b_CAN 0;
BA_ "GenSigStartValue" SG_ 124 SARA_Omega_Y_b_CAN 32768;
BA_ "GenSigSwitchedByIgnition" SG_ 124 SARA_Omega_Y_b_CAN 0;
BA_ "Fehlerwert" SG_ 124 SARA_Omega_Y_b_CAN 65535;
BA_ "GenSigSendType" SG_ 378 SARA_Accel_X_010_02 0;
BA_ "GenSigStartValue" SG_ 378 SARA_Accel_X_010_02 32768;
BA_ "GenSigSwitchedByIgnition" SG_ 378 SARA_Accel_X_010_02 0;
BA_ "Fehlerwert" SG_ 378 SARA_Accel_X_010_02 65535;
BA_ "GenSigSendType" SG_ 378 SARA_Accel_Y_010_02 0;
BA_ "GenSigStartValue" SG_ 378 SARA_Accel_Y_010_02 32768;
BA_ "GenSigSwitchedByIgnition" SG_ 378 SARA_Accel_Y_010_02 0;
BA_ "Fehlerwert" SG_ 378 SARA_Accel_Y_010_02 65535;
BA_ "GenSigSendType" SG_ 378 SARA_CF_Accel_X_010_02 0;
BA_ "GenSigStartValue" SG_ 378 SARA_CF_Accel_X_010_02 4;
BA_ "GenSigSwitchedByIgnition" SG_ 378 SARA_CF_Accel_X_010_02 0;
BA_ "GenSigSendType" SG_ 378 SARA_CF_Accel_Y_010_02 0;
BA_ "GenSigStartValue" SG_ 378 SARA_CF_Accel_Y_010_02 4;
BA_ "GenSigSwitchedByIgnition" SG_ 378 SARA_CF_Accel_Y_010_02 0;
BA_ "GenSigSendType" SG_ 378 SARA_CF_Omega_Z_010_02 0;
BA_ "GenSigStartValue" SG_ 378 SARA_CF_Omega_Z_010_02 4;
BA_ "GenSigSwitchedByIgnition" SG_ 378 SARA_CF_Omega_Z_010_02 0;
BA_ "GenSigSendType" SG_ 378 SARA_Omega_Z_010_02 0;
BA_ "GenSigStartValue" SG_ 378 SARA_Omega_Z_010_02 32768;
BA_ "GenSigSwitchedByIgnition" SG_ 378 SARA_Omega_Z_010_02 0;
BA_ "Fehlerwert" SG_ 378 SARA_Omega_Z_010_02 65535;
BA_ "GenSigSendType" SG_ 424 SARA_11_BZ 0;
BA_ "GenSigFuncType" SG_ 424 SARA_11_BZ 1;
BA_ "GenSigSwitchedByIgnition" SG_ 424 SARA_11_BZ 0;
BA_ "GenSigSendType" SG_ 424 SARA_11_CRC 0;
BA_ "GenSigFuncType" SG_ 424 SARA_11_CRC 2;
BA_ "GenSigSwitchedByIgnition" SG_ 424 SARA_11_CRC 0;
BA_ "GenSigSendType" SG_ 424 SARA_Accel_X_r 0;
BA_ "GenSigStartValue" SG_ 424 SARA_Accel_X_r 4096;
BA_ "GenSigSwitchedByIgnition" SG_ 424 SARA_Accel_X_r 0;
BA_ "Fehlerwert" SG_ 424 SARA_Accel_X_r 8191;
BA_ "GenSigSendType" SG_ 424 SARA_Accel_Y_r 0;
BA_ "GenSigStartValue" SG_ 424 SARA_Accel_Y_r 4096;
BA_ "GenSigSwitchedByIgnition" SG_ 424 SARA_Accel_Y_r 0;
BA_ "Fehlerwert" SG_ 424 SARA_Accel_Y_r 8191;
BA_ "GenSigSendType" SG_ 424 SARA_CF_Accel_X_r 0;
BA_ "GenSigStartValue" SG_ 424 SARA_CF_Accel_X_r 4;
BA_ "GenSigSwitchedByIgnition" SG_ 424 SARA_CF_Accel_X_r 0;
BA_ "GenSigSendType" SG_ 424 SARA_CF_Accel_Y_r 0;
BA_ "GenSigStartValue" SG_ 424 SARA_CF_Accel_Y_r 4;
BA_ "GenSigSwitchedByIgnition" SG_ 424 SARA_CF_Accel_Y_r 0;
BA_ "GenSigSendType" SG_ 424 SARA_CF_Omega_Z_r 0;
BA_ "GenSigStartValue" SG_ 424 SARA_CF_Omega_Z_r 4;
BA_ "GenSigSwitchedByIgnition" SG_ 424 SARA_CF_Omega_Z_r 0;
BA_ "GenSigSendType" SG_ 424 SARA_Omega_Z_r 0;
BA_ "GenSigStartValue" SG_ 424 SARA_Omega_Z_r 4096;
BA_ "GenSigSwitchedByIgnition" SG_ 424 SARA_Omega_Z_r 0;
BA_ "Fehlerwert" SG_ 424 SARA_Omega_Z_r 8191;
BA_ "GenSigSendType" SG_ 133 SCU_01_BZ 0;
BA_ "GenSigFuncType" SG_ 133 SCU_01_BZ 1;
BA_ "GenSigSendType" SG_ 133 SCU_01_CRC 0;
BA_ "GenSigFuncType" SG_ 133 SCU_01_CRC 2;
BA_ "GenSigSendType" SG_ 133 SCU_IL_Leistungsreserve 0;
BA_ "GenSigStartValue" SG_ 133 SCU_IL_Leistungsreserve 254;
BA_ "Fehlerwert" SG_ 133 SCU_IL_Leistungsreserve 255;
BA_ "GenSigSendType" SG_ 133 SCU_Ist_Ue_Winkel 0;
BA_ "GenSigStartValue" SG_ 133 SCU_Ist_Ue_Winkel 4094;
BA_ "Fehlerwert" SG_ 133 SCU_Ist_Ue_Winkel 4095;
BA_ "GenSigSendType" SG_ 133 SCU_max_Gradient 0;
BA_ "Fehlerwert" SG_ 133 SCU_max_Gradient 511;
BA_ "GenSigSendType" SG_ 133 SCU_Sensorstatus 0;
BA_ "GenSigSendType" SG_ 133 SCU_Soll_Ue_Winkel 0;
BA_ "GenSigStartValue" SG_ 133 SCU_Soll_Ue_Winkel 2046;
BA_ "Fehlerwert" SG_ 133 SCU_Soll_Ue_Winkel 2047;
BA_ "GenSigSendType" SG_ 133 SCU_Status 0;
BA_ "GenSigStartValue" SG_ 133 SCU_Status 1;
BA_ "GenSigSendType" SG_ 133 SCU_VZ_Ist_Ue_Winkel 0;
BA_ "GenSigSendType" SG_ 133 SCU_VZ_Soll_Ue_Winkel 0;
BA_ "GenSigSendType" SG_ 133 SCU_Winkelbegrenzung 0;
BA_ "GenSigSendType" SG_ 2589283634 SM_LAPP_Aussenlicht_aktiv 3;
BA_ "GenSigSendType" SG_ 2589283634 SM_LAPP_Demo_ABBL_Anf 3;
BA_ "GenSigSendType" SG_ 2589283634 SM_LAPP_Demo_Autobahnmodus_Anf 3;
BA_ "GenSigSendType" SG_ 2589283634 SM_LAPP_Demo_Distanz_01 3;
BA_ "GenSigSendType" SG_ 2589283634 SM_LAPP_Demo_Distanz_02 3;
BA_ "GenSigSendType" SG_ 2589283634 SM_LAPP_Demo_DKL_Anf 3;
BA_ "GenSigSendType" SG_ 2589283634 SM_LAPP_Demo_Einschalteffekt_Anf 3;
BA_ "GenSigSendType" SG_ 2589283634 SM_LAPP_Demo_FL_Anf 3;
BA_ "GenSigSendType" SG_ 2589283634 SM_LAPP_Demo_MaLi_Anf 3;
BA_ "GenSigSendType" SG_ 2589283634 SM_LAPP_Demo_Objekt_01_Anf 3;
BA_ "GenSigSendType" SG_ 2589283634 SM_LAPP_Demo_Objekt_02_Anf 3;
BA_ "GenSigSendType" SG_ 2589283634 SM_LAPP_Demo_Schildentbl_01_Anf 3;
BA_ "GenSigSendType" SG_ 2589283634 SM_LAPP_Demo_Schildentbl_02_Anf 3;
BA_ "GenSigSendType" SG_ 2589283634 SM_LAPP_Demo_Winkel_Hor_01 3;
BA_ "GenSigStartValue" SG_ 2589283634 SM_LAPP_Demo_Winkel_Hor_01 512;
BA_ "GenSigSendType" SG_ 2589283634 SM_LAPP_Demo_Winkel_Hor_02 3;
BA_ "GenSigStartValue" SG_ 2589283634 SM_LAPP_Demo_Winkel_Hor_02 512;
BA_ "GenSigSendType" SG_ 2589283634 SM_LAPP_Demo_Winkel_Vert_01 3;
BA_ "GenSigStartValue" SG_ 2589283634 SM_LAPP_Demo_Winkel_Vert_01 128;
BA_ "GenSigSendType" SG_ 2589283634 SM_LAPP_Demo_Winkel_Vert_02 3;
BA_ "GenSigStartValue" SG_ 2589283634 SM_LAPP_Demo_Winkel_Vert_02 128;
BA_ "GenSigSendType" SG_ 2589283634 SM_LAPP_Verbindungsstatus 3;
BA_ "GenSigSendType" SG_ 2527679657 SM_LAPP_Demo_AbbiegeWa_Anf 3;
BA_ "GenSigSendType" SG_ 2527679657 SM_LAPP_Demo_AbsAss_Anf 3;
BA_ "GenSigSendType" SG_ 2527679657 SM_LAPP_Demo_AccAss_Anf 3;
BA_ "GenSigSendType" SG_ 2527679657 SM_LAPP_Demo_advCH_F01_Anf 3;
BA_ "GenSigSendType" SG_ 2527679657 SM_LAPP_Demo_advLH_F01_Anf 3;
BA_ "GenSigSendType" SG_ 2527679657 SM_LAPP_Demo_BauLi_Anf 3;
BA_ "GenSigSendType" SG_ 2527679657 SM_LAPP_Demo_BeAss_Anf 3;
BA_ "GenSigSendType" SG_ 2527679657 SM_LAPP_Demo_CH_F01_Anf 3;
BA_ "GenSigSendType" SG_ 2527679657 SM_LAPP_Demo_CH_H01_Anf 3;
BA_ "GenSigSendType" SG_ 2527679657 SM_LAPP_Demo_EffAss_Anf 3;
BA_ "GenSigSendType" SG_ 2527679657 SM_LAPP_Demo_LH_F01_Anf 3;
BA_ "GenSigSendType" SG_ 2527679657 SM_LAPP_Demo_LH_H01_Anf 3;
BA_ "GenSigSendType" SG_ 2527679657 SM_LAPP_Demo_PreSAss_Anf 3;
BA_ "GenSigSendType" SG_ 2527679657 SM_LAPP_Demo_RouLi_Anf 3;
BA_ "GenSigSendType" SG_ 2527679657 SM_LAPP_Demo_SitLi_Anf 3;
BA_ "GenSigSendType" SG_ 2527679657 SM_LAPP_Demo_SL_Anf 3;
BA_ "GenSigSendType" SG_ 2527679657 SM_LAPP_Demo_SL_Signatur_Anf 3;
BA_ "GenSigSendType" SG_ 2527679657 SM_LAPP_Demo_SpuLi_Anf 3;
BA_ "GenSigSendType" SG_ 2527679657 SM_LAPP_Demo_Stufe 3;
BA_ "GenSigSendType" SG_ 2527679657 SM_LAPP_Demo_TraLi_Anf 3;
BA_ "GenSigSendType" SG_ 2527679657 SM_LAPP_Demo_Variante 3;
BA_ "GenSigSendType" SG_ 2463978662 STS2_01_BZ 0;
BA_ "GenSigFuncType" SG_ 2463978662 STS2_01_BZ 1;
BA_ "GenSigSwitchedByIgnition" SG_ 2463978662 STS2_01_BZ 0;
BA_ "GenSigSendType" SG_ 2463978662 STS2_01_CRC 0;
BA_ "GenSigFuncType" SG_ 2463978662 STS2_01_CRC 2;
BA_ "GenSigSwitchedByIgnition" SG_ 2463978662 STS2_01_CRC 0;
BA_ "GenSigSendType" SG_ 2463978662 STS2_Alarm_Blinker 3;
BA_ "GenSigSwitchedByIgnition" SG_ 2463978662 STS2_Alarm_Blinker 0;
BA_ "GenSigSendType" SG_ 2463978662 STS2_Alarm_still 0;
BA_ "GenSigSwitchedByIgnition" SG_ 2463978662 STS2_Alarm_still 0;
BA_ "GenSigSendType" SG_ 2463978662 STS2_Anlassersperre 0;
BA_ "GenSigSwitchedByIgnition" SG_ 2463978662 STS2_Anlassersperre 0;
BA_ "GenSigSendType" SG_ 2463978662 STS2_Car_not_under_theft 0;
BA_ "GenSigSwitchedByIgnition" SG_ 2463978662 STS2_Car_not_under_theft 0;
BA_ "GenSigSendType" SG_ 2463978662 STS2_Car_under_theft 0;
BA_ "GenSigSwitchedByIgnition" SG_ 2463978662 STS2_Car_under_theft 0;
BA_ "GenSigSendType" SG_ 2463978662 STS2_Door_Lock 3;
BA_ "GenSigSwitchedByIgnition" SG_ 2463978662 STS2_Door_Lock 0;
BA_ "GenSigSendType" SG_ 2463978662 STS2_Fahrlicht 3;
BA_ "GenSigSwitchedByIgnition" SG_ 2463978662 STS2_Fahrlicht 0;
BA_ "GenSigSendType" SG_ 2463978662 STS2_Laderelais 3;
BA_ "GenSigSwitchedByIgnition" SG_ 2463978662 STS2_Laderelais 0;
BA_ "GenSigSendType" SG_ 2463978662 STS2_Leerlaufschaltung 0;
BA_ "GenSigSwitchedByIgnition" SG_ 2463978662 STS2_Leerlaufschaltung 0;
BA_ "GenSigSendType" SG_ 2463978662 STS2_Notstart 3;
BA_ "GenSigSwitchedByIgnition" SG_ 2463978662 STS2_Notstart 0;
BA_ "GenSigSendType" SG_ 2463978662 STS2_Privatsphaere 0;
BA_ "GenSigSwitchedByIgnition" SG_ 2463978662 STS2_Privatsphaere 0;
BA_ "GenSigSendType" SG_ 2463978662 STS2_Signalhorn 3;
BA_ "GenSigSwitchedByIgnition" SG_ 2463978662 STS2_Signalhorn 0;
BA_ "GenSigSendType" SG_ 2463978662 STS2_Spiegel_Anklappen 3;
BA_ "GenSigSwitchedByIgnition" SG_ 2463978662 STS2_Spiegel_Anklappen 0;
BA_ "GenSigSendType" SG_ 2463978662 STS2_Standlicht 3;
BA_ "GenSigSwitchedByIgnition" SG_ 2463978662 STS2_Standlicht 0;
BA_ "GenSigSendType" SG_ 2463978662 STS2_Summer 3;
BA_ "GenSigSwitchedByIgnition" SG_ 2463978662 STS2_Summer 0;
BA_ "GenSigSendType" SG_ 2463978662 STS2_Texte 0;
BA_ "GenSigStartValue" SG_ 2463978662 STS2_Texte 14;
BA_ "GenSigSwitchedByIgnition" SG_ 2463978662 STS2_Texte 0;
BA_ "Fehlerwert" SG_ 2463978662 STS2_Texte 15;
BA_ "GenSigSendType" SG_ 2463978662 STS2_Typencodierung 0;
BA_ "GenSigSwitchedByIgnition" SG_ 2463978662 STS2_Typencodierung 0;
BA_ "GenSigSendType" SG_ 1172 GW_STS2_Privatsphaere 0;
BA_ "GenSigSwitchedByIgnition" SG_ 1172 GW_STS2_Privatsphaere 0;
BA_ "GenSigSendType" SG_ 1172 STS_01_BZ 0;
BA_ "GenSigFuncType" SG_ 1172 STS_01_BZ 1;
BA_ "GenSigSwitchedByIgnition" SG_ 1172 STS_01_BZ 0;
BA_ "GenSigSendType" SG_ 1172 STS_01_CRC 0;
BA_ "GenSigFuncType" SG_ 1172 STS_01_CRC 2;
BA_ "GenSigSwitchedByIgnition" SG_ 1172 STS_01_CRC 0;
BA_ "GenSigSendType" SG_ 1172 STS_Alarm_Blinker 3;
BA_ "GenSigSwitchedByIgnition" SG_ 1172 STS_Alarm_Blinker 0;
BA_ "GenSigSendType" SG_ 1172 STS_Alarm_still 0;
BA_ "GenSigSwitchedByIgnition" SG_ 1172 STS_Alarm_still 0;
BA_ "GenSigSendType" SG_ 1172 STS_Anlassersperre 0;
BA_ "GenSigSwitchedByIgnition" SG_ 1172 STS_Anlassersperre 0;
BA_ "GenSigSendType" SG_ 1172 STS_Car_not_under_theft 0;
BA_ "GenSigStartValue" SG_ 1172 STS_Car_not_under_theft 1;
BA_ "GenSigSwitchedByIgnition" SG_ 1172 STS_Car_not_under_theft 0;
BA_ "GenSigSendType" SG_ 1172 STS_Car_under_theft 0;
BA_ "GenSigSwitchedByIgnition" SG_ 1172 STS_Car_under_theft 0;
BA_ "GenSigSendType" SG_ 1172 STS_Door_Lock 3;
BA_ "GenSigSwitchedByIgnition" SG_ 1172 STS_Door_Lock 0;
BA_ "GenSigSendType" SG_ 1172 STS_Fahrlicht 3;
BA_ "GenSigSwitchedByIgnition" SG_ 1172 STS_Fahrlicht 0;
BA_ "GenSigSendType" SG_ 1172 STS_Laderelais 3;
BA_ "GenSigSwitchedByIgnition" SG_ 1172 STS_Laderelais 0;
BA_ "GenSigSendType" SG_ 1172 STS_Leerlaufschaltung 0;
BA_ "GenSigSwitchedByIgnition" SG_ 1172 STS_Leerlaufschaltung 0;
BA_ "GenSigSendType" SG_ 1172 STS_LIN_aktiv 0;
BA_ "GenSigSwitchedByIgnition" SG_ 1172 STS_LIN_aktiv 0;
BA_ "GenSigSendType" SG_ 1172 STS_Notstart 3;
BA_ "GenSigSwitchedByIgnition" SG_ 1172 STS_Notstart 0;
BA_ "GenSigSendType" SG_ 1172 STS_Signalhorn 3;
BA_ "GenSigSwitchedByIgnition" SG_ 1172 STS_Signalhorn 0;
BA_ "GenSigSendType" SG_ 1172 STS_Spiegel_Anklappen 3;
BA_ "GenSigSwitchedByIgnition" SG_ 1172 STS_Spiegel_Anklappen 0;
BA_ "GenSigSendType" SG_ 1172 STS_Standlicht 3;
BA_ "GenSigSwitchedByIgnition" SG_ 1172 STS_Standlicht 0;
BA_ "GenSigSendType" SG_ 1172 STS_Summer 3;
BA_ "GenSigSwitchedByIgnition" SG_ 1172 STS_Summer 0;
BA_ "GenSigSendType" SG_ 1172 STS_Texte 0;
BA_ "GenSigStartValue" SG_ 1172 STS_Texte 14;
BA_ "GenSigSwitchedByIgnition" SG_ 1172 STS_Texte 0;
BA_ "Fehlerwert" SG_ 1172 STS_Texte 15;
BA_ "GenSigSendType" SG_ 1172 STS_Typencodierung 0;
BA_ "GenSigSwitchedByIgnition" SG_ 1172 STS_Typencodierung 0;
BA_ "GenSigSendType" SG_ 1413 GW_KD_Fehler 3;
BA_ "GenSigSendType" SG_ 1413 SI_BUS_01 3;
BA_ "GenSigStartValue" SG_ 1413 SI_BUS_01 1;
BA_ "GenSigSwitchedByIgnition" SG_ 1413 SI_BUS_01 0;
BA_ "GenSigSendType" SG_ 1413 SI_BUS_02 3;
BA_ "GenSigStartValue" SG_ 1413 SI_BUS_02 1;
BA_ "GenSigSwitchedByIgnition" SG_ 1413 SI_BUS_02 0;
BA_ "GenSigSendType" SG_ 1413 SI_BUS_03 3;
BA_ "GenSigStartValue" SG_ 1413 SI_BUS_03 1;
BA_ "GenSigSwitchedByIgnition" SG_ 1413 SI_BUS_03 0;
BA_ "GenSigSendType" SG_ 1413 SI_BUS_04 3;
BA_ "GenSigStartValue" SG_ 1413 SI_BUS_04 1;
BA_ "GenSigSwitchedByIgnition" SG_ 1413 SI_BUS_04 0;
BA_ "GenSigSendType" SG_ 1413 SI_BUS_05 3;
BA_ "GenSigStartValue" SG_ 1413 SI_BUS_05 1;
BA_ "GenSigSwitchedByIgnition" SG_ 1413 SI_BUS_05 0;
BA_ "GenSigSendType" SG_ 1413 SI_BUS_06 3;
BA_ "GenSigStartValue" SG_ 1413 SI_BUS_06 1;
BA_ "GenSigSwitchedByIgnition" SG_ 1413 SI_BUS_06 0;
BA_ "GenSigSendType" SG_ 1413 SI_BUS_07 3;
BA_ "GenSigStartValue" SG_ 1413 SI_BUS_07 1;
BA_ "GenSigSwitchedByIgnition" SG_ 1413 SI_BUS_07 0;
BA_ "GenSigSendType" SG_ 1413 SI_BUS_08 3;
BA_ "GenSigStartValue" SG_ 1413 SI_BUS_08 1;
BA_ "GenSigSwitchedByIgnition" SG_ 1413 SI_BUS_08 0;
BA_ "GenSigSendType" SG_ 1413 SI_BUS_09 3;
BA_ "GenSigStartValue" SG_ 1413 SI_BUS_09 1;
BA_ "GenSigSwitchedByIgnition" SG_ 1413 SI_BUS_09 0;
BA_ "GenSigSendType" SG_ 1413 SI_BUS_10 3;
BA_ "GenSigStartValue" SG_ 1413 SI_BUS_10 1;
BA_ "GenSigSwitchedByIgnition" SG_ 1413 SI_BUS_10 0;
BA_ "GenSigSendType" SG_ 1413 SI_BUS_11 3;
BA_ "GenSigStartValue" SG_ 1413 SI_BUS_11 1;
BA_ "GenSigSwitchedByIgnition" SG_ 1413 SI_BUS_11 0;
BA_ "GenSigSendType" SG_ 1413 SI_BUS_12 3;
BA_ "GenSigStartValue" SG_ 1413 SI_BUS_12 1;
BA_ "GenSigSwitchedByIgnition" SG_ 1413 SI_BUS_12 0;
BA_ "GenSigSendType" SG_ 1413 SI_BUS_13 3;
BA_ "GenSigStartValue" SG_ 1413 SI_BUS_13 1;
BA_ "GenSigSwitchedByIgnition" SG_ 1413 SI_BUS_13 0;
BA_ "GenSigSendType" SG_ 1413 SI_BUS_14 3;
BA_ "GenSigStartValue" SG_ 1413 SI_BUS_14 1;
BA_ "GenSigSwitchedByIgnition" SG_ 1413 SI_BUS_14 0;
BA_ "GenSigSendType" SG_ 1413 SI_BUS_15 3;
BA_ "GenSigStartValue" SG_ 1413 SI_BUS_15 1;
BA_ "GenSigSwitchedByIgnition" SG_ 1413 SI_BUS_15 0;
BA_ "GenSigSendType" SG_ 1413 SI_Bus_Identifikation 0;
BA_ "GenSigSwitchedByIgnition" SG_ 1413 SI_Bus_Identifikation 0;
BA_ "GenSigSendType" SG_ 1413 SI_CAB 3;
BA_ "GenSigFuncType" SG_ 1413 SI_CAB 16;
BA_ "GenSigSwitchedByIgnition" SG_ 1413 SI_CAB 0;
BA_ "GenSigSendType" SG_ 1413 SI_Diagnose_Aktiv 3;
BA_ "GenSigSwitchedByIgnition" SG_ 1413 SI_Diagnose_Aktiv 0;
BA_ "GenSigSendType" SG_ 1413 SI_NWDF 3;
BA_ "GenSigSwitchedByIgnition" SG_ 1413 SI_NWDF 0;
BA_ "GenSigSendType" SG_ 1413 SI_NWDF_gueltig 3;
BA_ "GenSigFuncType" SG_ 1413 SI_NWDF_gueltig 8;
BA_ "GenSigSwitchedByIgnition" SG_ 1413 SI_NWDF_gueltig 0;
BA_ "GenSigSendType" SG_ 1413 SI_QRS_Mode 3;
BA_ "GenSigSwitchedByIgnition" SG_ 1413 SI_QRS_Mode 0;
BA_ "GenSigSendType" SG_ 1413 SI_Sammel_SG_Fehler 0;
BA_ "GenSigStartValue" SG_ 1413 SI_Sammel_SG_Fehler 63;
BA_ "GenSigSwitchedByIgnition" SG_ 1413 SI_Sammel_SG_Fehler 0;
BA_ "GenSigSendType" SG_ 1413 SI_Sammelfehler 3;
BA_ "GenSigSwitchedByIgnition" SG_ 1413 SI_Sammelfehler 0;
BA_ "GenSigSendType" SG_ 1413 SI_T_Mode 3;
BA_ "GenSigSwitchedByIgnition" SG_ 1413 SI_T_Mode 0;
BA_ "GenSigSendType" SG_ 1413 SI_T_Schutz 3;
BA_ "GenSigSwitchedByIgnition" SG_ 1413 SI_T_Schutz 0;
BA_ "GenSigSwitchedByIgnition" SG_ 1716 KS_Geheimnis_1 0;
BA_ "GenSigSwitchedByIgnition" SG_ 1716 KS_Geheimnis_2 0;
BA_ "GenSigSwitchedByIgnition" SG_ 1716 KS_Geheimnis_3 0;
BA_ "GenSigSwitchedByIgnition" SG_ 1716 KS_Geheimnis_4 0;
BA_ "GenSigSendType" SG_ 1716 VIN_01_MUX 0;
BA_ "GenSigSwitchedByIgnition" SG_ 1716 VIN_01_MUX 0;
BA_ "GenSigStartValue" SG_ 1716 VIN_1 45;
BA_ "GenSigSwitchedByIgnition" SG_ 1716 VIN_1 0;
BA_ "GenSigStartValue" SG_ 1716 VIN_10 45;
BA_ "GenSigSwitchedByIgnition" SG_ 1716 VIN_10 0;
BA_ "GenSigStartValue" SG_ 1716 VIN_11 45;
BA_ "GenSigSwitchedByIgnition" SG_ 1716 VIN_11 0;
BA_ "GenSigStartValue" SG_ 1716 VIN_12 45;
BA_ "GenSigSwitchedByIgnition" SG_ 1716 VIN_12 0;
BA_ "GenSigStartValue" SG_ 1716 VIN_13 45;
BA_ "GenSigSwitchedByIgnition" SG_ 1716 VIN_13 0;
BA_ "GenSigStartValue" SG_ 1716 VIN_14 45;
BA_ "GenSigSwitchedByIgnition" SG_ 1716 VIN_14 0;
BA_ "GenSigStartValue" SG_ 1716 VIN_15 45;
BA_ "GenSigSwitchedByIgnition" SG_ 1716 VIN_15 0;
BA_ "GenSigStartValue" SG_ 1716 VIN_16 45;
BA_ "GenSigSwitchedByIgnition" SG_ 1716 VIN_16 0;
BA_ "GenSigStartValue" SG_ 1716 VIN_17 45;
BA_ "GenSigSwitchedByIgnition" SG_ 1716 VIN_17 0;
BA_ "GenSigStartValue" SG_ 1716 VIN_2 45;
BA_ "GenSigSwitchedByIgnition" SG_ 1716 VIN_2 0;
BA_ "GenSigStartValue" SG_ 1716 VIN_3 45;
BA_ "GenSigSwitchedByIgnition" SG_ 1716 VIN_3 0;
BA_ "GenSigStartValue" SG_ 1716 VIN_4 45;
BA_ "GenSigSwitchedByIgnition" SG_ 1716 VIN_4 0;
BA_ "GenSigStartValue" SG_ 1716 VIN_5 45;
BA_ "GenSigSwitchedByIgnition" SG_ 1716 VIN_5 0;
BA_ "GenSigStartValue" SG_ 1716 VIN_6 45;
BA_ "GenSigSwitchedByIgnition" SG_ 1716 VIN_6 0;
BA_ "GenSigStartValue" SG_ 1716 VIN_7 45;
BA_ "GenSigSwitchedByIgnition" SG_ 1716 VIN_7 0;
BA_ "GenSigStartValue" SG_ 1716 VIN_8 45;
BA_ "GenSigSwitchedByIgnition" SG_ 1716 VIN_8 0;
BA_ "GenSigStartValue" SG_ 1716 VIN_9 45;
BA_ "GenSigSwitchedByIgnition" SG_ 1716 VIN_9 0;
BA_ "GenSigSwitchedByIgnition" SG_ 2617196032 XCP_eCall_CRO_01_Data 0;
BA_ "GenSigSwitchedByIgnition" SG_ 2617196033 XCP_eCall_DTO_01_Data 0;
BA_ "GenSigSwitchedByIgnition" SG_ 2616997632 XCP_OTA_FC_CRO_01_Data 0;
BA_ "GenSigSwitchedByIgnition" SG_ 2616997633 XCP_OTA_FC_DTO_01_Data 0;
BA_ "GenSigSendType" SG_ 1411 BCM_FH_Freigabe 3;
BA_ "GenSigSwitchedByIgnition" SG_ 1411 BCM_FH_Freigabe 0;
BA_ "GenSigSendType" SG_ 1411 BCM_HSK_Freigabe 3;
BA_ "GenSigSwitchedByIgnition" SG_ 1411 BCM_HSK_Freigabe 0;
BA_ "GenSigSendType" SG_ 1411 BCM_Komfortfkt_Freigabe 3;
BA_ "GenSigSwitchedByIgnition" SG_ 1411 BCM_Komfortfkt_Freigabe 0;
BA_ "GenSigSendType" SG_ 1411 BCM_Tankklappensteller_Fehler 0;
BA_ "GenSigSwitchedByIgnition" SG_ 1411 BCM_Tankklappensteller_Fehler 0;
BA_ "Fehlerwert" SG_ 1411 BCM_Tankklappensteller_Fehler 1;
BA_ "GenSigSendType" SG_ 1411 BCM_Verdeck_Freigabe 3;
BA_ "GenSigSwitchedByIgnition" SG_ 1411 BCM_Verdeck_Freigabe 0;
BA_ "GenSigSendType" SG_ 1411 DWA_aktiv 3;
BA_ "GenSigSwitchedByIgnition" SG_ 1411 DWA_aktiv 0;
BA_ "GenSigSendType" SG_ 1411 FBS_Warn_Schluessel_Batt 3;
BA_ "GenSigSwitchedByIgnition" SG_ 1411 FBS_Warn_Schluessel_Batt 0;
BA_ "GenSigActiveRepetitions" SG_ 1411 FFB_CarFinder 5;
BA_ "GenSigSendType" SG_ 1411 FFB_CarFinder 2;
BA_ "GenSigSwitchedByIgnition" SG_ 1411 FFB_CarFinder 0;
BA_ "GenSigActiveRepetitions" SG_ 1411 FFB_Komfortoeffnen 5;
BA_ "GenSigSendType" SG_ 1411 FFB_Komfortoeffnen 2;
BA_ "GenSigSwitchedByIgnition" SG_ 1411 FFB_Komfortoeffnen 0;
BA_ "GenSigActiveRepetitions" SG_ 1411 FFB_Komfortschliessen 5;
BA_ "GenSigSendType" SG_ 1411 FFB_Komfortschliessen 2;
BA_ "GenSigSwitchedByIgnition" SG_ 1411 FFB_Komfortschliessen 0;
BA_ "GenSigSendType" SG_ 1411 HBFS_gesafet 3;
BA_ "GenSigSwitchedByIgnition" SG_ 1411 HBFS_gesafet 0;
BA_ "GenSigSendType" SG_ 1411 HBFS_verriegelt 3;
BA_ "GenSigSwitchedByIgnition" SG_ 1411 HBFS_verriegelt 0;
BA_ "GenSigSendType" SG_ 1411 HD_Hauptraste 3;
BA_ "GenSigSwitchedByIgnition" SG_ 1411 HD_Hauptraste 0;
BA_ "GenSigSendType" SG_ 1411 HD_Vorraste 3;
BA_ "GenSigSwitchedByIgnition" SG_ 1411 HD_Vorraste 0;
BA_ "GenSigSendType" SG_ 1411 HFS_gesafet 3;
BA_ "GenSigSwitchedByIgnition" SG_ 1411 HFS_gesafet 0;
BA_ "GenSigSendType" SG_ 1411 HFS_verriegelt 3;
BA_ "GenSigSwitchedByIgnition" SG_ 1411 HFS_verriegelt 0;
BA_ "GenSigSendType" SG_ 1411 IRUE_aktiv 3;
BA_ "GenSigSwitchedByIgnition" SG_ 1411 IRUE_aktiv 0;
BA_ "GenSigSendType" SG_ 1411 IRUE_Taster_Fkts_LED 3;
BA_ "GenSigSwitchedByIgnition" SG_ 1411 IRUE_Taster_Fkts_LED 0;
BA_ "GenSigSendType" SG_ 1411 ZV_BT_offen 3;
BA_ "GenSigSwitchedByIgnition" SG_ 1411 ZV_BT_offen 0;
BA_ "GenSigSendType" SG_ 1411 ZV_Einzeltuerentriegelung 3;
BA_ "GenSigSwitchedByIgnition" SG_ 1411 ZV_Einzeltuerentriegelung 0;
BA_ "GenSigSendType" SG_ 1411 ZV_FT_offen 3;
BA_ "GenSigSwitchedByIgnition" SG_ 1411 ZV_FT_offen 0;
BA_ "GenSigSendType" SG_ 1411 ZV_gesafet_extern_ist 3;
BA_ "GenSigSwitchedByIgnition" SG_ 1411 ZV_gesafet_extern_ist 0;
BA_ "GenSigSendType" SG_ 1411 ZV_gesafet_extern_soll 3;
BA_ "GenSigSwitchedByIgnition" SG_ 1411 ZV_gesafet_extern_soll 0;
BA_ "GenSigSendType" SG_ 1411 ZV_HBFS_offen 3;
BA_ "GenSigSwitchedByIgnition" SG_ 1411 ZV_HBFS_offen 0;
BA_ "GenSigSendType" SG_ 1411 ZV_HD_offen 3;
BA_ "GenSigSwitchedByIgnition" SG_ 1411 ZV_HD_offen 0;
BA_ "GenSigSendType" SG_ 1411 ZV_Heckeinzelentriegelung 3;
BA_ "GenSigSwitchedByIgnition" SG_ 1411 ZV_Heckeinzelentriegelung 0;
BA_ "GenSigSendType" SG_ 1411 ZV_HFS_offen 3;
BA_ "GenSigSwitchedByIgnition" SG_ 1411 ZV_HFS_offen 0;
BA_ "GenSigSendType" SG_ 1411 ZV_HS_offen 3;
BA_ "GenSigSwitchedByIgnition" SG_ 1411 ZV_HS_offen 0;
BA_ "GenSigSendType" SG_ 1411 ZV_ist_Zustand_verfuegbar 3;
BA_ "GenSigSwitchedByIgnition" SG_ 1411 ZV_ist_Zustand_verfuegbar 0;
BA_ "GenSigSendType" SG_ 1411 ZV_Oeffnungsmodus 3;
BA_ "GenSigSwitchedByIgnition" SG_ 1411 ZV_Oeffnungsmodus 0;
BA_ "GenSigSendType" SG_ 1411 ZV_Rollo_auf 3;
BA_ "GenSigSwitchedByIgnition" SG_ 1411 ZV_Rollo_auf 0;
BA_ "GenSigSendType" SG_ 1411 ZV_Rollo_zu 3;
BA_ "GenSigSwitchedByIgnition" SG_ 1411 ZV_Rollo_zu 0;
BA_ "GenSigSendType" SG_ 1411 ZV_SAD_auf 3;
BA_ "GenSigSwitchedByIgnition" SG_ 1411 ZV_SAD_auf 0;
BA_ "GenSigSendType" SG_ 1411 ZV_SAD_zu 3;
BA_ "GenSigSwitchedByIgnition" SG_ 1411 ZV_SAD_zu 0;
BA_ "GenSigSendType" SG_ 1411 ZV_SafeFunktion_aktiv 3;
BA_ "GenSigSwitchedByIgnition" SG_ 1411 ZV_SafeFunktion_aktiv 0;
BA_ "GenSigActiveRepetitions" SG_ 1411 ZV_Schluessel_Zugang 5;
BA_ "GenSigSendType" SG_ 1411 ZV_Schluessel_Zugang 4;
BA_ "GenSigSwitchedByIgnition" SG_ 1411 ZV_Schluessel_Zugang 0;
BA_ "GenSigSendType" SG_ 1411 ZV_Tankklappe_offen 0;
BA_ "GenSigSwitchedByIgnition" SG_ 1411 ZV_Tankklappe_offen 0;
BA_ "GenSigSendType" SG_ 1411 ZV_verriegelt_extern_ist 3;
BA_ "GenSigSwitchedByIgnition" SG_ 1411 ZV_verriegelt_extern_ist 0;
BA_ "GenSigSendType" SG_ 1411 ZV_verriegelt_extern_soll 3;
BA_ "GenSigSwitchedByIgnition" SG_ 1411 ZV_verriegelt_extern_soll 0;
BA_ "GenSigSendType" SG_ 1411 ZV_verriegelt_intern_ist 3;
BA_ "GenSigSwitchedByIgnition" SG_ 1411 ZV_verriegelt_intern_ist 0;
BA_ "GenSigSendType" SG_ 1411 ZV_verriegelt_intern_soll 3;
BA_ "GenSigSwitchedByIgnition" SG_ 1411 ZV_verriegelt_intern_soll 0;
BA_ "GenSigSendType" SG_ 1411 ZV_verriegelt_soll 3;
BA_ "GenSigSwitchedByIgnition" SG_ 1411 ZV_verriegelt_soll 0;
BA_REL_ "GenSigTimeoutTime" BU_SG_REL_ conBox SG_ 1635 BEM_02_Abschaltstufen 1000;
BA_REL_ "GenSigTimeoutTime" BU_SG_REL_ conBox SG_ 1601 MO_Hybridfahrzeug 5000;
BA_REL_ "GenSigTimeoutTime" BU_SG_REL_ conBox SG_ 1601 MO_Kraftstoffart 5000;
BA_REL_ "GenSigTimeoutTime" BU_SG_REL_ conBox SG_ 1156 ND_HDOP 2000;
BA_REL_ "GenSigTimeoutTime" BU_SG_REL_ conBox SG_ 1156 ND_Heading 2000;
BA_REL_ "GenSigTimeoutTime" BU_SG_REL_ conBox SG_ 1156 ND_Init 2000;
BA_REL_ "GenSigTimeoutTime" BU_SG_REL_ conBox SG_ 1157 ND_SatInUse 2000;
BA_REL_ "GenSigTimeoutTime" BU_SG_REL_ conBox SG_ 1157 POS_Guete_horizontal_verfuegbar 2000;
BA_REL_ "GenSigTimeoutTime" BU_SG_REL_ conBox SG_ 1157 POS_Guete_horizontal 2000;
BA_REL_ "GenSigTimeoutTime" BU_SG_REL_ conBox SG_ 1157 NP_Altitude 2000;
BA_REL_ "GenSigTimeoutTime" BU_SG_REL_ conBox SG_ 1157 ND_UTC 2000;
BA_REL_ "GenSigTimeoutTime" BU_SG_REL_ conBox SG_ 1158 NP_Fix 2000;
BA_REL_ "GenSigTimeoutTime" BU_SG_REL_ conBox SG_ 2589283496 POS_MUX 5000;
BA_REL_ "GenSigTimeoutTime" BU_SG_REL_ conBox SG_ 2589283496 POS_ODD_EVEN 5000;
BA_REL_ "GenSigTimeoutTime" BU_SG_REL_ conBox SG_ 2589283496 POS_PosStati 5000;
BA_REL_ "GenSigTimeoutTime" BU_SG_REL_ conBox SG_ 2589283496 POS_Heading 5000;
BA_REL_ "GenSigTimeoutTime" BU_SG_REL_ conBox SG_ 2589283496 POS_LatDirection 5000;
BA_REL_ "GenSigTimeoutTime" BU_SG_REL_ conBox SG_ 2589283496 POS_LatDegree 5000;
BA_REL_ "GenSigTimeoutTime" BU_SG_REL_ conBox SG_ 2589283496 POS_Last_GPS_Sync 5000;
BA_REL_ "GenSigTimeoutTime" BU_SG_REL_ conBox SG_ 2589283496 POS_Heading_Trust 5000;
BA_REL_ "GenSigTimeoutTime" BU_SG_REL_ conBox SG_ 2589283496 POS_UTC_REF 5000;
BA_REL_ "GenSigTimeoutTime" BU_SG_REL_ conBox SG_ 2589283496 POS_LongDirection 5000;
BA_REL_ "GenSigTimeoutTime" BU_SG_REL_ conBox SG_ 2589283496 POS_LongDegree 5000;
BA_REL_ "GenSigTimeoutTime" BU_SG_REL_ conBox SG_ 2600468496 NM_Gateway_SNI 2000;
BA_REL_ "GenSigTimeoutTime" BU_SG_REL_ conBox SG_ 2600468496 NM_Gateway_CBV_CRI 2000;
BA_REL_ "GenSigTimeoutTime" BU_SG_REL_ conBox SG_ 2600468496 NM_Gateway_CAB 2000;
BA_REL_ "GenSigTimeoutTime" BU_SG_REL_ conBox SG_ 2600468489 NM_Sekundaer_09_SNI 2000;
BA_REL_ "GenSigTimeoutTime" BU_SG_REL_ conBox SG_ 2600468489 NM_Sekundaer_09_CBV_CRI 2000;
BA_REL_ "GenSigTimeoutTime" BU_SG_REL_ conBox SG_ 2600468489 NM_Sekundaer_09_CAB 2000;
BA_REL_ "GenSigTimeoutTime" BU_SG_REL_ conBox SG_ 2589283656 ORU_Status 5000;
BA_REL_ "GenSigTimeoutTime" BU_SG_REL_ conBox SG_ 1122 PSD_Strassenkategorie 1500;
BA_REL_ "GenSigTimeoutTime" BU_SG_REL_ conBox SG_ 1527 RW_Reichweite_Einheit_Anzeige 5000;
BA_REL_ "GenSigTimeoutTime" BU_SG_REL_ conBox SG_ 1527 RW_Gesamt_Reichweite_Anzeige 5000;
BA_REL_ "GenSigTimeoutTime" BU_SG_REL_ conBox SG_ 1527 RW_Primaer_Reichweite_Anzeige 5000;
BA_REL_ "GenSigTimeoutTime" BU_SG_REL_ conBox SG_ 1527 RW_Sekundaer_Reichweite_Anzeige 5000;
BA_REL_ "GenSigTimeoutTime" BU_SG_REL_ conBox SG_ 1527 RW_Sekundaer_Reichweite 5000;
BA_REL_ "GenSigTimeoutTime" BU_SG_REL_ conBox SG_ 124 SARA_Omega_X_b_CAN 500;
BA_REL_ "GenSigTimeoutTime" BU_SG_REL_ conBox SG_ 124 SARA_Omega_Y_b_CAN 500;
BA_REL_ "GenSigTimeoutTime" BU_SG_REL_ conBox SG_ 124 SARA_Accel_Z_b_CAN 500;
BA_REL_ "GenSigTimeoutTime" BU_SG_REL_ conBox SG_ 124 SARA_CF_Accel_Z_b_CAN 500;
BA_REL_ "GenSigTimeoutTime" BU_SG_REL_ conBox SG_ 378 SARA_Accel_Y_010_02 500;
BA_REL_ "GenSigTimeoutTime" BU_SG_REL_ conBox SG_ 378 SARA_Accel_X_010_02 500;
BA_REL_ "GenSigTimeoutTime" BU_SG_REL_ conBox SG_ 378 SARA_Omega_Z_010_02 500;
BA_REL_ "GenSigTimeoutTime" BU_SG_REL_ conBox SG_ 378 SARA_CF_Accel_X_010_02 500;
BA_REL_ "GenSigTimeoutTime" BU_SG_REL_ conBox SG_ 378 SARA_CF_Accel_Y_010_02 500;
BA_REL_ "GenSigTimeoutTime" BU_SG_REL_ conBox SG_ 424 SARA_Accel_X_r 500;
BA_REL_ "GenSigTimeoutTime" BU_SG_REL_ conBox SG_ 424 SARA_Accel_Y_r 500;
BA_REL_ "GenSigTimeoutTime" BU_SG_REL_ conBox SG_ 424 SARA_Omega_Z_r 500;
BA_REL_ "GenSigTimeoutTime" BU_SG_REL_ conBox SG_ 424 SARA_CF_Accel_X_r 500;
BA_REL_ "GenSigTimeoutTime" BU_SG_REL_ conBox SG_ 424 SARA_CF_Accel_Y_r 500;
BA_REL_ "GenSigTimeoutTime" BU_SG_REL_ conBox SG_ 424 SARA_CF_Omega_Z_r 500;
BA_REL_ "GenSigTimeoutTime" BU_SG_REL_ conBox SG_ 133 SCU_Ist_Ue_Winkel 500;
BA_REL_ "GenSigTimeoutTime" BU_SG_REL_ conBox SG_ 133 SCU_VZ_Ist_Ue_Winkel 500;
BA_REL_ "GenSigTimeoutTime" BU_SG_REL_ conBox SG_ 2463978662 STS2_01_CRC 2000;
BA_REL_ "GenSigTimeoutTime" BU_SG_REL_ conBox SG_ 2463978662 STS2_01_BZ 2000;
BA_REL_ "GenSigTimeoutTime" BU_SG_REL_ conBox SG_ 2463978662 STS2_Car_not_under_theft 2000;
BA_REL_ "GenSigTimeoutTime" BU_SG_REL_ conBox SG_ 2463978662 STS2_Car_under_theft 2000;
BA_REL_ "GenSigTimeoutTime" BU_SG_REL_ conBox SG_ 2463978662 STS2_Door_Lock 2000;
BA_REL_ "GenSigTimeoutTime" BU_SG_REL_ conBox SG_ 2463978662 STS2_Anlassersperre 2000;
BA_REL_ "GenSigTimeoutTime" BU_SG_REL_ conBox SG_ 2463978662 STS2_Typencodierung 2000;
BA_REL_ "GenSigTimeoutTime" BU_SG_REL_ conBox SG_ 2463978662 STS2_Spiegel_Anklappen 2000;
BA_REL_ "GenSigTimeoutTime" BU_SG_REL_ conBox SG_ 2463978662 STS2_Standlicht 2000;
BA_REL_ "GenSigTimeoutTime" BU_SG_REL_ conBox SG_ 2463978662 STS2_Fahrlicht 2000;
BA_REL_ "GenSigTimeoutTime" BU_SG_REL_ conBox SG_ 2463978662 STS2_Alarm_still 2000;
BA_REL_ "GenSigTimeoutTime" BU_SG_REL_ conBox SG_ 2463978662 STS2_Texte 2000;
BA_REL_ "GenSigTimeoutTime" BU_SG_REL_ conBox SG_ 2463978662 STS2_Laderelais 2000;
BA_REL_ "GenSigTimeoutTime" BU_SG_REL_ conBox SG_ 2463978662 STS2_Summer 2000;
BA_REL_ "GenSigTimeoutTime" BU_SG_REL_ conBox SG_ 2463978662 STS2_Alarm_Blinker 2000;
BA_REL_ "GenSigTimeoutTime" BU_SG_REL_ conBox SG_ 2463978662 STS2_Notstart 2000;
BA_REL_ "GenSigTimeoutTime" BU_SG_REL_ conBox SG_ 2463978662 STS2_Signalhorn 2000;
BA_REL_ "GenSigTimeoutTime" BU_SG_REL_ conBox SG_ 2463978662 STS2_Leerlaufschaltung 2000;
BA_REL_ "GenSigTimeoutTime" BU_SG_REL_ conBox SG_ 1413 SI_QRS_Mode 5000;
BA_REL_ "GenSigTimeoutTime" BU_SG_REL_ conBox SG_ 1413 SI_T_Mode 5000;
BA_REL_ "GenSigTimeoutTime" BU_SG_REL_ conBox SG_ 1413 SI_NWDF 5000;
BA_REL_ "GenSigTimeoutTime" BU_SG_REL_ conBox SG_ 1413 SI_NWDF_gueltig 5000;
BA_REL_ "GenSigTimeoutTime" BU_SG_REL_ conBox SG_ 1413 SI_T_Schutz 5000;
BA_REL_ "GenSigTimeoutTime" BU_SG_REL_ conBox SG_ 1413 SI_BUS_03 5000;
BA_REL_ "GenSigTimeoutTime" BU_SG_REL_ conBox SG_ 1413 SI_BUS_04 5000;
BA_REL_ "GenSigTimeoutTime" BU_SG_REL_ conBox SG_ 1413 SI_BUS_10 5000;
BA_REL_ "GenSigTimeoutTime" BU_SG_REL_ conBox SG_ 1413 SI_BUS_12 5000;
BA_REL_ "GenSigTimeoutTime" BU_SG_REL_ conBox SG_ 1413 SI_BUS_13 5000;
BA_REL_ "GenSigTimeoutTime" BU_SG_REL_ conBox SG_ 1716 VIN_01_MUX 2000;
BA_REL_ "GenSigTimeoutTime" BU_SG_REL_ conBox SG_ 1716 VIN_4 2000;
BA_REL_ "GenSigTimeoutTime" BU_SG_REL_ conBox SG_ 1716 VIN_11 2000;
BA_REL_ "GenSigTimeoutTime" BU_SG_REL_ conBox SG_ 1716 VIN_5 2000;
BA_REL_ "GenSigTimeoutTime" BU_SG_REL_ conBox SG_ 1716 VIN_12 2000;
BA_REL_ "GenSigTimeoutTime" BU_SG_REL_ conBox SG_ 1716 VIN_6 2000;
BA_REL_ "GenSigTimeoutTime" BU_SG_REL_ conBox SG_ 1716 VIN_13 2000;
BA_REL_ "GenSigTimeoutTime" BU_SG_REL_ conBox SG_ 1716 VIN_7 2000;
BA_REL_ "GenSigTimeoutTime" BU_SG_REL_ conBox SG_ 1716 VIN_14 2000;
BA_REL_ "GenSigTimeoutTime" BU_SG_REL_ conBox SG_ 1716 VIN_1 2000;
BA_REL_ "GenSigTimeoutTime" BU_SG_REL_ conBox SG_ 1716 VIN_8 2000;
BA_REL_ "GenSigTimeoutTime" BU_SG_REL_ conBox SG_ 1716 VIN_15 2000;
BA_REL_ "GenSigTimeoutTime" BU_SG_REL_ conBox SG_ 1716 VIN_2 2000;
BA_REL_ "GenSigTimeoutTime" BU_SG_REL_ conBox SG_ 1716 VIN_9 2000;
BA_REL_ "GenSigTimeoutTime" BU_SG_REL_ conBox SG_ 1716 VIN_16 2000;
BA_REL_ "GenSigTimeoutTime" BU_SG_REL_ conBox SG_ 1716 VIN_3 2000;
BA_REL_ "GenSigTimeoutTime" BU_SG_REL_ conBox SG_ 1716 VIN_10 2000;
BA_REL_ "GenSigTimeoutTime" BU_SG_REL_ conBox SG_ 1716 VIN_17 2000;
BA_REL_ "GenSigTimeoutTime" BU_SG_REL_ conBox SG_ 1411 DWA_aktiv 2000;
BA_REL_ "GenSigTimeoutTime" BU_SG_REL_ Gateway SG_ 2600468489 NM_Sekundaer_09_SNI 2000;
BA_REL_ "GenSigTimeoutTime" BU_SG_REL_ Gateway SG_ 2600468489 NM_Sekundaer_09_CBV_CRI 2000;
BA_REL_ "GenSigTimeoutTime" BU_SG_REL_ Gateway SG_ 2600468489 NM_Sekundaer_09_CAB 2000;
BA_REL_ "GenSigTimeoutTime" BU_SG_REL_ Gateway SG_ 2600468720 NM_Sekundaer_F0_SNI 2000;
BA_REL_ "GenSigTimeoutTime" BU_SG_REL_ Gateway SG_ 2600468720 NM_Sekundaer_F0_CBV_AWB 2000;
BA_REL_ "GenSigTimeoutTime" BU_SG_REL_ Gateway SG_ 2600468720 NM_Sekundaer_F0_CBV_CRI 2000;
BA_REL_ "GenSigTimeoutTime" BU_SG_REL_ Gateway SG_ 2600468720 NM_Sekundaer_F0_NM_State 2000;
BA_REL_ "GenSigTimeoutTime" BU_SG_REL_ Gateway SG_ 2600468720 NM_Sekundaer_F0_CAB 2000;
BA_REL_ "GenSigTimeoutTime" BU_SG_REL_ Gateway SG_ 2527679670 ORU_EM_Anfrage_Flashdauer 5000;
BA_REL_ "GenSigTimeoutTime" BU_SG_REL_ Gateway SG_ 2527679670 ORU_EM_Anfrage_freigegebeneNetze 5000;
BA_REL_ "GenSigTimeoutTime" BU_SG_REL_ Gateway SG_ 2527679670 ORU_EM_Anfrage_Stromaufnahme 5000;
BA_REL_ "GenSigTimeoutTime" BU_SG_REL_ Gateway SG_ 2527679670 ORU_Status_Anf 5000;
BA_REL_ "GenSigTimeoutTime" BU_SG_REL_ Gateway_PAG SG_ 2600468489 NM_Sekundaer_09_SNI 2000;
BA_REL_ "GenSigTimeoutTime" BU_SG_REL_ Gateway_PAG SG_ 2600468489 NM_Sekundaer_09_CBV_CRI 2000;
BA_REL_ "GenSigTimeoutTime" BU_SG_REL_ Gateway_PAG SG_ 2600468489 NM_Sekundaer_09_CAB 2000;
BA_REL_ "GenSigTimeoutTime" BU_SG_REL_ Gateway_PAG SG_ 2600468720 NM_Sekundaer_F0_SNI 2000;
BA_REL_ "GenSigTimeoutTime" BU_SG_REL_ Gateway_PAG SG_ 2600468720 NM_Sekundaer_F0_CBV_AWB 2000;
BA_REL_ "GenSigTimeoutTime" BU_SG_REL_ Gateway_PAG SG_ 2600468720 NM_Sekundaer_F0_CBV_CRI 2000;
BA_REL_ "GenSigTimeoutTime" BU_SG_REL_ Gateway_PAG SG_ 2600468720 NM_Sekundaer_F0_CAB 2000;
BA_REL_ "GenSigTimeoutTime" BU_SG_REL_ Gateway_PAG SG_ 2527679670 ORU_EM_Anfrage_Flashdauer 5000;
BA_REL_ "GenSigTimeoutTime" BU_SG_REL_ Gateway_PAG SG_ 2527679670 ORU_EM_Anfrage_freigegebeneNetze 5000;
BA_REL_ "GenSigTimeoutTime" BU_SG_REL_ Gateway_PAG SG_ 2527679670 ORU_EM_Anfrage_Stromaufnahme 5000;
BA_REL_ "GenSigTimeoutTime" BU_SG_REL_ Gateway_PAG SG_ 2527679670 ORU_Status_Anf 5000;
BA_REL_ "GenSigTimeoutTime" BU_SG_REL_ OTA_FC SG_ 2600468496 NM_Gateway_SNI 2000;
BA_REL_ "GenSigTimeoutTime" BU_SG_REL_ OTA_FC SG_ 2600468496 NM_Gateway_CBV_CRI 2000;
BA_REL_ "GenSigTimeoutTime" BU_SG_REL_ OTA_FC SG_ 2600468496 NM_Gateway_CAB 2000;
BA_REL_ "GenSigTimeoutTime" BU_SG_REL_ OTA_FC SG_ 2600468720 NM_Sekundaer_F0_SNI 2000;
BA_REL_ "GenSigTimeoutTime" BU_SG_REL_ OTA_FC SG_ 2600468720 NM_Sekundaer_F0_CBV_CRI 2000;
BA_REL_ "GenSigTimeoutTime" BU_SG_REL_ OTA_FC SG_ 2600468720 NM_Sekundaer_F0_CAB 2000;
BA_REL_ "GenSigTimeoutTime" BU_SG_REL_ OTA_FC SG_ 2589283656 ORU_Status 5000;
BA_REL_ "GenSigTimeoutTime" BU_SG_REL_ OTA_FC SG_ 1527 RW_Tendenz 5000;
BA_REL_ "GenSigTimeoutTime" BU_SG_REL_ OTA_FC SG_ 1527 RW_Reservewarnung_aktiv 5000;
BA_REL_ "GenSigTimeoutTime" BU_SG_REL_ OTA_FC SG_ 1527 RW_Gesamt_Reichweite_Anzeige 5000;
BA_REL_ "GenSigTimeoutTime" BU_SG_REL_ OTA_FC SG_ 1527 RW_Primaer_Reichweite_Anzeige 5000;
BA_REL_ "GenSigTimeoutTime" BU_SG_REL_ OTA_FC SG_ 1527 RW_Sekundaer_Reichweite_Anzeige 5000;
BA_REL_ "GenSigTimeoutTime" BU_SG_REL_ OTA_FC SG_ 1527 RW_Sekundaer_Reichweite 5000;
BA_REL_ "GenSigTimeoutTime" BU_SG_REL_ OTA_FC SG_ 1527 RW_Sek_Reichweitenverbrauch 5000;
BA_REL_ "GenSigTimeoutTime" BU_SG_REL_ OTA_FC SG_ 1413 SI_Sammel_SG_Fehler 5000;
BA_REL_ "GenSigTimeoutTime" BU_SG_REL_ OTA_FC SG_ 1413 SI_QRS_Mode 5000;
BA_REL_ "GenSigTimeoutTime" BU_SG_REL_ OTA_FC SG_ 1413 SI_T_Mode 5000;
BA_REL_ "GenSigTimeoutTime" BU_SG_REL_ OTA_FC SG_ 1413 SI_NWDF 5000;
BA_REL_ "GenSigTimeoutTime" BU_SG_REL_ OTA_FC SG_ 1413 SI_NWDF_gueltig 5000;
BA_REL_ "GenSigTimeoutTime" BU_SG_REL_ OTA_FC SG_ 1413 SI_Sammelfehler 5000;
BA_REL_ "GenSigTimeoutTime" BU_SG_REL_ OTA_FC SG_ 1413 SI_T_Schutz 5000;
BA_REL_ "GenSigTimeoutTime" BU_SG_REL_ OTA_FC SG_ 1413 SI_Bus_Identifikation 5000;
BA_REL_ "GenSigTimeoutTime" BU_SG_REL_ OTA_FC SG_ 1413 SI_CAB 5000;
VAL_ 1601 MO_Faktor_Momente_02 0 "nicht_belegt" ;
VAL_ 1601 MO_Hybridfahrzeug 0 "kein_Hybridfahrzeug" 1 "Mild_Hybrid" 2 "Full_Hybrid" 3 "PlugIn_Hybrid" ;
VAL_ 1601 MO_Getriebe_Code 0 "Init" 2 "DL501" 3 "DL800" 4 "VL381" 5 "DL382_Front" 6 "DL382_Allrad" 7 "DL702" 8 "AL552_Allrad" 9 "AL552_Front" 10 "AL651" 11 "AL551__AL951__AL1000_8A" 12 "PDK_PAG" 13 "AL551_Hybrid" 15 "Handschalter_konventionell" 16 "AQ250_160" 17 "AQ450" 18 "DQ200" 19 "DQ250" 20 "DQ500" 21 "SQ100" 22 "SQ200" 23 "DQ400E" 24 "DQ381" 25 "AL550" 26 "AQ300" 31 "DL800E" 32 "Single_Gear__ohne_GSG_WH_am_MSG" 33 "EQ550_2P" ;
VAL_ 1601 MO_StartStopp_Codiert 0 "Start_Stopp_nicht_verbaut" 1 "Start_Stopp_verbaut" ;
VAL_ 1601 MO_Anzeige_StSt_gueltig 0 "MO_Text_Motorstart_gueltig" 1 "Signale_MO_Anzeige_StSt_gueltig" ;
VAL_ 1601 MO_Anzahl_Zyl 0 "kein_Zylinder" 1 "1_Zylinder" 2 "2_Zylinder" 3 "3_Zylinder" 4 "4_Zylinder" 5 "5_Zylinder" 6 "6_Zylinder" 7 "7_Zylinder" 8 "8_Zylinder" 9 "9_Zylinder" 10 "10_Zylinder" 11 "11_Zylinder" 12 "12_Zylinder" 13 "15_Zylinder" 14 "16_Zylinder" 15 "18_Zylinder" ;
VAL_ 1601 MO_Kraftstoffart 0 "Diesel" 1 "Benzin_inkl_E25_E85" 2 "CNG" 3 "LPG" 4 "Wasserstoff" 5 "E100_Ethanol" 15 "kein_Verbrennungskraftstoff" ;
VAL_ 1601 MO_Ansaugsystem 0 "Turbo" 1 "Sauger" ;
VAL_ 1601 MO_OBD_Typ 0 "NoOBD_RdW" 1 "EOBD" 2 "US_OBD" 3 "reserviert" ;
VAL_ 1601 MO_DPF_verbaut 0 "kein_DPF_verbaut" 1 "DPF_verbaut" ;
VAL_ 1601 TSK_Codierung 0 "kein_Fahrgeschwindigkeitsregler" 1 "GRA" 2 "GRA_Plus" 3 "Basis_ACC" 4 "ACC_Follow_to_Stop" 5 "ACC_Stop_and_Go" 7 "Codierung_in_Plausibilisierungsphase" ;
VAL_ 1156 ND_VDOP 1022 "Init" 1023 "Fehler" ;
VAL_ 1156 ND_TDOP 1022 "Init" 1023 "Fehler" ;
VAL_ 1156 ND_HDOP 1022 "Init" 1023 "Fehler" ;
VAL_ 1156 ND_GDOP 1022 "Init" 1023 "Fehler" ;
VAL_ 1156 ND_PDOP 1022 "Init" 1023 "Fehler" ;
VAL_ 1156 ND_Heading 4094 "Init" 4095 "Fehler" ;
VAL_ 1156 ND_Init 0 "nicht_Initialisiert" 1 "Initialisiert" ;
VAL_ 1157 ND_SatInUse 30 "Init" 31 "Fehler" ;
VAL_ 1157 POS_Guete_horizontal_verfuegbar 0 "nicht_verfuegbar" 1 "verfuegbar" ;
VAL_ 1157 ND_SatInView 30 "Init" 31 "Fehler" ;
VAL_ 1157 POS_Guete_horizontal 124 "von_248m_bis_400m" 125 "mehr_als_400m" 126 "Init" 127 "Fehler" ;
VAL_ 1157 NP_Altitude 4094 "Init" 4095 "Fehler" ;
VAL_ 1158 NP_LatDegree 134217726 "Init" 134217727 "Fehler" ;
VAL_ 1158 NP_LongDegree 268435454 "Init" 268435455 "Fehler" ;
VAL_ 1158 NP_LatDirection 0 "Nord" 1 "Sued" ;
VAL_ 1158 NP_LongDirection 0 "Ost" 1 "West" ;
VAL_ 1158 NP_Sat 30 "Init" 31 "Fehler" ;
VAL_ 1158 NP_Fix 0 "Init" 1 "No_Fix" 2 "2D_Fix" 3 "3D_Fix" ;
VAL_ 2589283496 POS_MUX 0 "MUX_0" 1 "MUX_1" 2 "reserved" 3 "Init" ;
VAL_ 2589283496 POS_ODD_EVEN 0 "ODD" 1 "EVEN" ;
VAL_ 2589283496 POS_PosStati 0 "Init" 1 "NoNavAvailable" 2 "NoMapAvailable" 3 "NavBooting" 4 "NavError" 5 "NavCalibrating" 6 "NavNoGpsResyncSince1h" 7 "NavOffroadParkgarageRampOffset2" 8 "DeadReckoningWithoutGps" 9 "DeadReckoningWithGps" 10 "MapMatchedLowConfidence" 11 "MapMatchedLimitedConfidence" 12 "OffroadHighConfidence" 13 "MapMatchedHighConfidence" 14 "PosInSyncWithGpsAndMAP" ;
VAL_ 2589283496 POS_LatDirection 0 "North" 1 "South" ;
VAL_ 2589283496 POS_LatDegree 134217726 "Init" 134217727 "Fehler" ;
VAL_ 2589283496 POS_Heading_Trust 0 "Init" 1 "TrustLevel01" 2 "TrustLevel02" 3 "Fehler" ;
VAL_ 2589283496 POS_LongDirection 0 "East" 1 "West" ;
VAL_ 2589283496 POS_LongDegree 268435454 "Init" 268435455 "Fehler" ;
VAL_ 2600468496 NM_Gateway_SNI 16 "Gateway" ;
VAL_ 2600468496 NM_Gateway_CBV_AWB 0 "Passiver_WakeUp" 1 "Aktiver_WakeUp" ;
VAL_ 2600468496 NM_Gateway_CBV_CRI 0 "NM_ohne_Clusteranforderungen" 1 "NM_mit_Clusteranforderungen" ;
VAL_ 2600468496 NM_Gateway_NM_State 0 "Init" 1 "NM_RM_aus_BSM" 2 "NM_RM_aus_PBSM" 4 "NM_NO_aus_RM" 8 "NM_NO_aus_RS" 16 "reserved" 32 "reserved" ;
VAL_ 2600468496 NM_Gateway_Car_Wakeup 0 "Inaktiv" 1 "Car_Wakeup" ;
VAL_ 2600468496 NM_Gateway_UDS_CC 0 "Inaktiv" 1 "CC_aktiv" ;
VAL_ 2600468496 NM_Gateway_NM_aktiv_KL15 0 "Inaktiv" 1 "KL15_EIN" ;
VAL_ 2600468496 NM_Gateway_NM_aktiv_Diagnose 0 "Init" 1 "Diagnose_aktiv" ;
VAL_ 2600468496 NM_Gateway_NM_aktiv_Tmin 0 "Inaktiv" 1 "Mindestaktivzeit" ;
VAL_ 2600468496 NM_Gateway_NM_aktiv_CWU 0 "kein_CWU_gesetzt" 1 "CWU_gesetzt" ;
VAL_ 2600468496 NM_Gateway_NM_aktiv_FC 0 "kein_FC_gesetzt" 1 "FC_gesetzt" ;
VAL_ 2600468496 NM_Gateway_NM_aktiv_Connect 0 "inaktiv" 1 "Nachlauf_aufgrund_Connect" ;
VAL_ 2600468496 NM_Gateway_NM_aktiv_EM 0 "inaktiv" 1 "Nachlauf_aufgrund_Energiemanagement" ;
VAL_ 2600468496 NM_Gateway_NM_aktiv_OBDC 0 "kein_Nachlauf" 1 "Nachlauf_aufgrund_OBDC" ;
VAL_ 2600468496 NM_Gateway_NM_aktiv_Buskopplung 0 "inaktiv" 1 "Nachlauf_aufgrund_Buskopplung" ;
VAL_ 2600468496 NM_Gateway_NM_aktiv_LIN2 0 "Inaktiv" 1 "LIN2_aktiv" ;
VAL_ 2600468496 NM_Gateway_NM_aktiv_Fremdladung 0 "inaktiv" 1 "Nachlauf_aufgrund_Connect" ;
VAL_ 2600468496 NM_Gateway_CAB 0 "inaktiv" 1 "CAB_01__Tueren" 2 "CAB_02__Anhaenger_KCAN" 4 "CAB_03__Nightvision" 8 "CAB_04__Sitzverstellung" 16 "CAB_05__Klappen" 32 "CAB_06__Infotainment" 64 "CAB_07__Sub_Infotainment" 128 "CAB_08__Anzeige" 256 "CAB_09__Laden_HCAN" 512 "CAB_10__Klima" 1024 "CAB_11__FlexRay" 262144 "CAB_19__VLAN_RemoteFC" 524288 "CAB_20__VLAN_Komfort" 1048576 "CAB_21__VLAN_Internet" 2097152 "CAB_22__VLAN_Connect" 4194304 "CAB_23__VLAN_Infotainment" 8388608 "CAB_24__VLAN_FAS" ;
VAL_ 2600468489 NM_Sekundaer_09_SNI 9 "Sekundaer_09" ;
VAL_ 2600468489 NM_Sekundaer_09_CBV_AWB 0 "Passiver_WakeUp" 1 "Aktiver_WakeUp" ;
VAL_ 2600468489 NM_Sekundaer_09_CBV_CRI 0 "Standard_Layout" 1 "TNB_Layout" ;
VAL_ 2600468489 NM_Sekundaer_09_NM_State 0 "Init" 1 "NM_RM_aus_BSM" 2 "NM_RM_aus_PBSM" 4 "NM_NO_aus_RM" 8 "NM_NO_aus_RS" ;
VAL_ 2600468489 NM_Sekundaer_09_Car_Wakeup 0 "Inaktiv" 1 "Car_Wakeup" ;
VAL_ 2600468489 NM_Sekundaer_09_UDS_CC 0 "CC_inaktiv" 1 "CC_aktiv" ;
VAL_ 2600468489 NM_Sekundaer_09_NM_aktiv_KL15 0 "Inaktiv" 1 "KL15_EIN" ;
VAL_ 2600468489 NM_Sekundaer_09_NM_aktiv_Diag 0 "Inaktiv" 1 "Diagnose_aktiv" ;
VAL_ 2600468489 NM_Sekundaer_09_NM_aktiv_Tmin 0 "Inaktiv" 1 "Mindestaktivzeit" ;
VAL_ 2600468489 NM_Sekundaer_09_NM_aktiv_BaseFct 0 "Init" 1 "Backend_Kommunikation_aktiv" ;
VAL_ 2600468489 NM_Sekundaer_09_NM_aktiv_MOD 0 "Init" 1 "Anforderung_durch_MOD" ;
VAL_ 2600468489 NM_Sekundaer_09_NM_aktiv_RmtDiag 0 "Init" 1 "Anforderung_durch_RemoteDiagnose" ;
VAL_ 2600468489 NM_Sekundaer_09_NM_aktiv_RmtFcts 0 "Init" 1 "Anforderung_durch_RemoteFunction" ;
VAL_ 2600468489 NM_Sekundaer_09_NM_aktiv_RmtUpdt 0 "Init" 1 "Anforderung_durch_RemoteUpdate" ;
VAL_ 2600468489 NM_Sekundaer_09_NM_aktiv_Backend 0 "Init" 1 "Backend_Kommunikation_aktiv" ;
VAL_ 2600468489 NM_Sekundaer_09_CAB 0 "inaktiv" 1 "CAB_01__Tueren" 2 "CAB_02__Anhaenger_KCAN" 4 "CAB_03__Nightvision" 8 "CAB_04__Sitzverstellung" 16 "CAB_05__Klappen" 32 "CAB_06__Infotainment" 64 "CAB_07__Sub_Infotainment" 128 "CAB_08__Anzeige" 256 "CAB_09__Laden_HCAN" 512 "CAB_10__Klima" 1024 "CAB_11__FlexRay" 262144 "CAB_19__VLAN_RemoteFC" 524288 "CAB_20__VLAN_Komfort" 1048576 "CAB_21__VLAN_Internet" 2097152 "CAB_22__VLAN_Connect" 4194304 "CAB_23__VLAN_Infotainment" 8388608 "CAB_24__VLAN_FAS" ;
VAL_ 2600468720 NM_Sekundaer_F0_SNI 240 "Sekundaer_F0" ;
VAL_ 2600468720 NM_Sekundaer_F0_CBV_AWB 0 "Passiver_WakeUp" 1 "Aktiver_WakeUp" ;
VAL_ 2600468720 NM_Sekundaer_F0_CBV_CRI 0 "Standard_Layout" 1 "TNB_Layout" ;
VAL_ 2600468720 NM_Sekundaer_F0_NM_State 0 "Inaktiv" 1 "NM_RM_aus_BSM" 2 "NM_RM_aus_PBSM" 4 "NM_NO_aus_RM" 8 "NM_NO_aus_RS" 16 "NM_RM_aus_NO" 32 "NM_RM_aus_RS" ;
VAL_ 2600468720 NM_Sekundaer_F0_Car_Wakeup 0 "Inaktiv" 1 "Car_Wakeup" ;
VAL_ 2600468720 NM_Sekundaer_F0_UDS_CC 0 "Inaktiv" 1 "CC_aktiv" ;
VAL_ 2600468720 NM_Sekundaer_F0_NM_aktiv_KL15 0 "Inaktiv" 1 "KL15_EIN" ;
VAL_ 2600468720 NM_Sekundaer_F0_NM_aktiv_Diag 0 "Inaktiv" 1 "Diagnose_aktiv" ;
VAL_ 2600468720 NM_Sekundaer_F0_NM_aktiv_Tmin 0 "Inaktiv" 1 "Mindestaktivzeit" ;
VAL_ 2600468720 NM_Sekundaer_F0_NM_aktiv_eCall 0 "Inaktiv" 1 "eCall_aktiv" ;
VAL_ 2600468720 NM_Sekundaer_F0_NM_aktiv_Eth_Kom 0 "Inaktiv" 1 "Ethernet_Verbindungsaufbau_aktiv" ;
VAL_ 2600468720 NM_Sekundaer_F0_NM_aktiv_VTS 0 "Inaktiv" 1 "VTS_Aktiv" ;
VAL_ 2600468720 NM_Sekundaer_F0_NM_aktiv_Timer 0 "Inaktiv" 1 "Ubertragung_Timerwechsel" ;
VAL_ 2600468720 NM_Sekundaer_F0_NM_aktiv_BTKey 0 "Inaktiv" 1 "Key_per_BT_empfangen" ;
VAL_ 2600468720 NM_Sekundaer_F0_CAB 0 "inaktiv" 1 "CAB_01__Tueren" 2 "CAB_02__Anhaenger_KCAN" 4 "CAB_03__Nightvision" 8 "CAB_04__Sitzverstellung" 16 "CAB_05__Klappen" 32 "CAB_06__Infotainment" 64 "CAB_07__Sub_Infotainment" 128 "CAB_08__Anzeige" 256 "CAB_09__Laden_HCAN" 512 "CAB_10__Klima" 1024 "CAB_11__FlexRay" 262144 "CAB_19__VLAN_RemoteFC" 524288 "CAB_20__VLAN_Komfort" 1048576 "CAB_21__VLAN_Internet" 2097152 "CAB_22__VLAN_Connect" 4194304 "CAB_23__VLAN_Infotainment" 8388608 "CAB_24__VLAN_FAS" ;
VAL_ 1635 BEM_02_Abschaltstufen 0 "Stufe 0 (keine Einschraenkungen)" 1 "Stufe 1" 2 "Stufe 2" 3 "Stufe 3" 4 "Transportmodus" 7 "Ruhestrommessmodus" ;
VAL_ 1635 BEM_STH_Zielzeit 14 "Init" 15 "Fehler" ;
VAL_ 1635 BEM_MMI_Vorwarnung 0 "keine Anzeige" 1 "Anzeige MMI-Vorwarnung" ;
VAL_ 1635 NVEM_Anf_SD_schalten 0 "Anf_SD_Nachlauf_nicht_aktiv" 1 "Anf_SD_Nachlauf_aktiv" ;
VAL_ 1635 BEM_Generatordiagnose 0 "keine Anzeige" 1 "Ladekontrollanzeige ein (Vorhalt)" 2 "rotes Batteriesymbol und Text (Generator defekt)" 3 "Hybrid_DCDC_Wandler_defekt" ;
VAL_ 1635 BEM_Red_Innengeblaese 0 "keine Reduzierung" 1 "Reduzierung Stufe 1" 2 "Reduzierung Stufe 2" 3 "Reduzierung Stufe 2 und Abschaltung Kompressor" ;
VAL_ 1635 BEM_STH_Einschaltverbot 0 "volle Verfuegbarkeit Standheizung/-lueftung" 1 "Standheizung/-lueftung nicht aktivierbar" ;
VAL_ 1635 BEM_HL_Regelung_Status 0 "HL_Regelung_inaktiv_(vor_und_waehrend_Motorstart)" 1 "HL_Regelung_Stufe_1" 2 "HL_Regelung_Stufe_2" 3 "HL_Regelung_Stufe_3" 4 "Verbrauchernotabschaltung_(VNA)" 5 "HL_Regelung_Stufe_5" 7 "Default" ;
VAL_ 1635 BEM_Ladezustand 14 "Init" 15 "Fehler" ;
VAL_ 1635 BEM_Batteriediagnose 0 "keine_Anzeige" 1 "nicht_belegt" 2 "Anzeige_aberkannte_Batterie" 3 "Anzeige_schwache_Batterie" 4 "Anzeige_Batterie_OK" 5 "Anzeige_Batterie_Laden" 6 "Anzeige_Batterie_Pruefen" 7 "Fehler" ;
VAL_ 1635 MIB_Stromsparmodus 0 "inaktiv" 1 "aktiv" ;
VAL_ 1635 BEM_REK_aktiv 0 "keine_Rekuperationsfreigabe" 1 "Rekuperationsfreigabe" ;
VAL_ 1635 NVEM_Last_Anf 0 "keine Anforderung" 1 "Verbraucher_Anforderung_Stufe_1" 2 "Verbraucher_Anforderung_Stufe_2" 3 "Verbraucher_Anforderung_Stufe_3" ;
VAL_ 1635 BEM_UBDM 0 "Init" 255 "Fehler" ;
VAL_ 1635 BEM_Anf_KL15_schalten 0 "Keine_Einschraenkung_Kl15" 1 "Empfehlung_auto_Abschaltung_Kl15" 2 "Veto_auto_Abschaltung_Kl15" 3 "Veto_auto_Abschaltung_Fahrtbetrieb" ;
VAL_ 1635 NVEM_Batterie_Service 0 "kein_Service" 1 "Service_Information1" 2 "Service_Information2" 3 "Service_Information3" ;
VAL_ 1635 NVEM_Freigabe_OnlineUpdate 0 "keine_Freigabe" 1 "Freigabe" ;
VAL_ 1635 NVEM_Freigabe_ORU4 0 "Init" 1 "keine_Freigabe" 2 "Freigabe_erteilt" 3 "Veto_Freigabe" ;
VAL_ 2589283656 ORU_Warnung 0 "keine_Anzeige" 1 "Update_unvollstaendig_Prio1" 2 "Update_fehlgeschlagen_Prio1" 3 "reserviert" ;
VAL_ 2589283656 ORU_Status 0 "IDLE" 1 "PENDING" 2 "PREPARATION" 3 "PREPARATION_HV" 4 "RUNNING" 5 "RUNNING_HV" 6 "PENDING_NOTREADY" 7 "FAILURE_POWERTRAIN_DISABLED" ;
VAL_ 2527679670 OTA_FC_Hinweis_Update 0 "inaktiv" 1 "aktiv" ;
VAL_ 2527679670 OTA_FC_PredMaint_Ausfall 0 "inaktiv" 1 "aktiv" ;
VAL_ 2527679670 OTA_FC_Warnung_Update 0 "inaktiv" 1 "aktiv" ;
VAL_ 2527679670 OTA_FC_IOF_Ausfall 0 "inaktiv" 1 "aktiv" ;
VAL_ 2527679670 OTA_FC_FoD_Stornierung 0 "inaktiv" 1 "aktiv" ;
VAL_ 2527679670 OTA_FC_FahrwerkAnf 0 "KeineOTAFCAnf_Fahrwerk" 1 "OTAFCAnf_FahrwerkNormal" 2 "OTAFCAnf_FahrwerkSport" 3 "OTAFCAnf_FahrwerkSportPlus" ;
VAL_ 2527679670 OTA_FC_LiftAnf 0 "KeineOTAFCAnf_Lift" 1 "OTAFCAnf_Lift" ;
VAL_ 2527679670 OTA_FC_NiveauAnf 0 "KeineOTAFCAnf_Niveau" 1 "OTAFCAnf_NiveauSGN" 2 "OTAFCAnf_NiveauGN" 3 "OTAFCAnf_NiveauNN" 4 "OTAFCAnf_NiveauTN" 5 "OTAFCAnf_NiveauBN" ;
VAL_ 2527679670 ORU_EM_Anfrage_freigegebeneNetze 0 "only_12V" 1 "networks_48V_and_12V" 2 "networks_HV_and_12V" 3 "networks_HV_and_48V_and_12V" ;
VAL_ 2527679670 ORU_Status_Anf 0 "IDLE" 1 "PENDING" 2 "PREPARATION" 3 "PREPARATION_HV" 4 "RUNNING" 5 "RUNNING_HV" 6 "PENDING_NOTREADY" ;
VAL_ 2463978757 PSO_last_rec_UserID_Src2 0 "Init" 1 "BCM_UserID_1" 2 "BCM_UserID_2" 3 "BCM_UserID_3" 4 "BCM_UserID_4" 5 "BCM_UserID_5" 6 "BCM_UserID_6" 7 "BCM_UserID_7" 8 "BCM_UserID_8" 9 "BCM_UserID_9" 10 "BCM_UserID_10" 11 "BCM_UserID_11" 12 "BCM_UserID_12" 13 "BCM_UserID_13" 14 "BCM_UserID_14" 15 "BCM_UserID_15" ;
VAL_ 1122 PSD_Segment_ID 0 "keine Segmentinformationen vorhanden" 1 "Fehlerwert" ;
VAL_ 1122 PSD_Vorgaenger_Segment_ID 0 "keine Segmentinformation vorhanden" 1 "Fehlerwert" ;
VAL_ 1122 PSD_Strassenkategorie 0 "Rest_Feldweg_Schotterweg_Privatweg" 1 "Ortsstraße" 2 "Kreisstraße" 3 "Landstraße" 4 "Bundesstraße" 5 "Autobahn" 7 "Init" ;
VAL_ 1122 PSD_Endkruemmung 255 "Gerade" ;
VAL_ 1122 PSD_Endkruemmung_Vorz 0 "Kruemmung_positiv" 1 "Kruemmung_negativ" ;
VAL_ 1122 PSD_Idenditaets_ID 0 "keine_Segment_Informationen_vorhanden" 1 "Fehler" ;
VAL_ 1122 PSD_ADAS_Qualitaet 0 "keine_ADAS_Qualitaet" 1 "ADAS_Qualitaet" ;
VAL_ 1122 PSD_wahrscheinlichster_Pfad 0 "Pfad_mit_geringer_Wahrscheinlichkeit" 1 "wahrscheinlichster_Pfad" ;
VAL_ 1122 PSD_Geradester_Pfad 0 "nicht_geradester_PFad" 1 "geradester_Pfad" ;
VAL_ 1122 PSD_Fahrspuren_Anzahl 0 "Einbahnstrasse_in_falsche_Richtung" 1 "eine_Fahrspur" 2 "zwei_Fahrspuren" 3 "drei_Fahrspuren" 4 "vier_Fahrspuren" 5 "fuenf_Fahrspuren" 6 "sechs_Fahrspuren" 7 "mehr_als_sechs_Fahrspuren" ;
VAL_ 1122 PSD_Bebauung 0 "ausserhalb_bebauten_Gebietes" 1 "innerhalb_bebauten_Gebietes" ;
VAL_ 1122 PSD_Segment_Komplett 0 "Segment_Attribute_nicht_komplett" 1 "Segment_Attribute_komplett" ;
VAL_ 1122 PSD_Rampe 0 "Strasse_mit_Gegenverkehr" 1 "Auffahrt_Einbahnstr" 2 "Abfahrt_Einbahnstr" 3 "Einbahnstrasse" ;
VAL_ 1122 PSD_Anfangskruemmung 255 "Gerade" ;
VAL_ 1122 PSD_Anfangskruemmung_Vorz 0 "positiv" 1 "negativ" ;
VAL_ 1122 PSD_Abzweigerichtung 0 "rects_abzweigende_Strasse" 1 "links_abzweigende_Strasse" ;
VAL_ 1527 RW_Tendenz 0 "keine_Tendenz" 1 "konstant" 2 "steigend" 3 "sinkend" ;
VAL_ 1527 RW_Texte 0 "kein_Text" 1 "Text_1" 2 "Text_2" 3 "Text_3" ;
VAL_ 1527 RW_Reservewarnung_aktiv 0 "inaktiv" 1 "aktiv" ;
VAL_ 1527 RW_Reichweite_Einheit_Anzeige 0 "km" 1 "miles" ;
VAL_ 1527 RW_Gesamt_Reichweite_Anzeige 2045 "nicht_verbaut" 2046 "Init" 2047 "Fehler" ;
VAL_ 1527 RW_Primaer_Reichweite_Anzeige 2045 "nicht_verbaut" 2046 "Init" 2047 "Fehler" ;
VAL_ 1527 RW_Sekundaer_Reichweite_Anzeige 2045 "nicht_verbaut" 2046 "Init" 2047 "Fehler" ;
VAL_ 1527 RW_Sekundaer_Reichweite 2045 "nicht_verbaut" 2046 "Init" 2047 "Fehler" ;
VAL_ 1527 RW_Sek_Reichweitenv_Einheit 0 "Liter_pro_100km" 1 "kWh_pro_100km" 2 "Kg_pro_100km" 3 "nicht_verbaut" ;
VAL_ 1527 RW_Sek_Reichweitenverbrauch 2047 "Init" ;
VAL_ 124 SARA_Omega_X_b_CAN 0 "nicht_verbaut" 65535 "Fehler" ;
VAL_ 124 SARA_Omega_Y_b_CAN 0 "nicht_verbaut" 65535 "Fehler" ;
VAL_ 124 SARA_Accel_Z_b_CAN 0 "nicht_verbaut" 65535 "Fehler" ;
VAL_ 124 SARA_CF_Omega_X_b_CAN 0 "gueltiger_Wert" 1 "nicht_belegt" 2 "nicht_belegt" 3 "temporaerer_Fehler" 4 "Init" 5 "Sensor_nicht_verbaut_Signal_nicht_berrechnet" 6 "Sensor_nicht_abgeglichen" 7 "Sensor_defekt" ;
VAL_ 124 SARA_CF_Omega_Y_b_CAN 0 "gueltiger_Wert" 1 "nicht_belegt" 2 "nicht_belegt" 3 "temporaerer_Fehler" 4 "Init" 5 "Sensor_nicht_verbaut_Signal_nicht_berrechnet" 6 "Sensor_nicht_abgeglichen" 7 "Sensor_defekt" ;
VAL_ 124 SARA_CF_Accel_Z_b_CAN 0 "gueltiger_Wert" 1 "nicht_belegt" 2 "nicht_belegt" 3 "temporaerer_Fehler" 4 "Init" 5 "Sensor_nicht_verbaut_Signal_nicht_berrechnet" 6 "Sensor_nicht_abgeglichen" 7 "Sensor_defekt" ;
VAL_ 378 SARA_Accel_Y_010_02 0 "nicht_verbaut" 65535 "Fehler" ;
VAL_ 378 SARA_Accel_X_010_02 0 "nicht_verbaut" 65535 "Fehler" ;
VAL_ 378 SARA_Omega_Z_010_02 0 "nicht_verbaut" 65535 "Fehler" ;
VAL_ 378 SARA_CF_Accel_X_010_02 0 "gueltiger_Wert" 1 "nicht_belegt" 2 "nicht_belegt" 3 "temporaerer_Fehler" 4 "Init" 5 "Sensor_nicht_verbaut_Signal_nicht_berrechnet" 6 "Sensor_nicht_abgeglichen" 7 "Sensor_defekt" ;
VAL_ 378 SARA_CF_Accel_Y_010_02 0 "gueltiger_Wert" 1 "nicht_belegt" 2 "nicht_belegt" 3 "temporaerer_Fehler" 4 "Init" 5 "Sensor_nicht_verbaut_Signal_nicht_berrechnet" 6 "Sensor_nicht_abgeglichen" 7 "Sensor_defekt" ;
VAL_ 378 SARA_CF_Omega_Z_010_02 0 "gueltiger_Wert" 1 "nicht_belegt" 2 "nicht_belegt" 3 "temporaerer_Fehler" 4 "Init" 5 "Sensor_nicht_verbaut_Signal_nicht_berrechnet" 6 "Sensor_nicht_abgeglichen" 7 "Sensor_defekt" ;
VAL_ 424 SARA_Accel_X_r 0 "nicht_verbaut" 8191 "Fehler" ;
VAL_ 424 SARA_Accel_Y_r 0 "nicht_verbaut" 8191 "Fehler" ;
VAL_ 424 SARA_Omega_Z_r 0 "nicht_verbaut" 8191 "Fehler" ;
VAL_ 424 SARA_CF_Accel_X_r 0 "gueltiger_Wert" 1 "nicht_belegt" 2 "nicht_belegt" 3 "temporaerer_Fehler" 4 "Init" 5 "Sensor_nicht_verbaut_Signal_nicht_berrechnet" 6 "Sensor_nicht_abgeglichen" 7 "Sensor_defekt" ;
VAL_ 424 SARA_CF_Accel_Y_r 0 "gueltiger_Wert" 1 "nicht_belegt" 2 "nicht_belegt" 3 "temporaerer_Fehler" 4 "Init" 5 "Sensor_nicht_verbaut_Signal_nicht_berrechnet" 6 "Sensor_nicht_abgeglichen" 7 "Sensor_defekt" ;
VAL_ 424 SARA_CF_Omega_Z_r 0 "gueltiger_Wert" 1 "nicht_belegt" 2 "nicht_belegt" 3 "temporaerer_Fehler" 4 "Init" 5 "Sensor_nicht_verbaut_Signal_nicht_berrechnet" 6 "Sensor_nicht_abgeglichen" 7 "Sensor_defekt" ;
VAL_ 133 SCU_Ist_Ue_Winkel 4094 "Init" 4095 "Fehler" ;
VAL_ 133 SCU_VZ_Ist_Ue_Winkel 0 "positiv" 1 "negativ" ;
VAL_ 133 SCU_Soll_Ue_Winkel 2046 "Init" 2047 "Fehler" ;
VAL_ 133 SCU_max_Gradient 511 "Fehler" ;
VAL_ 133 SCU_VZ_Soll_Ue_Winkel 0 "positiv" 1 "negativ" ;
VAL_ 133 SCU_Status 0 "betriebsbereit" 1 "Init" 2 "sichere Übersetzung" 3 "Motorsperre verriegelt" 4 "Synchronisierung läuft" ;
VAL_ 133 SCU_Winkelbegrenzung 0 "nicht_aktiv" 1 "Lenkwinkelbegrenzung_aktiv" ;
VAL_ 133 SCU_Sensorstatus 0 "iO" 1 "Kalibrierung_aktiv" ;
VAL_ 133 SCU_IL_Leistungsreserve 254 "Init" 255 "Fehler" ;
VAL_ 2589283634 SM_LAPP_Demo_Objekt_01_Anf 0 "nicht_angefordert" 1 "angefordert" ;
VAL_ 2589283634 SM_LAPP_Demo_Objekt_02_Anf 0 "nicht_angefordert" 1 "angefordert" ;
VAL_ 2589283634 SM_LAPP_Demo_Autobahnmodus_Anf 0 "nicht_angefordert" 1 "angefordert" ;
VAL_ 2589283634 SM_LAPP_Aussenlicht_aktiv 0 "inaktiv" 1 "aktiv" ;
VAL_ 2589283634 SM_LAPP_Verbindungsstatus 0 "nicht_angefordert" 1 "angefordert" ;
VAL_ 2589283634 SM_LAPP_Demo_Schildentbl_01_Anf 0 "nicht_angefordert" 1 "angefordert" ;
VAL_ 2589283634 SM_LAPP_Demo_Schildentbl_02_Anf 0 "nicht_angefordert" 1 "angefordert" ;
VAL_ 2589283634 SM_LAPP_Demo_DKL_Anf 0 "nicht_angefordert" 1 "angefordert" ;
VAL_ 2589283634 SM_LAPP_Demo_Einschalteffekt_Anf 0 "nicht_angefordert" 1 "angefordert" ;
VAL_ 2589283634 SM_LAPP_Demo_FL_Anf 0 "nicht_angefordert" 1 "angefordert" ;
VAL_ 2589283634 SM_LAPP_Demo_MaLi_Anf 0 "nicht_angefordert" 1 "angefordert" ;
VAL_ 2589283634 SM_LAPP_Demo_ABBL_Anf 0 "nicht_angefordert" 1 "angefordert" ;
VAL_ 2527679657 SM_LAPP_Demo_AbsAss_Anf 0 "nicht_angefordert" 1 "angefordert" ;
VAL_ 2527679657 SM_LAPP_Demo_SL_Signatur_Anf 0 "Init" 1 "Signatur_1" 2 "Signatur_2" 3 "Signatur_3" 4 "Signatur_4" 5 "Signatur_5" 6 "Signatur_6" 7 "Signatur_7" 8 "Signatur_8" 9 "Signatur_9" 10 "Signatur_10" 11 "Signatur_11" 12 "Signatur_12" 13 "Signatur_13" 14 "Signatur_14" 15 "Signatur_15" ;
VAL_ 2527679657 SM_LAPP_Demo_Variante 0 "Variante_0" 1 "Variante_1" 2 "Variante_2" 3 "Variante_3" 4 "Variante_4" 5 "Variante_5" ;
VAL_ 2527679657 SM_LAPP_Demo_RouLi_Anf 0 "nicht_angefordert" 1 "angefordert" ;
VAL_ 2527679657 SM_LAPP_Demo_PreSAss_Anf 0 "nicht_angefordert" 1 "angefordert" ;
VAL_ 2527679657 SM_LAPP_Demo_advLH_F01_Anf 0 "nicht_angefordert" 1 "angefordert" ;
VAL_ 2527679657 SM_LAPP_Demo_AbbiegeWa_Anf 0 "nicht_angefordert" 1 "angefordert" ;
VAL_ 2527679657 SM_LAPP_Demo_CH_H01_Anf 0 "nicht_angefordert" 1 "angefordert" ;
VAL_ 2527679657 SM_LAPP_Demo_Stufe 0 "Stufe_0" 1 "Stufe_1" 2 "Stufe_2" 3 "Stufe_3" ;
VAL_ 2527679657 SM_LAPP_Demo_SL_Anf 0 "nicht_angefordert" 1 "angefordert" ;
VAL_ 2527679657 SM_LAPP_Demo_SitLi_Anf 0 "nicht_angefordert" 1 "angefordert" ;
VAL_ 2527679657 SM_LAPP_Demo_BauLi_Anf 0 "nicht_angefordert" 1 "angefordert" ;
VAL_ 2527679657 SM_LAPP_Demo_advCH_F01_Anf 0 "nicht_angefordert" 1 "angefordert" ;
VAL_ 2527679657 SM_LAPP_Demo_LH_F01_Anf 0 "nicht_angefordert" ;
VAL_ 2527679657 SM_LAPP_Demo_AccAss_Anf 0 "nicht_angefordert" 1 "angefordert" ;
VAL_ 2527679657 SM_LAPP_Demo_SpuLi_Anf 0 "nicht_angefordert" 1 "angefordert" ;
VAL_ 2527679657 SM_LAPP_Demo_TraLi_Anf 0 "nicht_angefordert" 1 "angefordert" ;
VAL_ 2527679657 SM_LAPP_Demo_CH_F01_Anf 0 "nicht_angefordert" ;
VAL_ 2527679657 SM_LAPP_Demo_LH_H01_Anf 0 "nicht_angefordert" 1 "angefordert" ;
VAL_ 2527679657 SM_LAPP_Demo_EffAss_Anf 0 "nicht_angefordert" 1 "angefordert" ;
VAL_ 2527679657 SM_LAPP_Demo_BeAss_Anf 0 "nicht_angefordert" 1 "angefordert" ;
VAL_ 2463978662 STS2_Car_not_under_theft 0 "false" 1 "true" ;
VAL_ 2463978662 STS2_Car_under_theft 0 "false" 1 "true" ;
VAL_ 2463978662 STS2_Door_Lock 0 "Init" 1 "door_lock" ;
VAL_ 2463978662 STS2_Anlassersperre 0 "inaktiv" 1 "aktiv" ;
VAL_ 2463978662 STS2_Typencodierung 0 "Basis" 1 "E-Gas" 4 "Sonderschutz" ;
VAL_ 2463978662 STS2_Spiegel_Anklappen 0 "Init" 1 "Spiegel_anklappen" ;
VAL_ 2463978662 STS2_Privatsphaere 0 "inaktiv" 1 "aktiv" ;
VAL_ 2463978662 STS2_Standlicht 0 "inaktiv" 1 "aktiv" ;
VAL_ 2463978662 STS2_Fahrlicht 0 "inaktiv" 1 "aktiv" ;
VAL_ 2463978662 STS2_Alarm_still 0 "inaktiv" 1 "aktiv" ;
VAL_ 2463978662 STS2_Texte 0 "kein_Text" 1 "Text_01" 2 "Text_02" 3 "Text_03" 4 "Text_04" 5 "Text_05" 6 "Text_06" 7 "Text_07" 8 "Text_08" 9 "Text_09" 10 "Text_10" 11 "Text_11" 12 "Text_12" 13 "Text_13" 14 "Init" 15 "Fehler" ;
VAL_ 2463978662 STS2_Laderelais 0 "Relais_offen" 1 "Relais_geschlossen" ;
VAL_ 2463978662 STS2_Summer 0 "inaktiv" 1 "aktiv" ;
VAL_ 2463978662 STS2_Alarm_Blinker 0 "inaktiv" 1 "aktiv" ;
VAL_ 2463978662 STS2_Notstart 0 "kein_Notstart" 1 "Notstart" ;
VAL_ 2463978662 STS2_Signalhorn 0 "inaktiv" 1 "aktiv" ;
VAL_ 2463978662 STS2_Leerlaufschaltung 0 "Leerlaufschaltung_Aus" 1 "Leerlaufschaltung_Ein" ;
VAL_ 1172 STS_Car_not_under_theft 0 "false" 1 "true" ;
VAL_ 1172 STS_Car_under_theft 0 "false" 1 "true" ;
VAL_ 1172 STS_Door_Lock 0 "Init" 1 "door_lock" ;
VAL_ 1172 STS_Anlassersperre 0 "inaktiv" 1 "aktiv" ;
VAL_ 1172 STS_Typencodierung 0 "Basis" 1 "E-Gas" 4 "Sonderschutz" ;
VAL_ 1172 STS_Spiegel_Anklappen 0 "Init" 1 "Spiegel_anklappen" ;
VAL_ 1172 GW_STS2_Privatsphaere 0 "Aus" 1 "Ein" ;
VAL_ 1172 STS_Standlicht 0 "inaktiv" 1 "aktiv" ;
VAL_ 1172 STS_Fahrlicht 0 "inaktiv" 1 "aktiv" ;
VAL_ 1172 STS_Alarm_still 0 "inaktiv" 1 "aktiv" ;
VAL_ 1172 STS_Texte 0 "kein_Text" 1 "Text_01" 2 "Text_02" 3 "Text_03" 4 "Text_04" 5 "Text_05" 6 "Text_06" 7 "Text_07" 8 "Text_08" 9 "Text_09" 10 "Text_10" 11 "Text_11" 12 "Text_12" 13 "Text_13" 14 "Init" 15 "Fehler" ;
VAL_ 1172 STS_Laderelais 0 "Relais_offen" 1 "Relais_geschlossen" ;
VAL_ 1172 STS_Summer 0 "inaktiv" 1 "aktiv" ;
VAL_ 1172 STS_Alarm_Blinker 0 "Init" ;
VAL_ 1172 STS_Notstart 0 "kein_Notstart" 1 "Notstart" ;
VAL_ 1172 STS_Signalhorn 0 "inaktiv" 1 "aktiv" ;
VAL_ 1172 STS_Leerlaufschaltung 0 "inaktiv" 1 "aktiv" ;
VAL_ 1413 SI_Sammel_SG_Fehler 61 "Reserviert" 62 "Overflow" 63 "ungueltig" ;
VAL_ 1413 SI_Diagnose_Aktiv 0 "inaktiv" 1 "aktiv" ;
VAL_ 1413 SI_QRS_Mode 0 "QRS_Messmodus_nicht_aktiv" 1 "QRS_Messmodus_aktiv" ;
VAL_ 1413 SI_T_Mode 0 "Transportmodus_nicht_aktiv" 1 "Transportmodus_aktiv" ;
VAL_ 1413 SI_NWDF 0 "Ueberwachung_nicht_freigegeben" 1 "Ueberwachung_freigegeben" ;
VAL_ 1413 SI_NWDF_gueltig 0 "NWDF_wird_nicht_unterstuetzt" 1 "NWDF_wird_unterstuetzt" ;
VAL_ 1413 SI_Sammelfehler 0 "kein_Sammelfehler" 1 "Sammelfehler" ;
VAL_ 1413 GW_KD_Fehler 0 "kein_KD_Fehler" 1 "KD_Fehler" ;
VAL_ 1413 SI_T_Schutz 0 "Transportschutz_nicht_aktiv" 1 "Transportschutz_aktiv" ;
VAL_ 1413 SI_BUS_01 0 "keine_Busruhe" 1 "Busruhe" ;
VAL_ 1413 SI_BUS_02 0 "keine_Busruhe" 1 "Busruhe" ;
VAL_ 1413 SI_BUS_03 0 "keine_Busruhe" 1 "Busruhe" ;
VAL_ 1413 SI_BUS_04 0 "keine_Busruhe" 1 "Busruhe" ;
VAL_ 1413 SI_BUS_05 0 "keine_Busruhe" 1 "Busruhe" ;
VAL_ 1413 SI_BUS_06 0 "keine_Busruhe" 1 "Busruhe" ;
VAL_ 1413 SI_BUS_07 0 "keine_Busruhe" 1 "Busruhe" ;
VAL_ 1413 SI_BUS_08 0 "keine_Busruhe" 1 "Busruhe" ;
VAL_ 1413 SI_BUS_09 0 "keine_Busruhe" 1 "Busruhe" ;
VAL_ 1413 SI_BUS_10 0 "keine_Busruhe" 1 "Busruhe" ;
VAL_ 1413 SI_BUS_11 0 "keine_Busruhe" 1 "Busruhe" ;
VAL_ 1413 SI_BUS_12 0 "keine_Busruhe" 1 "Busruhe" ;
VAL_ 1413 SI_BUS_13 0 "keine_Busruhe" 1 "Busruhe" ;
VAL_ 1413 SI_BUS_14 0 "keine_Busruhe" 1 "Busruhe" ;
VAL_ 1413 SI_BUS_15 0 "keine_Busruhe" 1 "Busruhe" ;
VAL_ 1413 SI_Bus_Identifikation 16 "CAN_Diagnose" 17 "CAN_Antrieb" 18 "CAN_Komfort" 19 "CAN_Infotainment" 20 "CAN_Fahrwerk" 21 "CAN_Extended" 22 "CAN_Hybrid" 23 "CAN_Lade" 24 "CAN_Kombi" 25 "CAN_Komfort_2" 26 "CAN_AFS" 27 "CAN_MIB" 33 "CAN_FahrerAssistenzSysteme" 34 "CAN_Migration" 35 "CAN_Connect" 36 "CAN_AnzeigeBedienung" 37 "CAN_ElectricalVehicle" 40 "CAN_Telematik" 41 "CAN_MFL" 42 "CAN_FahrerAssistenzSysteme_2" 47 "CAN_Komfort_3" 48 "FlexRay_A" 49 "FlexRay_B" 97 "VLAN_FAS" 98 "VLAN_Infotainment" 99 "VLAN_Connect" 100 "VLAN_Komfort" 101 "VLAN_Antrieb" 102 "VLAN_Diagnose" 103 "VLAN_Internet" 104 "VLAN_Gateway" 105 "VLAN_Remote_FC" 106 "VLAN_Connect_2" 107 "VLAN_Licht" 108 "VLAN_Charge" 109 "VLAN_Cockpit" 176 "HCP1_CANFD01" 177 "HCP1_CANFD02" 178 "HCP1_CANFD03" 179 "HCP1_CANFD04" 180 "HCP1_CANFD05" 181 "HCP1_CANFD06" 182 "HCP1_CANFD07" 183 "HCP1_CANFD08" 186 "HCP4_CANFD03" 187 "HCP4_CANFD04" 188 "HCP1_CANFD09" 189 "HCP4_CANFD06" 190 "HCP4_CANFD07" 191 "HCP4_CANFD08" 192 "HCP4_CANFD09" 193 "HCP4_CANFD10" 194 "HCP1_CANFD10" 195 "ICAS1_CANFD2_HCP5_CANFD02" 196 "HCP1_CANFD11" 197 "WU_HCP1_CANFD" 199 "WU_HCP2_CANFD" 200 "WU_HCP3_CANFD" 201 "WU_HCP4_CANFD" 202 "HCP3_CANFD02" 204 "ESC_CANFD" 205 "HCP4_CANFD11" 206 "HCP4_CANFD12" 207 "HCP5_CANFD04" 208 "HCP5_CANFD05" 212 "WU_ConMod_CANFD" 213 "WU_PASD_CANFD" 215 "CAN_MobileDeviceKey" ;
VAL_ 1413 SI_CAB 0 "inaktiv" 1 "CAB_01__Tueren" 2 "CAB_02__Anhaenger" 4 "CAB_03__Nightvision" 8 "CAB_04__Sitzverstellung" 16 "CAB_05__Klappen" 32 "CAB_06__Infotainment" 64 "CAB_07__Sub_Infotainment" 128 "CAB_08__Anzeige" 256 "CAB_09__Laden" 512 "CAB_10__Klima" 1024 "CAB_11__FlexRay" 262144 "CAB_19_VLAN_Remote_FC" 524288 "CAB_20_VLAN_Komfort" 1048576 "CAB_21_VLAN_Internet" 2097152 "CAB_22_VLAN_Connect" 4194304 "CAB_23_VLAN_Infotainment" 8388608 "CAB_24_VLAN_FAS" ;
VAL_ 1411 BCM_FH_Freigabe 1 "Funktionsfreigabe Fensterheber" ;
VAL_ 1411 BCM_Komfortfkt_Freigabe 0 "Komfortfunktion gesperrt" 1 "globale Freigabe der Komfortfunktion erteilt" ;
VAL_ 1411 BCM_HSK_Freigabe 0 "erlauben" 1 "sperren" ;
VAL_ 1411 BCM_Verdeck_Freigabe 0 "Verdeckbetrieb nicht erlaubt" 1 "Verdeckbetrieb erlaubt" ;
VAL_ 1411 ZV_verriegelt_intern_ist 1 "Fahrzeug innen verriegelt; Istzustand" ;
VAL_ 1411 ZV_verriegelt_extern_ist 1 "Fahrzeug_aussen_verriegelt_Istzustand" ;
VAL_ 1411 ZV_verriegelt_intern_soll 1 "Fahrzeug verriegelt intern; Sollzusstand" ;
VAL_ 1411 ZV_verriegelt_extern_soll 1 "Fahrzeug verriegelt extern; Sollzusstand" ;
VAL_ 1411 ZV_gesafet_extern_ist 1 "Fahrzeug aussen gesafet; Istzustand" ;
VAL_ 1411 ZV_gesafet_extern_soll 1 "Fahrzeug_aussen_gesafet_Sollzustand" ;
VAL_ 1411 ZV_Einzeltuerentriegelung 1 "Fahrzeug an Einzeltuer entriegelt" ;
VAL_ 1411 ZV_Heckeinzelentriegelung 1 "Heckdeckeleinzelentriegelung" ;
VAL_ 1411 ZV_FT_offen 0 "FT_geschlossen" 1 "FT_geoeffnet" ;
VAL_ 1411 ZV_BT_offen 0 "BT_geschlossen" 1 "BT_geoeffnet" ;
VAL_ 1411 ZV_HFS_offen 0 "geschlossen" 1 "offen" ;
VAL_ 1411 ZV_HBFS_offen 0 "geschlossen" 1 "offen" ;
VAL_ 1411 ZV_HD_offen 1 "Heckdeckel_auf" ;
VAL_ 1411 ZV_HS_offen 0 "Heckscheibe_geschlossen" 1 "Heckscheibe auf" ;
VAL_ 1411 IRUE_aktiv 0 "unscharf" 1 "scharf" ;
VAL_ 1411 DWA_aktiv 0 "unscharf" 1 "scharf" ;
VAL_ 1411 HD_Hauptraste 0 "geschlossen" 1 "offen" ;
VAL_ 1411 HD_Vorraste 0 "geschlossen" 1 "offen" ;
VAL_ 1411 FFB_CarFinder 0 "nicht aktiv" 1 "aktiv" ;
VAL_ 1411 FFB_Komfortoeffnen 0 "kein_Komfortoeffnen_empfangen" 1 "Komfortoeffnen ueber Funk empfangen" ;
VAL_ 1411 FFB_Komfortschliessen 0 "kein_Komfortschliessen_empfangen" 1 "Komfortschliessen ueber Funk empfangen" ;
VAL_ 1411 ZV_Schluessel_Zugang 0 "kein_auth_Schluessel_erkannt" 1 "aktive_Funkschluessel_Nr_01" 2 "aktive_Funkschluessel_Nr_02" 3 "aktive_Funkschluessel_Nr_03" 4 "aktive_Funkschluessel_Nr_04" 5 "aktive_Funkschluessel_Nr_05" 6 "aktive_Funkschluessel_Nr_06" 7 "aktive_Funkschluessel_Nr_07" 8 "aktive_Funkschluessel_Nr_08" 9 "aktive_SmartDevice_Nr_09" 10 "ungueltig_10" 11 "ungueltig_11" 12 "ungueltig_12" 13 "ungueltig_13" 14 "ungueltig_14" 15 "ungueltig_15" ;
VAL_ 1411 ZV_SafeFunktion_aktiv 0 "inaktiv" 1 "aktiv" ;
VAL_ 1411 FBS_Warn_Schluessel_Batt 0 "i.O." 1 "defekt" ;
VAL_ 1411 ZV_Oeffnungsmodus 0 "globale_Oeffnung" 1 "ZV_mit_Einzeltuerentr" 2 "ZV_individuell_selektiv" 3 "ZV_seitenselektiv" ;
VAL_ 1411 HFS_verriegelt 0 "nicht_verriegelt" 1 "verriegelt" ;
VAL_ 1411 HFS_gesafet 0 "nicht_gesafet" 1 "gesafet" ;
VAL_ 1411 HBFS_verriegelt 0 "nicht_verriegelt" 1 "verriegelt" ;
VAL_ 1411 HBFS_gesafet 0 "nicht_gesafet" 1 "gesafet" ;
VAL_ 1411 ZV_ist_Zustand_verfuegbar 0 "nicht_verfuegbar" 1 "verfuegbar_alle_TSGs_am_Bus" ;
VAL_ 1411 IRUE_Taster_Fkts_LED 0 "LED_aus" 1 "LED_ein" ;
VAL_ 1411 ZV_Tankklappe_offen 0 "Tankklappe_geschlossen" 1 "Tankklappe_offen" ;
VAL_ 1411 ZV_Rollo_auf 0 "inaktiv" 1 "aktiv" ;
VAL_ 1411 ZV_Rollo_zu 0 "inaktiv" 1 "aktiv" ;
VAL_ 1411 ZV_SAD_auf 0 "inaktiv" 1 "aktiv" ;
VAL_ 1411 ZV_SAD_zu 0 "inaktiv" 1 "aktiv" ;
VAL_ 1411 BCM_Tankklappensteller_Fehler 0 "kein_Fehler" 1 "Fehler" ;
VAL_ 1411 ZV_verriegelt_soll 0 "Init" 1 "nicht_verriegelt" 2 "verriegelt" ;
